VERSION ""

NS_ :

BS_:

BU_: CHUD_LS VKM_LS RCRM_LS MSM_RR_LS MSM_LR_LS CGM_LS BSM_LS VPM_LS ISRVM_LS DCAC_LS TouchPad_LS RSC_LS LVMPC_LS EOCM2B_K1_LS EOCM2A_K1_LS LCM_LS TIM_B_LS V2V_LS TCP_LS CSM_LS EOCM2B_K2_LS EOCM2A_K2_LS TIM_A_LS LVMNav_LS HFP_LS EDI_LS ARB_LS RSE_LS Dummy_LS VIS2_LS ICS_LS FCM_LS EOCM_F_LS VICM_LS AGC_LS MSM_P_LS OTIM_LS HVSM_R_LS HVSM_F_LS DVB_T_LS SBZA_R_LS PSD_R_LS PSD_L_LS UHP_Low UPA_LS STC_LS SBZA_L_LS PTM_LS ONSTAR_LS APA_LS TestTool_LS PHS_LS PDIM_LS CHM_LS RSA_LS AMP_LS HUD_LS MSM_LS HBSM_LS SCL_LS ECC_LS RadioHead_LS PEPS_LS IPC_LS AOS_LS SDM_LS TIM_LS BCM_LS

BO_ 168 Temp_Diag_CAN_Req_LS_0A8: 8 CGM_LS
 SG_ DgnInf : 7|64@0+ (1,0) [0|1.84467440737096E+019] ""  Dummy_LS

BO_ 128 Temp_Diag_CAN_Req_LS_080: 8 Dummy_LS
 SG_ DgnInf : 7|64@0+ (1,0) [0|1.84467440737096E+019] ""  CGM_LS

BO_ 896 Temp_Diag_CAN_Resp_LS_380: 8 CGM_LS
 SG_ DgnInf : 7|64@0+ (1,0) [0|1.84467440737096E+019] ""  CGM_LS,Dummy_LS

BO_ 153 Temp_Diag_CAN_Req_LS_099: 8 CGM_LS
 SG_ DgnInf : 7|64@0+ (1,0) [0|1.84467440737096E+019] ""  Dummy_LS

BO_ 1825 VNMF_LS_721_EOCM2B_K1: 8 EOCM2B_K1_LS
 SG_ VectraSpcNWMgtD : 7|64@0+ (1,0) [0|1.84467440737096E+019] ""  CGM_LS,Dummy_LS

BO_ 1824 VNMF_LS_720_EOCM2A_K1: 8 EOCM2A_K1_LS
 SG_ VectraSpcNWMgtD : 7|64@0+ (1,0) [0|1.84467440737096E+019] ""  CGM_LS,Dummy_LS

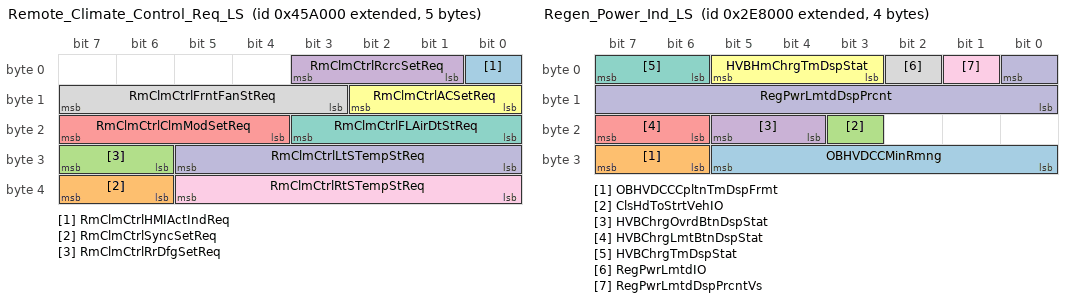
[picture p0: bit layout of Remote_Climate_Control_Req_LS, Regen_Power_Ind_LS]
BO_ 2152046592 Remote_Climate_Control_Req_LS: 5 ONSTAR_LS
 SG_ RmClmCtrlHMIActIndReq : 0|1@0+ (1,0) [0|1] ""  ECC_LS
 SG_ RmClmCtrlSyncSetReq : 39|2@0+ (1,0) [0|3] ""  ECC_LS
 SG_ RmClmCtrlRrDfgSetReq : 31|2@0+ (1,0) [0|3] ""  ECC_LS
 SG_ RmClmCtrlRcrcSetReq : 3|3@0+ (1,0) [0|7] ""  ECC_LS
 SG_ RmClmCtrlClmModSetReq : 23|4@0+ (1,0) [0|15] ""  ECC_LS
 SG_ RmClmCtrlACSetReq : 10|3@0+ (1,0) [0|7] ""  ECC_LS
 SG_ RmClmCtrlFLAirDtStReq : 19|4@0+ (1,0) [0|15] ""  ECC_LS
 SG_ RmClmCtrlFrntFanStReq : 15|5@0+ (1,0) [0|31] ""  ECC_LS
 SG_ RmClmCtrlRtSTempStReq : 37|6@0+ (1,0) [0|63] ""  ECC_LS
 SG_ RmClmCtrlLtSTempStReq : 29|6@0+ (1,0) [0|63] ""  ECC_LS

BO_ 2152030208 Tuner_Frequency_Request_LS: 8 ONSTAR_LS
 SG_ TnrFrqChnlReq : 15|56@0+ (1,0) [0|1] ""  CGM_LS,CSM_LS,RadioHead_LS
 SG_ TnrFrqBndReq : 3|4@0+ (1,0) [0|15] ""  CGM_LS,CSM_LS,RadioHead_LS

BO_ 2150531072 Regen_Power_Ind_LS: 4 VICM_LS
 SG_ OBHVDCCMinRmng : 29|6@0+ (1,0) [0|63] ""  CGM_LS,IPC_LS,RadioHead_LS
 SG_ OBHVDCCCpltnTmDspFrmt : 31|2@0+ (1,0) [0|3] ""  IPC_LS,CGM_LS,RadioHead_LS
 SG_ ClsHdToStrtVehIO : 19|1@0+ (1,0) [0|1] ""  CGM_LS,IPC_LS
 SG_ HVBChrgOvrdBtnDspStat : 21|2@0+ (1,0) [0|3] ""  CGM_LS,CSM_LS,RadioHead_LS
 SG_ HVBChrgLmtBtnDspStat : 23|2@0+ (1,0) [0|3] ""  CGM_LS,CSM_LS,RadioHead_LS
 SG_ HVBHmChrgTmDspStat : 5|3@0+ (1,0) [0|7] ""  CGM_LS,CSM_LS,RadioHead_LS
 SG_ HVBChrgTmDspStat : 7|2@0+ (1,0) [0|3] ""  CGM_LS,CSM_LS,RadioHead_LS
 SG_ RegPwrLmtdIO : 2|1@0+ (1,0) [0|1] ""  CGM_LS,IPC_LS
 SG_ RegPwrLmtdDspPrcntVs : 1|1@0+ (1,0) [0|1] ""  CGM_LS,IPC_LS
 SG_ RegPwrLmtdDspPrcnt : 0|9@0- (0.392157,0) [-100.392192|100.000035] "%"  CGM_LS,IPC_LS

BO_ 2151833600 Heated_Wndshild_CstmrIhbt_Req_LS: 1 BCM_LS
 SG_ HtdFrntWSDispReq : 7|2@0+ (1,0) [0|3] ""  CGM_LS,ECC_LS
 SG_ HtdFrntWSCustRqIhbt : 5|1@0+ (1,0) [0|1] ""  CGM_LS,ECC_LS

BO_ 2151817216 Heated_Wndshild_Cstmr_Req_LS: 1 ECC_LS
 SG_ HtdFrntWSCustRq : 7|1@0+ (1,0) [0|1] ""  CGM_LS,BCM_LS

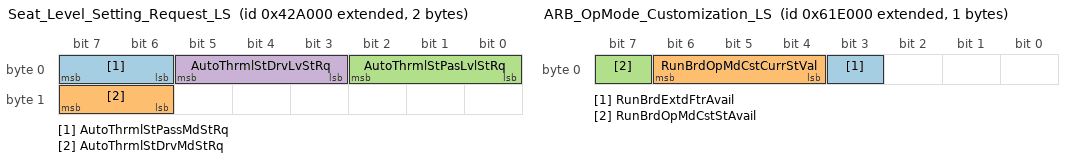
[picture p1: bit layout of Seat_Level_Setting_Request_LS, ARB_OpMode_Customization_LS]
BO_ 2151849984 Seat_Level_Setting_Request_LS: 2 ECC_LS
 SG_ AutoThrmlStPassMdStRq : 7|2@0+ (1,0) [0|3] ""  CGM_LS,BCM_LS
 SG_ AutoThrmlStDrvMdStRq : 15|2@0+ (1,0) [0|3] ""  CGM_LS,BCM_LS
 SG_ AutoThrmlStPasLvlStRq : 2|3@0+ (1,0) [0|7] ""  CGM_LS,BCM_LS
 SG_ AutoThrmlStDrvLvStRq : 5|3@0+ (1,0) [0|7] ""  CGM_LS,BCM_LS

BO_ 2153897984 ARB_OpMode_Customization_LS: 1 ARB_LS
 SG_ RunBrdExtdFtrAvail : 3|1@0+ (1,0) [0|1] ""  CGM_LS,CSM_LS,RadioHead_LS
 SG_ RunBrdOpMdCstCurrStVal : 6|3@0+ (1,0) [0|7] ""  CGM_LS,CSM_LS,RadioHead_LS
 SG_ RunBrdOpMdCstStAvail : 7|1@0+ (1,0) [0|1] ""  CGM_LS,CSM_LS,RadioHead_LS

BO_ 936 Temp_Diag_CAN_Resp_LS_3A8: 8 Dummy_LS
 SG_ DgnInf : 7|64@0+ (1,0) [0|1.84467440737096E+019] ""  CGM_LS

BO_ 856 Temp_Diag_CAN_Resp_LS_358: 8 Dummy_LS
 SG_ DgnInf : 7|64@0+ (1,0) [0|1.84467440737096E+019] ""  CGM_LS

BO_ 872 Temp_Diag_CAN_Resp_LS_368: 8 Dummy_LS
 SG_ DgnInf : 7|64@0+ (1,0) [0|1.84467440737096E+019] ""  CGM_LS

BO_ 864 Temp_Diag_CAN_Resp_LS_360: 8 CGM_LS
 SG_ DgnInf : 7|64@0+ (1,0) [0|1.84467440737096E+019] ""  CGM_LS,Dummy_LS

BO_ 921 Temp_Diag_CAN_Resp_LS_399: 8 Dummy_LS
 SG_ DgnInf : 7|64@0+ (1,0) [0|1.84467440737096E+019] ""  CGM_LS

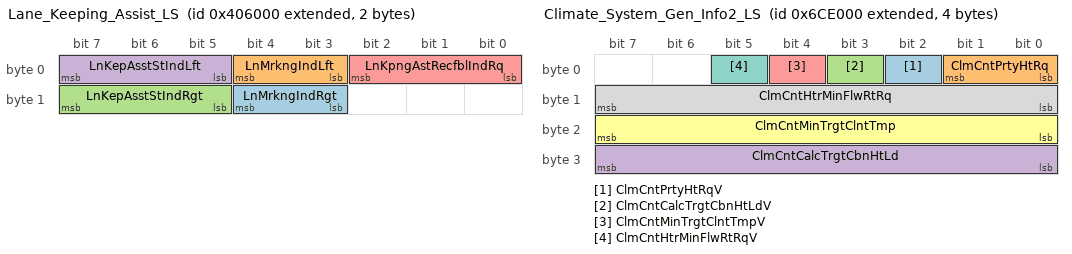
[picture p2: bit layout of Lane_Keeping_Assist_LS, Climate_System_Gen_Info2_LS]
BO_ 2151702528 Lane_Keeping_Assist_LS: 2 EOCM_F_LS
 SG_ LnMrkngIndRgt : 12|2@0+ (1,0) [0|3] ""  IPC_LS,CGM_LS
 SG_ LnMrkngIndLft : 4|2@0+ (1,0) [0|3] ""  IPC_LS,CGM_LS
 SG_ LnKepAsstStIndRgt : 15|3@0+ (1,0) [0|7] ""  IPC_LS,CGM_LS
 SG_ LnKepAsstStIndLft : 7|3@0+ (1,0) [0|7] ""  IPC_LS,CGM_LS
 SG_ LnKpngAstRecfblIndRq : 2|3@0+ (1,0) [0|7] ""  CGM_LS,IPC_LS

BO_ 2154618880 Climate_System_Gen_Info2_LS: 4 ECC_LS
 SG_ ClmCntPrtyHtRqV : 2|1@0+ (1,0) [0|1] ""  CGM_LS,BCM_LS
 SG_ ClmCntPrtyHtRq : 1|2@0+ (1,0) [0|3] ""  CGM_LS,BCM_LS
 SG_ ClmCntCalcTrgtCbnHtLdV : 3|1@0+ (1,0) [0|1] ""  CGM_LS,BCM_LS
 SG_ ClmCntCalcTrgtCbnHtLd : 31|8@0+ (0.12549,0) [0|32] "kW"  CGM_LS,BCM_LS
 SG_ ClmCntMinTrgtClntTmpV : 4|1@0+ (1,0) [0|1] ""  CGM_LS,BCM_LS
 SG_ ClmCntMinTrgtClntTmp : 23|8@0+ (0.39216,0) [0|100.0008] "degC"  CGM_LS,BCM_LS
 SG_ ClmCntHtrMinFlwRtRqV : 5|1@0+ (1,0) [0|1] ""  CGM_LS,BCM_LS
 SG_ ClmCntHtrMinFlwRtRq : 15|8@0+ (0.25098,0) [0|63.9999] "l/min"  CGM_LS,BCM_LS

BO_ 2156986368 PassPhrase_3_AMM_LS: 8 CGM_LS
 SG_ WiFiPssPhrsDgts17to24_Mp : 7|64@0+ (1,0) [0|0] ""  EOCM2A_K1_LS,EOCM2B_K1_LS

BO_ 2156978176 PassPhrase_2_AMM_LS: 8 CGM_LS
 SG_ WiFiPssPhrsDgts9to16_Mp : 7|64@0+ (1,0) [0|0] ""  EOCM2A_K1_LS,EOCM2B_K1_LS

BO_ 2156969984 PassPhrase_1_AMM_LS: 8 CGM_LS
 SG_ WiFiPssPhrsDgts1to8_Mp : 7|64@0+ (1,0) [0|0] ""  EOCM2A_K1_LS,EOCM2B_K1_LS

BO_ 2150236160 Unlock_Key_Store_Crypt_2_LS: 8 BCM_LS
 SG_ UlckKyStrCrptoDt2M : 4|1@0+ (1,0) [0|1] ""  CGM_LS,CSM_LS
 SG_ UlckKyStrCrptoDt2 : 3|60@0+ (1,0) [0|1.15292150460685E+018] ""  CGM_LS,CSM_LS

BO_ 2150170624 Unlock_Key_Store_Crypt_1_LS: 8 BCM_LS
 SG_ UlckKyStrCrptoDt1M : 4|1@0+ (1,0) [0|1] ""  CGM_LS,CSM_LS
 SG_ UlckKyStrCrptoDt1 : 3|60@0+ (1,0) [0|1.15292150460685E+018] ""  CGM_LS,CSM_LS

BO_ 2155126784 Drvr_Seat_Rearward_Movmnt_LS: 1 MSM_LS
 SG_ DrvrSetRrwrdMvmnt : 7|3@0+ (1,0) [0|7] ""  CGM_LS,MSM_LR_LS

BO_ 2154725376 Auxiliary_Heater_LS: 1 ECC_LS
 SG_ AuxHtrAtv378 : 6|1@0+ (1,0) [0|1] ""  RSC_LS,ECC_LS,CGM_LS
 SG_ AuxHtrRq : 7|1@0+ (1,0) [0|1] ""  RSC_LS,ECC_LS,CGM_LS

BO_ 2157051904 WiFi_Station_AMM_LS: 5 EOCM2A_K2_LS
 SG_ WSMR_WiFiStnMpMACAddr : 15|32@0+ (1,0) [0|4294967295] ""  CSM_LS,ONSTAR_LS,CGM_LS
 SG_ WSMR_WiFiAssnReq : 1|2@0+ (1,0) [0|3] ""  CSM_LS,ONSTAR_LS,CGM_LS

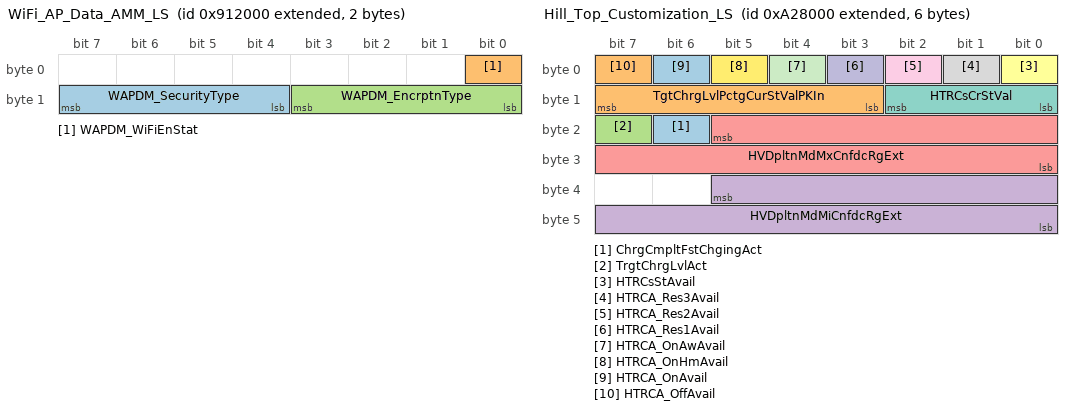
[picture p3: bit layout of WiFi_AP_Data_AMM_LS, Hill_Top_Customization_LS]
BO_ 2156994560 WiFi_AP_Data_AMM_LS: 2 CGM_LS
 SG_ WAPDM_SecurityType : 15|4@0+ (1,0) [0|15] ""  EOCM2A_K1_LS,EOCM2B_K1_LS
 SG_ WAPDM_WiFiEnStat : 0|1@0+ (1,0) [0|1] ""  EOCM2A_K1_LS,EOCM2B_K1_LS
 SG_ WAPDM_EncrptnType : 11|4@0+ (1,0) [0|15] ""  EOCM2A_K1_LS,EOCM2B_K1_LS

BO_ 2158133248 Hill_Top_Customization_LS: 6 VICM_LS
 SG_ ChrgCmpltFstChgingAct : 22|1@0+ (1,0) [0|1] ""  CSM_LS,CGM_LS,RadioHead_LS,IPC_LS
 SG_ TgtChrgLvlPctgCurStValPKIn : 15|5@0+ (1,0) [0|20] ""  CGM_LS,IPC_LS
 SG_ TrgtChrgLvlAct : 23|1@0+ (1,0) [0|1] ""  CGM_LS,IPC_LS
 SG_ HVDpltnMdMiCnfdcRgExt : 37|14@0+ (0.1,0) [0|1638.3] "km"  CGM_LS,IPC_LS
 SG_ HVDpltnMdMxCnfdcRgExt : 21|14@0+ (0.1,0) [0|1638.3] "km"  CGM_LS,IPC_LS
 SG_ HTRCsStAvail : 0|1@0+ (1,0) [0|1] ""  CGM_LS,CSM_LS,RadioHead_LS
 SG_ HTRCsCrStVal : 10|3@0+ (1,0) [0|7] ""  CGM_LS,CSM_LS,RadioHead_LS
 SG_ HTRCA_Res3Avail : 1|1@0+ (1,0) [0|1] ""  CGM_LS,CSM_LS,RadioHead_LS
 SG_ HTRCA_Res2Avail : 2|1@0+ (1,0) [0|1] ""  CGM_LS,CSM_LS,RadioHead_LS
 SG_ HTRCA_Res1Avail : 3|1@0+ (1,0) [0|1] ""  CGM_LS,CSM_LS,RadioHead_LS
 SG_ HTRCA_OnAwAvail : 4|1@0+ (1,0) [0|1] ""  CGM_LS,CSM_LS,RadioHead_LS
 SG_ HTRCA_OnHmAvail : 5|1@0+ (1,0) [0|1] ""  CGM_LS,CSM_LS,RadioHead_LS
 SG_ HTRCA_OnAvail : 6|1@0+ (1,0) [0|1] ""  CGM_LS,CSM_LS,RadioHead_LS
 SG_ HTRCA_OffAvail : 7|1@0+ (1,0) [0|1] ""  CGM_LS,CSM_LS,RadioHead_LS

BO_ 2154651648 Telematics_Audio_Control_LS: 1 CSM_LS
 SG_ TAC_AudConctOutcm : 3|4@0+ (1,0) [0|15] ""  VPM_LS,CGM_LS,TCP_LS
 SG_ TAC_AudChConctStat : 7|4@0+ (1,0) [0|15] ""  VPM_LS,CGM_LS,TCP_LS

BO_ 2154635264 Telematics_Audio_Request_LS: 1 TCP_LS
 SG_ TAR_AudSrcStat : 3|4@0+ (1,0) [0|15] ""  VPM_LS,CGM_LS,CSM_LS
 SG_ TAR_AudConctReq : 7|4@0+ (1,0) [0|15] ""  VPM_LS,CGM_LS,CSM_LS

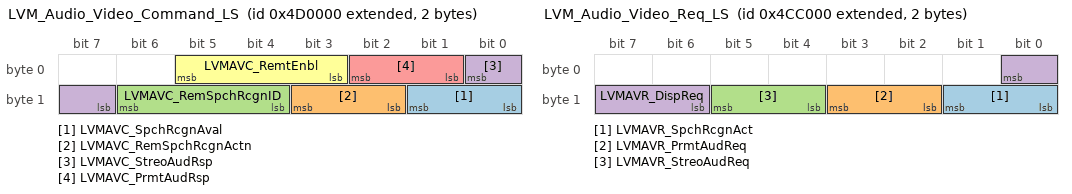
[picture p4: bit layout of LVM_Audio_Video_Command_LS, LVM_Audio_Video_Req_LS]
BO_ 2152529920 LVM_Audio_Video_Command_LS: 2 CSM_LS
 SG_ LVMAVC_SpchRcgnAval : 9|2@0+ (1,0) [0|3] ""  CGM_LS,LVMPC_LS,LVMNav_LS
 SG_ LVMAVC_RemSpchRcgnActn : 11|2@0+ (1,0) [0|3] ""  CGM_LS,LVMPC_LS,LVMNav_LS
 SG_ LVMAVC_RemSpchRcgnID : 14|3@0+ (1,0) [0|7] ""  CGM_LS,LVMPC_LS,LVMNav_LS
 SG_ LVMAVC_StreoAudRsp : 0|2@0+ (1,0) [0|3] ""  CGM_LS,LVMPC_LS,LVMNav_LS
 SG_ LVMAVC_PrmtAudRsp : 2|2@0+ (1,0) [0|3] ""  CGM_LS,LVMPC_LS,LVMNav_LS
 SG_ LVMAVC_RemtEnbl : 5|3@0+ (1,0) [0|7] ""  CGM_LS,LVMPC_LS,LVMNav_LS

BO_ 2152513536 LVM_Audio_Video_Req_LS: 2 LVMNav_LS
 SG_ LVMAVR_SpchRcgnAct : 9|2@0+ (1,0) [0|3] ""  CGM_LS,CSM_LS
 SG_ LVMAVR_PrmtAudReq : 11|2@0+ (1,0) [0|3] ""  CGM_LS,CSM_LS
 SG_ LVMAVR_StreoAudReq : 13|2@0+ (1,0) [0|3] ""  CGM_LS,CSM_LS
 SG_ LVMAVR_DispReq : 0|3@0+ (1,0) [0|7] ""  CGM_LS,CSM_LS

BO_ 2154889216 Cluster_HMI_Animation_Req_LS: 1 CSM_LS
 SG_ RSIHMIAnmReq : 4|3@0+ (1,0) [0|7] ""  CGM_LS,RSE_LS
 SG_ ClstrHMIAnmReq : 7|3@0+ (1,0) [0|7] ""  CGM_LS

BO_ 2154872832 Infotainment_Activation_Req_LS: 1 TCP_LS
 SG_ RmRflshUpdtAvail : 6|1@0+ (1,0) [0|1] ""  CGM_LS,CSM_LS
 SG_ InfoActvnReq : 7|1@0+ (1,0) [0|1] ""  IPC_LS,CGM_LS,CSM_LS

BO_ 2156961792 SSID_AMM_3_LS: 8 CGM_LS
 SG_ WiFiSSIDDgts17to24_Mp : 7|64@0+ (1,0) [0|0] ""  EOCM2A_K1_LS,EOCM2B_K1_LS

BO_ 2154569728 Infotainment_System_State_LS: 1 CSM_LS
 SG_ InfotnmntSysSt : 7|5@0+ (1,0) [0|31] ""  VICM_LS,CHUD_LS,TCP_LS,TouchPad_LS,RSC_LS,LVMPC_LS,LVMNav_LS,RSE_LS,ICS_LS,AMP_LS

BO_ 2151931904 Custom_Launch_Ctrl_LS: 8 BCM_LS
 SG_ FourWhlDrvIdReqExtRng : 59|4@0+ (1,0) [0|15] ""  CGM_LS,IPC_LS
 SG_ LnchCtrlTmrVal : 35|4@0+ (1,0) [0|15] ""  CGM_LS,IPC_LS
 SG_ LnchCtrlBrkPresVal : 47|4@0+ (10,0) [0|150] "%"  CGM_LS,IPC_LS
 SG_ FuelMdTrnstnIndReq : 63|4@0+ (1,0) [0|15] ""  CGM_LS,IPC_LS
 SG_ BiFuelRflGaslinIndReq : 42|3@0+ (1,0) [0|7] ""  CGM_LS,IPC_LS
 SG_ AutoShtdwnTmr : 55|8@0+ (1,0) [0|255] "min"  CGM_LS,IPC_LS
 SG_ AutoShtdwnIO : 43|1@0+ (1,0) [0|1] ""  CGM_LS,IPC_LS
 SG_ TCSTempDsblReqIO : 24|1@0+ (1,0) [0|1] ""  IPC_LS,CGM_LS
 SG_ VehStbCmptvMdCstAvl : 25|1@0+ (1,0) [0|1] ""  IPC_LS,CGM_LS
 SG_ VehStbEnmntCstAvl : 26|1@0+ (1,0) [0|1] ""  IPC_LS,CGM_LS
 SG_ TCSysCstAvl : 27|1@0+ (1,0) [0|1] ""  IPC_LS,CGM_LS
 SG_ VehStbCmptvMdCurSt : 28|1@0+ (1,0) [0|1] ""  IPC_LS,CGM_LS
 SG_ VehStbEnhmntCurSt : 36|1@0+ (1,0) [0|1] ""  IPC_LS,CGM_LS
 SG_ TCSysCurSt : 37|1@0+ (1,0) [0|1] ""  IPC_LS,CGM_LS
 SG_ TracAndStbScrnCnfg : 39|2@0+ (1,0) [0|3] ""  IPC_LS,CGM_LS
 SG_ ElctShfPriLtdPerfMdIO : 29|1@0+ (1,0) [0|1] ""  CGM_LS,IPC_LS
 SG_ LnchCtrlWhlSlpStat : 7|5@0+ (1,0) [0|31] ""  IPC_LS,CGM_LS
 SG_ LnchCtrlMdStat : 2|3@0+ (1,0) [0|7] ""  IPC_LS,CGM_LS
 SG_ LnchCtrlEngRPMStat : 15|6@0+ (1,0) [0|63] ""  IPC_LS,CGM_LS
 SG_ RegVltCtlEngyRcvryAct : 30|1@0+ (1,0) [0|1] ""  CGM_LS,IPC_LS
 SG_ VehSpdCntlSystmType : 20|3@0+ (1,0) [0|7] ""  V2V_LS,CGM_LS,IPC_LS
 SG_ ACCSysSltdMdDispIO : 31|1@0+ (1,0) [0|1] ""  V2V_LS,CGM_LS,IPC_LS
 SG_ ACCSysSltdMd : 17|2@0+ (1,0) [0|3] ""  V2V_LS,CGM_LS,IPC_LS
 SG_ PTExPrtclFltWrng3IO : 8|1@0+ (1,0) [0|1] ""  IPC_LS,CGM_LS
 SG_ PTExPartFltManRegStat : 23|3@0+ (1,0) [0|7] ""  IPC_LS,CGM_LS
 SG_ AWDRecmndIO : 9|1@0+ (1,0) [0|1] ""  CGM_LS,IPC_LS

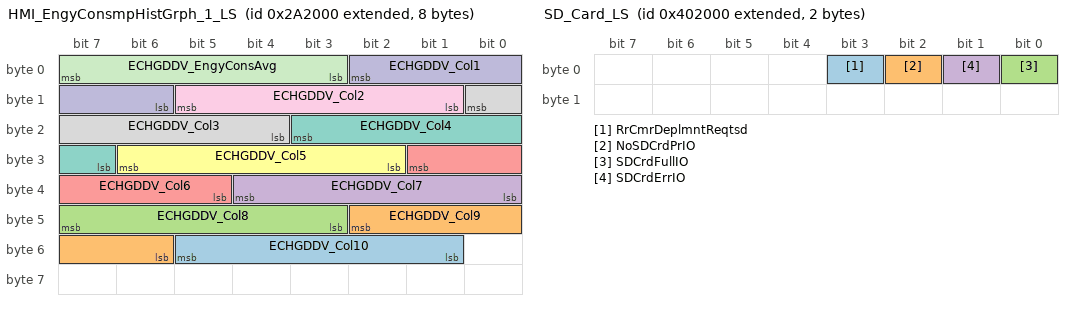
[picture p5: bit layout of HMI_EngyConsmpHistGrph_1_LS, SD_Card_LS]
BO_ 2150244352 HMI_EngyConsmpHistGrph_1_LS: 8 VICM_LS
 SG_ ECHGDDV_Col10 : 53|5@0+ (1,0) [0|31] ""  CGM_LS,CSM_LS,RadioHead_LS
 SG_ ECHGDDV_Col9 : 42|5@0+ (1,0) [0|31] ""  CGM_LS,CSM_LS,RadioHead_LS
 SG_ ECHGDDV_Col8 : 47|5@0+ (1,0) [0|31] ""  CGM_LS,CSM_LS,RadioHead_LS
 SG_ ECHGDDV_Col7 : 36|5@0+ (1,0) [0|31] ""  CGM_LS,CSM_LS,RadioHead_LS
 SG_ ECHGDDV_Col6 : 25|5@0+ (1,0) [0|31] ""  CGM_LS,CSM_LS,RadioHead_LS
 SG_ ECHGDDV_Col5 : 30|5@0+ (1,0) [0|31] ""  CGM_LS,CSM_LS,RadioHead_LS
 SG_ ECHGDDV_Col4 : 19|5@0+ (1,0) [0|31] ""  CGM_LS,CSM_LS,RadioHead_LS
 SG_ ECHGDDV_Col3 : 8|5@0+ (1,0) [0|31] ""  CGM_LS,CSM_LS,RadioHead_LS
 SG_ ECHGDDV_Col2 : 13|5@0+ (1,0) [0|31] ""  CGM_LS,CSM_LS,RadioHead_LS
 SG_ ECHGDDV_Col1 : 2|5@0+ (1,0) [0|31] ""  CGM_LS,CSM_LS,RadioHead_LS
 SG_ ECHGDDV_EngyConsAvg : 7|5@0+ (1,0) [0|31] ""  CGM_LS,CSM_LS,RadioHead_LS

BO_ 2156953600 SSID_AMM_2_LS: 8 CGM_LS
 SG_ WiFiSSIDDgts9to16_Mp : 7|64@0+ (1,0) [0|0] ""  EOCM2A_K1_LS,EOCM2B_K1_LS

BO_ 2151686144 SD_Card_LS: 2 VPM_LS
 SG_ RrCmrDeplmntReqtsd : 3|1@0+ (1,0) [0|1] ""  RCRM_LS,CGM_LS
 SG_ NoSDCrdPrIO : 2|1@0+ (1,0) [0|1] ""  CGM_LS,CSM_LS,RadioHead_LS,IPC_LS
 SG_ SDCrdFullIO : 0|1@0+ (1,0) [0|1] ""  CGM_LS,CSM_LS,RadioHead_LS,IPC_LS
 SG_ SDCrdErrIO : 1|1@0+ (1,0) [0|1] ""  CGM_LS,CSM_LS,RadioHead_LS,IPC_LS

BO_ 2155028480 Lane_Change_Threat_LS: 2 APA_LS
 SG_ RtLnChngThrtAprchSpd : 15|8@0- (1,0) [-128|127] "km/h"  CGM_LS,BCM_LS,HBSM_LS
 SG_ RgtLnChgThrt : 0|1@0+ (1,0) [0|1] ""  CGM_LS,VIS2_LS,BCM_LS,HBSM_LS,FCM_LS,EOCM_F_LS

BO_ 2151915520 HMI_Display_LS: 8 BCM_LS
 SG_ ESPTrnVehOffFrPrkIO : 44|1@0+ (1,0) [0|1] ""  IPC_LS,CGM_LS
 SG_ ESPTrnsCtlrMalfIO : 45|1@0+ (1,0) [0|1] ""  IPC_LS,CGM_LS
 SG_ ESPShfToDrvTryAgnIO : 43|1@0+ (1,0) [0|1] ""  IPC_LS,CGM_LS
 SG_ ElcShfPriTwoGrsSlInRq : 47|2@0+ (1,0) [0|3] ""  IPC_LS,CGM_LS
 SG_ ESPRedSpdReqShftIO : 42|1@0+ (1,0) [0|1] ""  CGM_LS,IPC_LS
 SG_ DrvEffInd : 39|8@0- (0.78125,0) [-100|99.21875] "%"  CGM_LS,IPC_LS
 SG_ EngIntkArBstPrExtRngV : 14|1@0+ (1,0) [0|1] ""  CGM_LS,IPC_LS
 SG_ EngIntkArBstPrExtRng : 8|9@0+ (1,-110) [-110|401] "kPa"  IPC_LS,CGM_LS
 SG_ ElecShfRngDispRCExtd : 27|4@0+ (1,0) [0|15] ""  IPC_LS,CGM_LS
 SG_ ElecShfRngDisp : 31|4@0+ (1,0) [0|15] ""  IPC_LS,CGM_LS
 SG_ ESPTransMalfIO : 9|1@0+ (1,0) [0|1] ""  IPC_LS,CGM_LS
 SG_ ESPRngInvldReqIO : 10|1@0+ (1,0) [0|1] ""  IPC_LS,CGM_LS
 SG_ ESPPrkInvldReqIO : 11|1@0+ (1,0) [0|1] ""  IPC_LS,CGM_LS
 SG_ ESPHldShfLvrToEngRgIO : 12|1@0+ (1,0) [0|1] ""  IPC_LS,CGM_LS
 SG_ ESPDrvrPrkIlkSftAtdIO : 13|1@0+ (1,0) [0|1] ""  IPC_LS,CGM_LS
 SG_ ESPDrvrIlkShfAtdIO : 7|1@0+ (1,0) [0|1] ""  IPC_LS,CGM_LS
 SG_ AHAct : 6|1@0+ (1,0) [0|1] ""  CGM_LS,IPC_LS
 SG_ AHEnbld : 5|1@0+ (1,0) [0|1] ""  CGM_LS,IPC_LS
 SG_ ShfToPrkBfExtngIO : 4|1@0+ (1,0) [0|1] ""  CGM_LS,IPC_LS
 SG_ AHServcIO : 3|1@0+ (1,0) [0|1] ""  CGM_LS,IPC_LS
 SG_ AHAppBrkPedlIO : 2|1@0+ (1,0) [0|1] ""  CGM_LS,IPC_LS
 SG_ AHDisbldStbltIO : 1|1@0+ (1,0) [0|1] ""  CGM_LS,IPC_LS
 SG_ AHDisbldDrOpnIO : 0|1@0+ (1,0) [0|1] ""  CGM_LS,IPC_LS
 SG_ ElcTransRngSlctVDA : 15|1@0+ (1,0) [0|1] ""  IPC_LS,CGM_LS

BO_ 2150129664 Hitch_Park_Brake_Assist_LS: 1 VPM_LS
 SG_ HtVwAutnmsEPBAplyReqd : 7|1@0+ (1,0) [0|1] ""  BCM_LS

BO_ 2154299392 Car_Sharing_Info1_LS: 1 VKM_LS
 SG_ CrShrngVehChlngReq : 7|1@0+ (1,0) [0|1] ""  BCM_LS

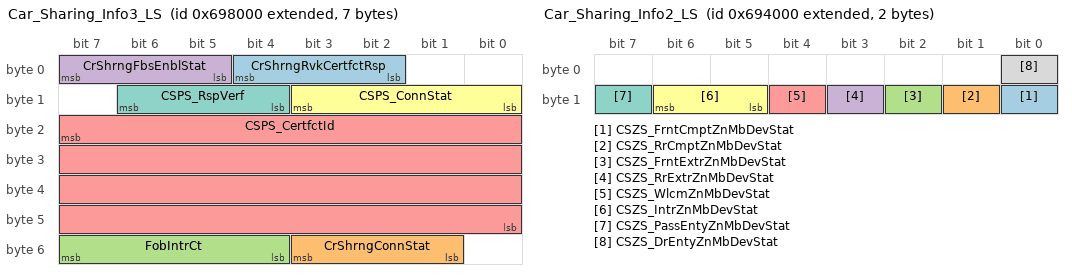
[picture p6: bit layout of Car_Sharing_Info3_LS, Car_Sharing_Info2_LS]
BO_ 2154397696 Car_Sharing_Info3_LS: 7 BCM_LS
 SG_ CrShrngRvkCertfctRsp : 4|3@0+ (1,0) [0|7] ""  CGM_LS,TCP_LS,ONSTAR_LS
 SG_ CrShrngConnStat : 51|3@0+ (1,0) [0|7] ""  CGM_LS,VKM_LS
 SG_ FobIntrCt : 55|4@0+ (1,0) [0|15] ""  TCP_LS,ONSTAR_LS,CGM_LS
 SG_ CrShrngFbsEnblStat : 7|3@0+ (1,0) [0|7] ""  PEPS_LS,VKM_LS,TCP_LS,ONSTAR_LS,CGM_LS
 SG_ CSPS_CertfctId : 23|32@0+ (1,0) [0|4294967295] ""  CGM_LS,VKM_LS
 SG_ CSPS_ConnStat : 11|4@0+ (1,0) [0|15] ""  CGM_LS,VKM_LS
 SG_ CSPS_RspVerf : 14|3@0+ (1,0) [0|7] ""  CGM_LS,VKM_LS

BO_ 2154553344 Car_sharing_Encrypt_Secrt_Rsp_LS: 8 VKM_LS
 SG_ CrShrngEncrpScrtRsp : 7|64@0+ (1,0) [0|1.84467440737096E+019] ""  BCM_LS

BO_ 2154536960 Car_sharing_Encrypt_Secret_LS: 8 BCM_LS
 SG_ CrShrngEncrpScrt : 7|64@0+ (1,0) [0|1.84467440737096E+019] ""  CGM_LS,VKM_LS

BO_ 2154545152 Car_Shar_Intrmdt_CA_Cert_Rsp_LS: 8 BCM_LS
 SG_ CrShrgIntCtftAthrtyCtftRp : 7|64@0+ (1,0) [0|1.84467440737096E+019] ""  CGM_LS,VKM_LS

BO_ 2154520576 Car_Sharing_Intrmdt_CA_Cert_LS: 8 VKM_LS
 SG_ CrShrgIntCtftAthrtyCtft : 7|64@0+ (1,0) [0|1.84467440737096E+019] ""  BCM_LS

BO_ 2154504192 Car_Sharing_User_Cert_Resp_LS: 8 BCM_LS
 SG_ CrShrngUsrCertfctRsp : 7|64@0+ (1,0) [0|1.84467440737096E+019] ""  CGM_LS,VKM_LS

BO_ 2154479616 Car_Sharing_User_Cert_LS: 8 VKM_LS
 SG_ CrShrngUsrCertfct : 7|64@0+ (1,0) [0|1.84467440737096E+019] ""  BCM_LS

BO_ 2154381312 Car_Sharing_Info2_LS: 2 VKM_LS
 SG_ CSZS_FrntCmptZnMbDevStat : 8|1@0+ (1,0) [0|1] ""  BCM_LS
 SG_ CSZS_RrCmptZnMbDevStat : 9|1@0+ (1,0) [0|1] ""  BCM_LS
 SG_ CSZS_FrntExtrZnMbDevStat : 10|1@0+ (1,0) [0|1] ""  BCM_LS
 SG_ CSZS_RrExtrZnMbDevStat : 11|1@0+ (1,0) [0|1] ""  BCM_LS
 SG_ CSZS_WlcmZnMbDevStat : 12|1@0+ (1,0) [0|1] ""  BCM_LS
 SG_ CSZS_IntrZnMbDevStat : 14|2@0+ (1,0) [0|3] ""  BCM_LS
 SG_ CSZS_PassEntyZnMbDevStat : 15|1@0+ (1,0) [0|1] ""  BCM_LS
 SG_ CSZS_DrEntyZnMbDevStat : 0|1@0+ (1,0) [0|1] ""  BCM_LS

BO_ 2152153088 Right_Rear_Seat_Display_Stats_LS: 6 MSM_RR_LS
 SG_ RRSCDS_UnsdRsrvd : 42|3@0+ (1,0) [0|7] ""  RSE_LS,CGM_LS,CSM_LS,RadioHead_LS
 SG_ RRSCDS_DispReq : 43|1@0+ (1,0) [0|1] ""  RSE_LS,CGM_LS,CSM_LS,RadioHead_LS
 SG_ RRSCDS_DispSz : 45|2@0+ (1,0) [0|3] ""  RSE_LS,CGM_LS,CSM_LS,RadioHead_LS
 SG_ RRSCDS_CshLgAdjFdRr : 47|2@0+ (1,0) [0|3] ""  RSE_LS,CGM_LS,CSM_LS,RadioHead_LS
 SG_ RRSCDS_BkCshBlstInOt : 34|3@0+ (1,0) [0|7] ""  RSE_LS,CGM_LS,CSM_LS,RadioHead_LS
 SG_ RRSCDS_CshBlstrInOut : 36|2@0+ (1,0) [0|3] ""  RSE_LS,CGM_LS,CSM_LS,RadioHead_LS
 SG_ RRSCDS_BkBlstrInOut : 38|2@0+ (1,0) [0|3] ""  RSE_LS,CGM_LS,CSM_LS,RadioHead_LS
 SG_ RRSCDS_LmbrUDnFdRr : 25|3@0+ (1,0) [0|7] ""  RSE_LS,CGM_LS,CSM_LS,RadioHead_LS
 SG_ RRSCDS_LmbrFwdRr : 27|2@0+ (1,0) [0|3] ""  RSE_LS,CGM_LS,CSM_LS,RadioHead_LS
 SG_ RRSCDS_LmbrUpDwn : 29|2@0+ (1,0) [0|3] ""  RSE_LS,CGM_LS,CSM_LS,RadioHead_LS
 SG_ RRSCDS_UprShldrFdRr : 31|2@0+ (1,0) [0|3] ""  RSE_LS,CGM_LS,CSM_LS,RadioHead_LS
 SG_ RRSCDS_HdrstTltFwdRr : 17|2@0+ (1,0) [0|3] ""  RSE_LS,CGM_LS,CSM_LS,RadioHead_LS
 SG_ RRSCDS_HdrstWngInOt : 19|2@0+ (1,0) [0|3] ""  RSE_LS,CGM_LS,CSM_LS,RadioHead_LS
 SG_ RRSCDS_HdrstFdRrUDn : 22|3@0+ (1,0) [0|7] ""  RSE_LS,CGM_LS,CSM_LS,RadioHead_LS
 SG_ RRSCDS_HdrstFwdRrwd : 8|2@0+ (1,0) [0|3] ""  RSE_LS,CGM_LS,CSM_LS,RadioHead_LS
 SG_ RRSCDS_HdrstUpDn : 10|2@0+ (1,0) [0|3] ""  RSE_LS,CGM_LS,CSM_LS,RadioHead_LS
 SG_ RRSCDS_MassgIntsty : 13|3@0+ (1,0) [0|7] ""  RSE_LS,CGM_LS,CSM_LS,RadioHead_LS
 SG_ RRSCDS_MassgTyp : 1|4@0+ (1,0) [0|15] ""  RSE_LS,CGM_LS,CSM_LS,RadioHead_LS
 SG_ RRSCDS_Massg : 3|2@0+ (1,0) [0|3] ""  RSE_LS,CGM_LS,CSM_LS,RadioHead_LS

BO_ 2152136704 Right_Rear_Seat_Massage_LS: 8 MSM_RR_LS
 SG_ RRSMP_UnsdRsrvd : 56|1@0+ (1,0) [0|1] ""  RSE_LS,CGM_LS,CSM_LS,RadioHead_LS
 SG_ RRSMP_MaxDispVal : 59|3@0+ (1,0) [0|7] ""  RSE_LS,CGM_LS,CSM_LS,RadioHead_LS
 SG_ RRSMP_Type15 : 63|4@0+ (1,0) [0|15] ""  RSE_LS,CGM_LS,CSM_LS,RadioHead_LS
 SG_ RRSMP_Type14 : 51|4@0+ (1,0) [0|15] ""  RSE_LS,CGM_LS,CSM_LS,RadioHead_LS
 SG_ RRSMP_Type13 : 55|4@0+ (1,0) [0|15] ""  RSE_LS,CGM_LS,CSM_LS,RadioHead_LS
 SG_ RRSMP_Type12 : 43|4@0+ (1,0) [0|15] ""  RSE_LS,CGM_LS,CSM_LS,RadioHead_LS
 SG_ RRSMP_Type11 : 47|4@0+ (1,0) [0|15] ""  RSE_LS,CGM_LS,CSM_LS,RadioHead_LS
 SG_ RRSMP_Type10 : 35|4@0+ (1,0) [0|15] ""  RSE_LS,CGM_LS,CSM_LS,RadioHead_LS
 SG_ RRSMP_Type9 : 39|4@0+ (1,0) [0|15] ""  RSE_LS,CGM_LS,CSM_LS,RadioHead_LS
 SG_ RRSMP_Type8 : 27|4@0+ (1,0) [0|15] ""  RSE_LS,CGM_LS,CSM_LS,RadioHead_LS
 SG_ RRSMP_Type7 : 31|4@0+ (1,0) [0|15] ""  RSE_LS,CGM_LS,CSM_LS,RadioHead_LS
 SG_ RRSMP_Type6 : 19|4@0+ (1,0) [0|15] ""  RSE_LS,CGM_LS,CSM_LS,RadioHead_LS
 SG_ RRSMP_Type5 : 23|4@0+ (1,0) [0|15] ""  RSE_LS,CGM_LS,CSM_LS,RadioHead_LS
 SG_ RRSMP_Type4 : 11|4@0+ (1,0) [0|15] ""  RSE_LS,CGM_LS,CSM_LS,RadioHead_LS
 SG_ RRSMP_Type3 : 15|4@0+ (1,0) [0|15] ""  RSE_LS,CGM_LS,CSM_LS,RadioHead_LS
 SG_ RRSMP_Type2 : 3|4@0+ (1,0) [0|15] ""  RSE_LS,CGM_LS,CSM_LS,RadioHead_LS
 SG_ RRSMP_Type1 : 7|4@0+ (1,0) [0|15] ""  RSE_LS,CGM_LS,CSM_LS,RadioHead_LS

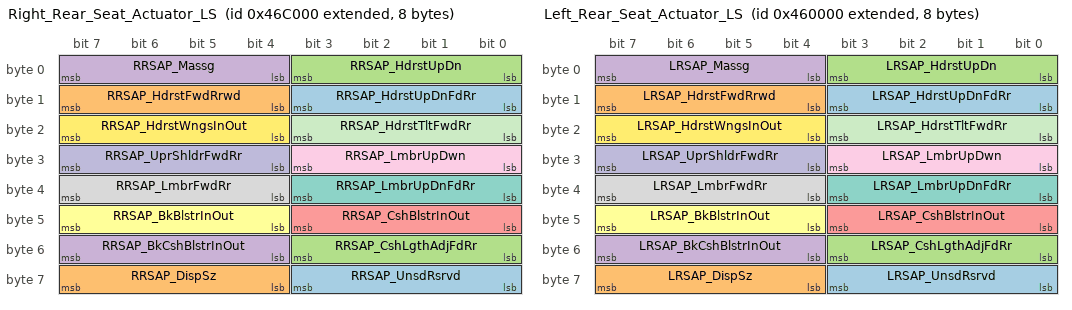
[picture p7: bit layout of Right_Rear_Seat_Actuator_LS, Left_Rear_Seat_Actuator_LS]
BO_ 2152120320 Right_Rear_Seat_Actuator_LS: 8 MSM_RR_LS
 SG_ RRSAP_UnsdRsrvd : 59|4@0+ (1,0) [0|15] ""  RSE_LS,CGM_LS,CSM_LS,RadioHead_LS
 SG_ RRSAP_DispSz : 63|4@0+ (1,0) [0|15] ""  RSE_LS,CGM_LS,CSM_LS,RadioHead_LS
 SG_ RRSAP_CshLgthAdjFdRr : 51|4@0+ (1,0) [0|15] ""  RSE_LS,CGM_LS,CSM_LS,RadioHead_LS
 SG_ RRSAP_BkCshBlstrInOut : 55|4@0+ (1,0) [0|15] ""  RSE_LS,CGM_LS,CSM_LS,RadioHead_LS
 SG_ RRSAP_CshBlstrInOut : 43|4@0+ (1,0) [0|15] ""  RSE_LS,CGM_LS,CSM_LS,RadioHead_LS
 SG_ RRSAP_BkBlstrInOut : 47|4@0+ (1,0) [0|15] ""  RSE_LS,CGM_LS,CSM_LS,RadioHead_LS
 SG_ RRSAP_LmbrUpDnFdRr : 35|4@0+ (1,0) [0|15] ""  RSE_LS,CGM_LS,CSM_LS,RadioHead_LS
 SG_ RRSAP_LmbrFwdRr : 39|4@0+ (1,0) [0|15] ""  RSE_LS,CGM_LS,CSM_LS,RadioHead_LS
 SG_ RRSAP_LmbrUpDwn : 27|4@0+ (1,0) [0|15] ""  RSE_LS,CGM_LS,CSM_LS,RadioHead_LS
 SG_ RRSAP_UprShldrFwdRr : 31|4@0+ (1,0) [0|15] ""  RSE_LS,CGM_LS,CSM_LS,RadioHead_LS
 SG_ RRSAP_HdrstTltFwdRr : 19|4@0+ (1,0) [0|15] ""  RSE_LS,CGM_LS,CSM_LS,RadioHead_LS
 SG_ RRSAP_HdrstWngsInOut : 23|4@0+ (1,0) [0|15] ""  RSE_LS,CGM_LS,CSM_LS,RadioHead_LS
 SG_ RRSAP_HdrstUpDnFdRr : 11|4@0+ (1,0) [0|15] ""  RSE_LS,CGM_LS,CSM_LS,RadioHead_LS
 SG_ RRSAP_HdrstFwdRrwd : 15|4@0+ (1,0) [0|15] ""  RSE_LS,CGM_LS,CSM_LS,RadioHead_LS
 SG_ RRSAP_HdrstUpDn : 3|4@0+ (1,0) [0|15] ""  RSE_LS,CGM_LS,CSM_LS,RadioHead_LS
 SG_ RRSAP_Massg : 7|4@0+ (1,0) [0|15] ""  RSE_LS,CGM_LS,CSM_LS,RadioHead_LS

BO_ 2152103936 Left_Rear_Seat_Display_Status_LS: 6 MSM_LR_LS
 SG_ LRSCDS_UnsdRsrvd : 42|3@0+ (1,0) [0|7] ""  RSE_LS,CGM_LS,CSM_LS,RadioHead_LS
 SG_ LRSCDS_DispReq : 43|1@0+ (1,0) [0|1] ""  RSE_LS,CGM_LS,CSM_LS,RadioHead_LS
 SG_ LRSCDS_DispSz : 45|2@0+ (1,0) [0|3] ""  RSE_LS,CGM_LS,CSM_LS,RadioHead_LS
 SG_ LRSCDS_CshLgAdjFdRr : 47|2@0+ (1,0) [0|3] ""  RSE_LS,CGM_LS,CSM_LS,RadioHead_LS
 SG_ LRSCDS_BkCshBlstInOt : 34|3@0+ (1,0) [0|7] ""  RSE_LS,CGM_LS,CSM_LS,RadioHead_LS
 SG_ LRSCDS_CshBlstrInOut : 36|2@0+ (1,0) [0|3] ""  RSE_LS,CGM_LS,CSM_LS,RadioHead_LS
 SG_ LRSCDS_BkBlstrInOut : 38|2@0+ (1,0) [0|3] ""  RSE_LS,CGM_LS,CSM_LS,RadioHead_LS
 SG_ LRSCDS_LmbrUDnFdRr : 25|3@0+ (1,0) [0|7] ""  RSE_LS,CGM_LS,CSM_LS,RadioHead_LS
 SG_ LRSCDS_LmbrFwdRr : 27|2@0+ (1,0) [0|3] ""  RSE_LS,CGM_LS,CSM_LS,RadioHead_LS
 SG_ LRSCDS_LmbrUpDwn : 29|2@0+ (1,0) [0|3] ""  RSE_LS,CGM_LS,CSM_LS,RadioHead_LS
 SG_ LRSCDS_UprShldrFdRr : 31|2@0+ (1,0) [0|3] ""  RSE_LS,CGM_LS,CSM_LS,RadioHead_LS
 SG_ LRSCDS_HdrstTltFwdRr : 17|2@0+ (1,0) [0|3] ""  RSE_LS,CGM_LS,CSM_LS,RadioHead_LS
 SG_ LRSCDS_HdrstWngInOt : 19|2@0+ (1,0) [0|3] ""  RSE_LS,CGM_LS,CSM_LS,RadioHead_LS
 SG_ LRSCDS_HdrstFdRrUDn : 22|3@0+ (1,0) [0|7] ""  RSE_LS,CGM_LS,CSM_LS,RadioHead_LS
 SG_ LRSCDS_HdrstFwdRrwd : 8|2@0+ (1,0) [0|3] ""  RSE_LS,CGM_LS,CSM_LS,RadioHead_LS
 SG_ LRSCDS_HdrstUpDn : 10|2@0+ (1,0) [0|3] ""  RSE_LS,CGM_LS,CSM_LS,RadioHead_LS
 SG_ LRSCDS_MassgIntsty : 13|3@0+ (1,0) [0|7] ""  RSE_LS,CGM_LS,CSM_LS,RadioHead_LS
 SG_ LRSCDS_MassgTyp : 1|4@0+ (1,0) [0|15] ""  RSE_LS,CGM_LS,CSM_LS,RadioHead_LS
 SG_ LRSCDS_Massg : 3|2@0+ (1,0) [0|3] ""  RSE_LS,CGM_LS,CSM_LS,RadioHead_LS

BO_ 2152087552 Left_Rear_Seat_Massage_LS: 8 MSM_LR_LS
 SG_ LRSMP_UnsdRsrvd : 56|1@0+ (1,0) [0|1] ""  RSE_LS,CGM_LS,CSM_LS,RadioHead_LS
 SG_ LRSMP_MaxDispVal : 59|3@0+ (1,0) [0|7] ""  RSE_LS,CGM_LS,CSM_LS,RadioHead_LS
 SG_ LRSMP_Type15 : 63|4@0+ (1,0) [0|15] ""  RSE_LS,CGM_LS,CSM_LS,RadioHead_LS
 SG_ LRSMP_Type14 : 51|4@0+ (1,0) [0|15] ""  RSE_LS,CGM_LS,CSM_LS,RadioHead_LS
 SG_ LRSMP_Type13 : 55|4@0+ (1,0) [0|15] ""  RSE_LS,CGM_LS,CSM_LS,RadioHead_LS
 SG_ LRSMP_Type12 : 43|4@0+ (1,0) [0|15] ""  RSE_LS,CGM_LS,CSM_LS,RadioHead_LS
 SG_ LRSMP_Type11 : 47|4@0+ (1,0) [0|15] ""  RSE_LS,CGM_LS,CSM_LS,RadioHead_LS
 SG_ LRSMP_Type10 : 35|4@0+ (1,0) [0|15] ""  RSE_LS,CGM_LS,CSM_LS,RadioHead_LS
 SG_ LRSMP_Type9 : 39|4@0+ (1,0) [0|15] ""  RSE_LS,CGM_LS,CSM_LS,RadioHead_LS
 SG_ LRSMP_Type8 : 27|4@0+ (1,0) [0|15] ""  RSE_LS,CGM_LS,CSM_LS,RadioHead_LS
 SG_ LRSMP_Type7 : 31|4@0+ (1,0) [0|15] ""  RSE_LS,CGM_LS,CSM_LS,RadioHead_LS
 SG_ LRSMP_Type6 : 19|4@0+ (1,0) [0|15] ""  RSE_LS,CGM_LS,CSM_LS,RadioHead_LS
 SG_ LRSMP_Type5 : 23|4@0+ (1,0) [0|15] ""  RSE_LS,CGM_LS,CSM_LS,RadioHead_LS
 SG_ LRSMP_Type4 : 11|4@0+ (1,0) [0|15] ""  RSE_LS,CGM_LS,CSM_LS,RadioHead_LS
 SG_ LRSMP_Type3 : 15|4@0+ (1,0) [0|15] ""  RSE_LS,CGM_LS,CSM_LS,RadioHead_LS
 SG_ LRSMP_Type2 : 3|4@0+ (1,0) [0|15] ""  RSE_LS,CGM_LS,CSM_LS,RadioHead_LS
 SG_ LRSMP_Type1 : 7|4@0+ (1,0) [0|15] ""  RSE_LS,CGM_LS,CSM_LS,RadioHead_LS

BO_ 2152071168 Left_Rear_Seat_Actuator_LS: 8 MSM_LR_LS
 SG_ LRSAP_UnsdRsrvd : 59|4@0+ (1,0) [0|15] ""  RSE_LS,CGM_LS,CSM_LS,RadioHead_LS
 SG_ LRSAP_DispSz : 63|4@0+ (1,0) [0|15] ""  RSE_LS,CGM_LS,CSM_LS,RadioHead_LS
 SG_ LRSAP_CshLgthAdjFdRr : 51|4@0+ (1,0) [0|15] ""  RSE_LS,CGM_LS,CSM_LS,RadioHead_LS
 SG_ LRSAP_BkCshBlstrInOut : 55|4@0+ (1,0) [0|15] ""  RSE_LS,CGM_LS,CSM_LS,RadioHead_LS
 SG_ LRSAP_CshBlstrInOut : 43|4@0+ (1,0) [0|15] ""  RSE_LS,CGM_LS,CSM_LS,RadioHead_LS
 SG_ LRSAP_BkBlstrInOut : 47|4@0+ (1,0) [0|15] ""  RSE_LS,CGM_LS,CSM_LS,RadioHead_LS
 SG_ LRSAP_LmbrUpDnFdRr : 35|4@0+ (1,0) [0|15] ""  RSE_LS,CGM_LS,CSM_LS,RadioHead_LS
 SG_ LRSAP_LmbrFwdRr : 39|4@0+ (1,0) [0|15] ""  RSE_LS,CGM_LS,CSM_LS,RadioHead_LS
 SG_ LRSAP_LmbrUpDwn : 27|4@0+ (1,0) [0|15] ""  RSE_LS,CGM_LS,CSM_LS,RadioHead_LS
 SG_ LRSAP_UprShldrFwdRr : 31|4@0+ (1,0) [0|15] ""  RSE_LS,CGM_LS,CSM_LS,RadioHead_LS
 SG_ LRSAP_HdrstTltFwdRr : 19|4@0+ (1,0) [0|15] ""  RSE_LS,CGM_LS,CSM_LS,RadioHead_LS
 SG_ LRSAP_HdrstWngsInOut : 23|4@0+ (1,0) [0|15] ""  RSE_LS,CGM_LS,CSM_LS,RadioHead_LS
 SG_ LRSAP_HdrstUpDnFdRr : 11|4@0+ (1,0) [0|15] ""  RSE_LS,CGM_LS,CSM_LS,RadioHead_LS
 SG_ LRSAP_HdrstFwdRrwd : 15|4@0+ (1,0) [0|15] ""  RSE_LS,CGM_LS,CSM_LS,RadioHead_LS
 SG_ LRSAP_HdrstUpDn : 3|4@0+ (1,0) [0|15] ""  RSE_LS,CGM_LS,CSM_LS,RadioHead_LS
 SG_ LRSAP_Massg : 7|4@0+ (1,0) [0|15] ""  RSE_LS,CGM_LS,CSM_LS,RadioHead_LS

BO_ 2153947136 Remote_Reflash_Stat_LS: 1 BCM_LS
 SG_ RmtRflshMdAct : 7|1@0+ (1,0) [0|1] ""  CGM_LS,CSM_LS,RadioHead_LS

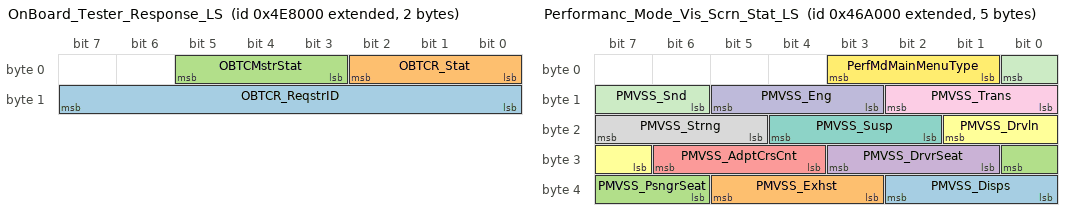
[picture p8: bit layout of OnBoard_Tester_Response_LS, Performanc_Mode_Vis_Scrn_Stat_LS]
BO_ 2152628224 OnBoard_Tester_Response_LS: 2 TCP_LS
 SG_ OBTCR_ReqstrID : 15|8@0+ (1,0) [0|255] ""  CGM_LS,CSM_LS
 SG_ OBTCR_Stat : 2|3@0+ (1,0) [0|7] ""  CGM_LS,CSM_LS
 SG_ OBTCMstrStat : 5|3@0+ (1,0) [0|7] ""  CGM_LS,CSM_LS

BO_ 2152112128 Performanc_Mode_Vis_Scrn_Stat_LS: 5 BCM_LS
 SG_ PMVSS_Disps : 34|3@0+ (1,0) [0|7] ""  CGM_LS,CSM_LS,RadioHead_LS
 SG_ PMVSS_Exhst : 37|3@0+ (1,0) [0|7] ""  CGM_LS,CSM_LS,RadioHead_LS
 SG_ PMVSS_PsngrSeat : 24|3@0+ (1,0) [0|7] ""  CGM_LS,CSM_LS,RadioHead_LS
 SG_ PMVSS_DrvrSeat : 27|3@0+ (1,0) [0|7] ""  CGM_LS,CSM_LS,RadioHead_LS
 SG_ PMVSS_AdptCrsCnt : 30|3@0+ (1,0) [0|7] ""  CGM_LS,CSM_LS,RadioHead_LS
 SG_ PMVSS_Drvln : 17|3@0+ (1,0) [0|7] ""  CGM_LS,CSM_LS,RadioHead_LS
 SG_ PMVSS_Susp : 20|3@0+ (1,0) [0|7] ""  CGM_LS,CSM_LS,RadioHead_LS
 SG_ PMVSS_Strng : 23|3@0+ (1,0) [0|7] ""  CGM_LS,CSM_LS,RadioHead_LS
 SG_ PMVSS_Trans : 10|3@0+ (1,0) [0|7] ""  CGM_LS,CSM_LS,RadioHead_LS
 SG_ PMVSS_Eng : 13|3@0+ (1,0) [0|7] ""  CGM_LS,CSM_LS,RadioHead_LS
 SG_ PMVSS_Snd : 0|3@0+ (1,0) [0|7] ""  CGM_LS,CSM_LS,RadioHead_LS
 SG_ PerfMdMainMenuType : 3|3@0+ (1,0) [0|7] ""  CGM_LS,CSM_LS,RadioHead_LS

BO_TX_BU_ 128 : CGM_LS,Dummy_LS;
BO_TX_BU_ 2152046592 : CGM_LS,TCP_LS,ONSTAR_LS;
BO_TX_BU_ 2152030208 : TCP_LS,ONSTAR_LS;
BO_TX_BU_ 2151702528 : EOCM2A_K2_LS,FCM_LS,EOCM_F_LS;
BO_TX_BU_ 2156986368 : CSM_LS,ONSTAR_LS,CGM_LS;
BO_TX_BU_ 2156978176 : CSM_LS,ONSTAR_LS,CGM_LS;
BO_TX_BU_ 2156969984 : CSM_LS,ONSTAR_LS,CGM_LS;
BO_TX_BU_ 2154725376 : BCM_LS,ECC_LS;
BO_TX_BU_ 2156994560 : CSM_LS,ONSTAR_LS,CGM_LS;
BO_TX_BU_ 2152513536 : LVMPC_LS,LVMNav_LS;
BO_TX_BU_ 2156961792 : CSM_LS,ONSTAR_LS,CGM_LS;
BO_TX_BU_ 2154569728 : RadioHead_LS,CGM_LS,CSM_LS;
BO_TX_BU_ 2150244352 : BSM_LS,VICM_LS;
BO_TX_BU_ 2156953600 : CSM_LS,ONSTAR_LS,CGM_LS;
BO_TX_BU_ 2155028480 : SBZA_L_LS,SBZA_R_LS,EOCM2A_K2_LS,UPA_LS,APA_LS;
BO_TX_BU_ 2150129664 : CGM_LS,CSM_LS,VPM_LS;
BO_TX_BU_ 2154299392 : CGM_LS,VKM_LS;
BO_TX_BU_ 2154553344 : CGM_LS,VKM_LS;
BO_TX_BU_ 2154520576 : CGM_LS,VKM_LS;
BO_TX_BU_ 2154479616 : CGM_LS,VKM_LS;
BO_TX_BU_ 2154381312 : CGM_LS,VKM_LS;
CM_ SG_ 2154725376 AuxHtrAtv378 "Auxiliary Heater shall be used to denote a heater function that uses some kind of power, electrical or mechanical,  that was generated by the engine.";
CM_ SG_ 2154725376 AuxHtrRq "Auxiliary Heater shall be used to denote a heater function that uses some kind of power, electrical or mechanical,  that was generated by the engine.";
BA_DEF_ SG_  "VNSigPrimaryTriggering" ENUM  "No","Yes","DLCLS","DLCHS","DLCCE","DLCFO";
BA_DEF_ SG_  "VNSigRemoteDiagnostics" ENUM  "No","Yes","DLCLS","DLCHS","DLCCE","DLCFO";
BA_DEF_ SG_  "VNSigInfotainment" ENUM  "No","Yes","DLCLS","DLCHS","DLCCE","DLCFO";
BA_DEF_ SG_  "VNSigParkedVehicle" ENUM  "No","Yes","DLCLS","DLCHS","DLCCE","DLCFO";
BA_DEF_ SG_  "VNSigIntermediate" ENUM  "No","Yes","DLCLS","DLCHS","DLCCE","DLCFO";
BA_DEF_ SG_  "VNSigUnused_4" ENUM  "No","Yes","DLCLS","DLCHS","DLCCE","DLCFO";
BA_DEF_ SG_  "SignalType" STRING ;
BA_DEF_ SG_  "PacketOrder" INT 0 65535;
BA_DEF_ SG_  "SignalLongName" STRING ;
BA_DEF_ SG_  "GenSigStartValue" INT 0 65535;
BA_DEF_ SG_  "VNSigDiagnostic" ENUM  "No","Yes","DLCLS","DLCHS","DLCCE","DLCFO";
BA_DEF_ SG_  "VNSigAllNodes" ENUM  "No","Yes","DLCLS","DLCHS","DLCCE","DLCFO";
BA_DEF_ SG_  "GenSigDeltaValue" INT 0 0;
BA_DEF_ SG_  "GenSigInactiveValue" INT 0 0;
BA_DEF_ SG_  "GenSigSendType" ENUM  "not used","not used","not used","not used","not used","not used","not used","NoSigSendType","not used","not used","OnAnyChange","OnChangeIfActive","OnDelta","DLCLS","DLCHS","DLCCE","DLCFO";
BA_DEF_ SG_  "GenSigSendOnInit" ENUM  "Not Initialized","Application","Handler","DLCLS","DLCHS","DLCCE","DLCFO";
BA_DEF_ BO_  "AppGenMsgCycleTime" INT 0 0;
BA_DEF_ BO_  "TpTxIndex" INT 0 99;
BA_DEF_ BO_  "GenMsgILSupport" ENUM  "No","Yes","DLCLS","DLCHS","DLCCE","DLCFO";
BA_DEF_ BO_  "TpApplType" STRING ;
BA_DEF_ BO_  "Prio" INT 0 7;
BA_DEF_ BO_  "MessageSubnet" ENUM  "LS","MS","HS","CE","PE","HV","FO","S1","HE","LE","HE2","DLCLS","DLCHS","DLCCE","DLCFO";
BA_DEF_ BO_  "GenMsgMandatoryToSupervision" ENUM  "No","Yes","DLCLS","DLCHS","DLCCE","DLCFO";
BA_DEF_ BO_  "DiagState" ENUM  "No","Yes","DLCLS","DLCHS","DLCCE","DLCFO";
BA_DEF_ BO_  "GenMsgStartDelayTime" INT 0 100000;
BA_DEF_ BO_  "GenMsgDelayTime" INT 0 100000;
BA_DEF_ BO_  "GenMsgCycleTime" INT 0 100000;
BA_DEF_ BO_  "GenMsgSendType" ENUM  "cyclicX","spontanX","cyclicIfActiveX","spontanWithDelay","cyclicAndSpontanX","cyclicAndSpontanWithDelay","spontanWithRepitition","cyclicIfActiveAndSpontanWD","DLCLS","DLCHS","DLCCE","DLCFO";
BA_DEF_ BO_  "DiagResponse" ENUM  "No","Yes","DLCLS","DLCHS","DLCCE","DLCFO";
BA_DEF_ BO_  "DiagRequest" ENUM  "No","Yes","DLCLS","DLCHS","DLCCE","DLCFO";
BA_DEF_ BO_  "NmMessage" ENUM  "No","Yes","DLCLS","DLCHS","DLCCE","DLCFO";
BA_DEF_REL_ BU_SG_REL_  "GenSigSuprvRespComment" STRING ;
BA_DEF_REL_ BU_SG_REL_  "GenSigVBitResp" ENUM  "No","Yes","DLCLS","DLCHS","DLCCE","DLCFO";
BA_DEF_REL_ BU_SG_REL_  "GenSigVBitRespComment" STRING ;
BA_DEF_REL_ BU_SG_REL_  "GenSigVDAFailComment" STRING ;
BA_DEF_REL_ BU_SG_REL_  "GenSigVDAFailResp" ENUM  "No","Yes","DLCLS","DLCHS","DLCCE","DLCFO";
BA_DEF_REL_ BU_SG_REL_  "GenSigRxStartValue" STRING ;
BA_DEF_REL_ BU_SG_REL_  "GenSigSuprvRespSubValue" INT 0 65535;
BA_DEF_REL_ BU_SG_REL_  "GenSigSuprvResp" ENUM  "None","Notify App","Substitute Default","DLCLS","DLCHS","DLCCE","DLCFO";
BA_DEF_REL_ BU_SG_REL_  "GenSigTimeoutMsg" HEX -2147483648 268435455;
BA_DEF_REL_ BU_SG_REL_  "GenSigTimeoutTime" INT 0 15000;
BA_DEF_DEF_  "VNSigPrimaryTriggering" "No";
BA_DEF_DEF_  "VNSigRemoteDiagnostics" "No";
BA_DEF_DEF_  "VNSigInfotainment" "No";
BA_DEF_DEF_  "VNSigParkedVehicle" "No";
BA_DEF_DEF_  "VNSigIntermediate" "No";
BA_DEF_DEF_  "VNSigUnused_4" "No";
BA_DEF_DEF_  "SignalType" "";
BA_DEF_DEF_  "PacketOrder" 0;
BA_DEF_DEF_  "SignalLongName" "";
BA_DEF_DEF_  "GenSigStartValue" 0;
BA_DEF_DEF_  "VNSigDiagnostic" "No";
BA_DEF_DEF_  "VNSigAllNodes" "No";
BA_DEF_DEF_  "GenSigDeltaValue" 0;
BA_DEF_DEF_  "GenSigInactiveValue" 0;
BA_DEF_DEF_  "GenSigSendType" "NoSigSendType";
BA_DEF_DEF_  "GenSigSendOnInit" "Not Initialized";
BA_DEF_DEF_  "AppGenMsgCycleTime" 0;
BA_DEF_DEF_  "TpTxIndex" 0;
BA_DEF_DEF_  "GenMsgILSupport" "Yes";
BA_DEF_DEF_  "TpApplType" "";
BA_DEF_DEF_  "Prio" 4;
BA_DEF_DEF_  "MessageSubnet" "FO";
BA_DEF_DEF_  "GenMsgMandatoryToSupervision" "No";
BA_DEF_DEF_  "DiagState" "No";
BA_DEF_DEF_  "GenMsgStartDelayTime" 0;
BA_DEF_DEF_  "GenMsgDelayTime" 0;
BA_DEF_DEF_  "GenMsgCycleTime" 0;
BA_DEF_DEF_  "GenMsgSendType" "spontanX";
BA_DEF_DEF_  "DiagResponse" "No";
BA_DEF_DEF_  "DiagRequest" "No";
BA_DEF_DEF_  "NmMessage" "No";
BA_DEF_DEF_REL_ "GenSigSuprvRespComment" "";
BA_DEF_DEF_REL_ "GenSigVBitResp" "No";
BA_DEF_DEF_REL_ "GenSigVBitRespComment" "";
BA_DEF_DEF_REL_ "GenSigVDAFailComment" "";
BA_DEF_DEF_REL_ "GenSigVDAFailResp" "No";
BA_DEF_DEF_REL_ "GenSigRxStartValue" "";
BA_DEF_DEF_REL_ "GenSigSuprvRespSubValue" 0;
BA_DEF_DEF_REL_ "GenSigSuprvResp" "None";
BA_DEF_DEF_REL_ "GenSigTimeoutMsg" 0;
BA_DEF_DEF_REL_ "GenSigTimeoutTime" 0;
BA_ "Prio" BO_ 168 0;
BA_ "MessageSubnet" BO_ 168 0;
BA_ "DiagRequest" BO_ 168 1;
BA_ "Prio" BO_ 128 0;
BA_ "MessageSubnet" BO_ 128 0;
BA_ "DiagRequest" BO_ 128 1;
BA_ "Prio" BO_ 896 0;
BA_ "MessageSubnet" BO_ 896 0;
BA_ "DiagResponse" BO_ 896 1;
BA_ "Prio" BO_ 153 0;
BA_ "MessageSubnet" BO_ 153 0;
BA_ "DiagRequest" BO_ 153 1;
BA_ "Prio" BO_ 1825 0;
BA_ "MessageSubnet" BO_ 1825 0;
BA_ "GenMsgCycleTime" BO_ 1825 3000;
BA_ "GenMsgSendType" BO_ 1825 0;
BA_ "NmMessage" BO_ 1825 1;
BA_ "Prio" BO_ 1824 0;
BA_ "MessageSubnet" BO_ 1824 0;
BA_ "GenMsgCycleTime" BO_ 1824 3000;
BA_ "GenMsgSendType" BO_ 1824 0;
BA_ "NmMessage" BO_ 1824 1;
BA_ "MessageSubnet" BO_ 2152046592 0;
BA_ "GenMsgDelayTime" BO_ 2152046592 20;
BA_ "MessageSubnet" BO_ 2152030208 0;
BA_ "GenMsgDelayTime" BO_ 2152030208 100;
BA_ "MessageSubnet" BO_ 2150531072 0;
BA_ "GenMsgDelayTime" BO_ 2150531072 100;
BA_ "MessageSubnet" BO_ 2151833600 0;
BA_ "GenMsgDelayTime" BO_ 2151833600 20;
BA_ "MessageSubnet" BO_ 2151817216 0;
BA_ "GenMsgDelayTime" BO_ 2151817216 20;
BA_ "MessageSubnet" BO_ 2151849984 0;
BA_ "GenMsgDelayTime" BO_ 2151849984 250;
BA_ "MessageSubnet" BO_ 2153897984 0;
BA_ "GenMsgDelayTime" BO_ 2153897984 100;
BA_ "Prio" BO_ 936 0;
BA_ "MessageSubnet" BO_ 936 0;
BA_ "DiagResponse" BO_ 936 1;
BA_ "Prio" BO_ 856 0;
BA_ "MessageSubnet" BO_ 856 0;
BA_ "DiagResponse" BO_ 856 1;
BA_ "Prio" BO_ 872 0;
BA_ "MessageSubnet" BO_ 872 0;
BA_ "DiagResponse" BO_ 872 1;
BA_ "Prio" BO_ 864 0;
BA_ "MessageSubnet" BO_ 864 0;
BA_ "DiagResponse" BO_ 864 1;
BA_ "Prio" BO_ 921 0;
BA_ "MessageSubnet" BO_ 921 0;
BA_ "DiagResponse" BO_ 921 1;
BA_ "MessageSubnet" BO_ 2151702528 0;
BA_ "GenMsgDelayTime" BO_ 2151702528 100;
BA_ "MessageSubnet" BO_ 2154618880 0;
BA_ "GenMsgCycleTime" BO_ 2154618880 1000;
BA_ "GenMsgSendType" BO_ 2154618880 0;
BA_ "MessageSubnet" BO_ 2156986368 0;
BA_ "GenMsgDelayTime" BO_ 2156986368 100;
BA_ "MessageSubnet" BO_ 2156978176 0;
BA_ "GenMsgDelayTime" BO_ 2156978176 100;
BA_ "MessageSubnet" BO_ 2156969984 0;
BA_ "GenMsgDelayTime" BO_ 2156969984 100;
BA_ "MessageSubnet" BO_ 2150236160 0;
BA_ "GenMsgDelayTime" BO_ 2150236160 100;
BA_ "GenMsgCycleTime" BO_ 2150236160 1000;
BA_ "GenMsgSendType" BO_ 2150236160 0;
BA_ "MessageSubnet" BO_ 2150170624 0;
BA_ "GenMsgDelayTime" BO_ 2150170624 100;
BA_ "GenMsgCycleTime" BO_ 2150170624 1000;
BA_ "GenMsgSendType" BO_ 2150170624 0;
BA_ "MessageSubnet" BO_ 2155126784 0;
BA_ "GenMsgDelayTime" BO_ 2155126784 100;
BA_ "MessageSubnet" BO_ 2154725376 0;
BA_ "GenMsgDelayTime" BO_ 2154725376 100;
BA_ "MessageSubnet" BO_ 2157051904 0;
BA_ "GenMsgDelayTime" BO_ 2157051904 100;
BA_ "MessageSubnet" BO_ 2156994560 0;
BA_ "GenMsgDelayTime" BO_ 2156994560 100;
BA_ "MessageSubnet" BO_ 2158133248 0;
BA_ "GenMsgDelayTime" BO_ 2158133248 100;
BA_ "MessageSubnet" BO_ 2154651648 0;
BA_ "GenMsgDelayTime" BO_ 2154651648 50;
BA_ "MessageSubnet" BO_ 2154635264 0;
BA_ "GenMsgDelayTime" BO_ 2154635264 50;
BA_ "MessageSubnet" BO_ 2152529920 0;
BA_ "GenMsgDelayTime" BO_ 2152529920 100;
BA_ "MessageSubnet" BO_ 2152513536 0;
BA_ "GenMsgDelayTime" BO_ 2152513536 100;
BA_ "MessageSubnet" BO_ 2154889216 0;
BA_ "GenMsgDelayTime" BO_ 2154889216 100;
BA_ "MessageSubnet" BO_ 2154872832 0;
BA_ "GenMsgDelayTime" BO_ 2154872832 100;
BA_ "GenMsgCycleTime" BO_ 2154872832 2000;
BA_ "GenMsgSendType" BO_ 2154872832 0;
BA_ "MessageSubnet" BO_ 2156961792 0;
BA_ "GenMsgDelayTime" BO_ 2156961792 100;
BA_ "MessageSubnet" BO_ 2154569728 0;
BA_ "GenMsgDelayTime" BO_ 2154569728 100;
BA_ "GenMsgCycleTime" BO_ 2154569728 2000;
BA_ "GenMsgSendType" BO_ 2154569728 0;
BA_ "MessageSubnet" BO_ 2151931904 0;
BA_ "GenMsgDelayTime" BO_ 2151931904 100;
BA_ "MessageSubnet" BO_ 2150244352 0;
BA_ "GenMsgDelayTime" BO_ 2150244352 100;
BA_ "MessageSubnet" BO_ 2156953600 0;
BA_ "GenMsgDelayTime" BO_ 2156953600 100;
BA_ "MessageSubnet" BO_ 2151686144 0;
BA_ "GenMsgDelayTime" BO_ 2151686144 100;
BA_ "MessageSubnet" BO_ 2155028480 0;
BA_ "GenMsgDelayTime" BO_ 2155028480 100;
BA_ "MessageSubnet" BO_ 2151915520 0;
BA_ "GenMsgCycleTime" BO_ 2151915520 250;
BA_ "GenMsgSendType" BO_ 2151915520 0;
BA_ "MessageSubnet" BO_ 2150129664 0;
BA_ "GenMsgDelayTime" BO_ 2150129664 100;
BA_ "MessageSubnet" BO_ 2154299392 0;
BA_ "GenMsgDelayTime" BO_ 2154299392 100;
BA_ "MessageSubnet" BO_ 2154397696 0;
BA_ "GenMsgDelayTime" BO_ 2154397696 100;
BA_ "TpTxIndex" BO_ 2154553344 3;
BA_ "MessageSubnet" BO_ 2154553344 0;
BA_ "TpTxIndex" BO_ 2154536960 3;
BA_ "MessageSubnet" BO_ 2154536960 0;
BA_ "TpTxIndex" BO_ 2154545152 2;
BA_ "MessageSubnet" BO_ 2154545152 0;
BA_ "TpTxIndex" BO_ 2154520576 2;
BA_ "MessageSubnet" BO_ 2154520576 0;
BA_ "TpTxIndex" BO_ 2154504192 1;
BA_ "MessageSubnet" BO_ 2154504192 0;
BA_ "TpTxIndex" BO_ 2154479616 1;
BA_ "MessageSubnet" BO_ 2154479616 0;
BA_ "MessageSubnet" BO_ 2154381312 0;
BA_ "GenMsgDelayTime" BO_ 2154381312 20;
BA_ "GenMsgCycleTime" BO_ 2154381312 3000;
BA_ "GenMsgSendType" BO_ 2154381312 0;
BA_ "MessageSubnet" BO_ 2152153088 0;
BA_ "GenMsgDelayTime" BO_ 2152153088 100;
BA_ "MessageSubnet" BO_ 2152136704 0;
BA_ "GenMsgDelayTime" BO_ 2152136704 100;
BA_ "MessageSubnet" BO_ 2152120320 0;
BA_ "GenMsgDelayTime" BO_ 2152120320 100;
BA_ "MessageSubnet" BO_ 2152103936 0;
BA_ "GenMsgDelayTime" BO_ 2152103936 100;
BA_ "MessageSubnet" BO_ 2152087552 0;
BA_ "GenMsgDelayTime" BO_ 2152087552 100;
BA_ "MessageSubnet" BO_ 2152071168 0;
BA_ "GenMsgDelayTime" BO_ 2152071168 100;
BA_ "MessageSubnet" BO_ 2153947136 0;
BA_ "GenMsgDelayTime" BO_ 2153947136 100;
BA_ "MessageSubnet" BO_ 2152628224 0;
BA_ "GenMsgDelayTime" BO_ 2152628224 100;
BA_ "GenMsgCycleTime" BO_ 2152628224 3000;
BA_ "GenMsgSendType" BO_ 2152628224 0;
BA_ "MessageSubnet" BO_ 2152112128 0;
BA_ "GenMsgDelayTime" BO_ 2152112128 100;
BA_ "SignalType" SG_ 168 DgnInf "UNM";
BA_ "SignalLongName" SG_ 168 DgnInf "Diagnostic Information";
BA_ "VNSigDiagnostic" SG_ 168 DgnInf 1;
BA_ "VNSigAllNodes" SG_ 168 DgnInf 1;
BA_ "SignalType" SG_ 128 DgnInf "UNM";
BA_ "SignalLongName" SG_ 128 DgnInf "Diagnostic Information";
BA_ "VNSigDiagnostic" SG_ 128 DgnInf 1;
BA_ "VNSigAllNodes" SG_ 128 DgnInf 1;
BA_ "SignalType" SG_ 896 DgnInf "UNM";
BA_ "SignalLongName" SG_ 896 DgnInf "Diagnostic Information";
BA_ "VNSigDiagnostic" SG_ 896 DgnInf 1;
BA_ "VNSigAllNodes" SG_ 896 DgnInf 1;
BA_ "SignalType" SG_ 153 DgnInf "UNM";
BA_ "SignalLongName" SG_ 153 DgnInf "Diagnostic Information";
BA_ "VNSigDiagnostic" SG_ 153 DgnInf 1;
BA_ "VNSigAllNodes" SG_ 153 DgnInf 1;
BA_ "VNSigPrimaryTriggering" SG_ 1825 VectraSpcNWMgtD 1;
BA_ "VNSigRemoteDiagnostics" SG_ 1825 VectraSpcNWMgtD 1;
BA_ "VNSigInfotainment" SG_ 1825 VectraSpcNWMgtD 1;
BA_ "VNSigParkedVehicle" SG_ 1825 VectraSpcNWMgtD 1;
BA_ "VNSigIntermediate" SG_ 1825 VectraSpcNWMgtD 1;
BA_ "VNSigUnused_4" SG_ 1825 VectraSpcNWMgtD 1;
BA_ "SignalType" SG_ 1825 VectraSpcNWMgtD "UNM";
BA_ "SignalLongName" SG_ 1825 VectraSpcNWMgtD "Vectra Specific Network Management Data";
BA_ "VNSigDiagnostic" SG_ 1825 VectraSpcNWMgtD 1;
BA_ "VNSigAllNodes" SG_ 1825 VectraSpcNWMgtD 1;
BA_ "VNSigPrimaryTriggering" SG_ 1824 VectraSpcNWMgtD 1;
BA_ "VNSigRemoteDiagnostics" SG_ 1824 VectraSpcNWMgtD 1;
BA_ "VNSigInfotainment" SG_ 1824 VectraSpcNWMgtD 1;
BA_ "VNSigParkedVehicle" SG_ 1824 VectraSpcNWMgtD 1;
BA_ "VNSigIntermediate" SG_ 1824 VectraSpcNWMgtD 1;
BA_ "VNSigUnused_4" SG_ 1824 VectraSpcNWMgtD 1;
BA_ "SignalType" SG_ 1824 VectraSpcNWMgtD "UNM";
BA_ "SignalLongName" SG_ 1824 VectraSpcNWMgtD "Vectra Specific Network Management Data";
BA_ "VNSigDiagnostic" SG_ 1824 VectraSpcNWMgtD 1;
BA_ "VNSigAllNodes" SG_ 1824 VectraSpcNWMgtD 1;
BA_ "GenSigSendType" SG_ 2152046592 RmClmCtrlHMIActIndReq 10;
BA_ "VNSigIntermediate" SG_ 2152046592 RmClmCtrlHMIActIndReq 1;
BA_ "SignalType" SG_ 2152046592 RmClmCtrlHMIActIndReq "ENM";
BA_ "SignalLongName" SG_ 2152046592 RmClmCtrlHMIActIndReq "Remote Climate Control HMI Active Indication Request";
BA_ "GenSigSendType" SG_ 2152046592 RmClmCtrlSyncSetReq 10;
BA_ "VNSigIntermediate" SG_ 2152046592 RmClmCtrlSyncSetReq 1;
BA_ "SignalType" SG_ 2152046592 RmClmCtrlSyncSetReq "ENM";
BA_ "SignalLongName" SG_ 2152046592 RmClmCtrlSyncSetReq "Remote Climate Control Sync Setting Request";
BA_ "GenSigSendType" SG_ 2152046592 RmClmCtrlRrDfgSetReq 10;
BA_ "VNSigIntermediate" SG_ 2152046592 RmClmCtrlRrDfgSetReq 1;
BA_ "SignalType" SG_ 2152046592 RmClmCtrlRrDfgSetReq "ENM";
BA_ "SignalLongName" SG_ 2152046592 RmClmCtrlRrDfgSetReq "Remote Climate Control Rear Defog Setting Request";
BA_ "GenSigSendType" SG_ 2152046592 RmClmCtrlRcrcSetReq 10;
BA_ "VNSigIntermediate" SG_ 2152046592 RmClmCtrlRcrcSetReq 1;
BA_ "SignalType" SG_ 2152046592 RmClmCtrlRcrcSetReq "ENM";
BA_ "SignalLongName" SG_ 2152046592 RmClmCtrlRcrcSetReq "Remote Climate Control Recirculation Setting Request";
BA_ "GenSigSendType" SG_ 2152046592 RmClmCtrlClmModSetReq 10;
BA_ "VNSigIntermediate" SG_ 2152046592 RmClmCtrlClmModSetReq 1;
BA_ "SignalType" SG_ 2152046592 RmClmCtrlClmModSetReq "ENM";
BA_ "SignalLongName" SG_ 2152046592 RmClmCtrlClmModSetReq "Remote Climate Control Climate Mode Setting Request";
BA_ "GenSigSendType" SG_ 2152046592 RmClmCtrlACSetReq 10;
BA_ "VNSigIntermediate" SG_ 2152046592 RmClmCtrlACSetReq 1;
BA_ "SignalType" SG_ 2152046592 RmClmCtrlACSetReq "ENM";
BA_ "SignalLongName" SG_ 2152046592 RmClmCtrlACSetReq "Remote Climate Control Air Conditioning Setting Request";
BA_ "GenSigSendType" SG_ 2152046592 RmClmCtrlFLAirDtStReq 10;
BA_ "VNSigIntermediate" SG_ 2152046592 RmClmCtrlFLAirDtStReq 1;
BA_ "SignalType" SG_ 2152046592 RmClmCtrlFLAirDtStReq "ENM";
BA_ "SignalLongName" SG_ 2152046592 RmClmCtrlFLAirDtStReq "Remote Climate Control Front Left Air Distribution Setting Request";
BA_ "GenSigSendType" SG_ 2152046592 RmClmCtrlFrntFanStReq 10;
BA_ "VNSigIntermediate" SG_ 2152046592 RmClmCtrlFrntFanStReq 1;
BA_ "SignalType" SG_ 2152046592 RmClmCtrlFrntFanStReq "ENM";
BA_ "SignalLongName" SG_ 2152046592 RmClmCtrlFrntFanStReq "Remote Climate Control Front Fan Setting Request";
BA_ "GenSigSendType" SG_ 2152046592 RmClmCtrlRtSTempStReq 10;
BA_ "VNSigIntermediate" SG_ 2152046592 RmClmCtrlRtSTempStReq 1;
BA_ "SignalType" SG_ 2152046592 RmClmCtrlRtSTempStReq "ENM";
BA_ "SignalLongName" SG_ 2152046592 RmClmCtrlRtSTempStReq "Remote Climate Control Right Set Temperature Setting Request";
BA_ "GenSigSendType" SG_ 2152046592 RmClmCtrlLtSTempStReq 10;
BA_ "VNSigIntermediate" SG_ 2152046592 RmClmCtrlLtSTempStReq 1;
BA_ "SignalType" SG_ 2152046592 RmClmCtrlLtSTempStReq "ENM";
BA_ "SignalLongName" SG_ 2152046592 RmClmCtrlLtSTempStReq "Remote Climate Control Left Set Temperature Setting Request";
BA_ "GenSigSendType" SG_ 2152030208 TnrFrqChnlReq 10;
BA_ "VNSigIntermediate" SG_ 2152030208 TnrFrqChnlReq 1;
BA_ "SignalType" SG_ 2152030208 TnrFrqChnlReq "ASC";
BA_ "SignalLongName" SG_ 2152030208 TnrFrqChnlReq "Tuner Frequency/Channel Request";
BA_ "GenSigSendType" SG_ 2152030208 TnrFrqBndReq 10;
BA_ "VNSigIntermediate" SG_ 2152030208 TnrFrqBndReq 1;
BA_ "SignalType" SG_ 2152030208 TnrFrqBndReq "ENM";
BA_ "SignalLongName" SG_ 2152030208 TnrFrqBndReq "Tuner Frequency Band Request";
BA_ "GenSigDeltaValue" SG_ 2150531072 OBHVDCCMinRmng 1;
BA_ "GenSigSendType" SG_ 2150531072 OBHVDCCMinRmng 12;
BA_ "GenSigSendOnInit" SG_ 2150531072 OBHVDCCMinRmng 1;
BA_ "VNSigInfotainment" SG_ 2150531072 OBHVDCCMinRmng 1;
BA_ "SignalType" SG_ 2150531072 OBHVDCCMinRmng "UNM";
BA_ "SignalLongName" SG_ 2150531072 OBHVDCCMinRmng "Off Board High Voltage DC Charging Minutes Remaining";
BA_ "VNSigAllNodes" SG_ 2150531072 OBHVDCCMinRmng 1;
BA_ "GenSigSendType" SG_ 2150531072 OBHVDCCCpltnTmDspFrmt 10;
BA_ "GenSigSendOnInit" SG_ 2150531072 OBHVDCCCpltnTmDspFrmt 1;
BA_ "VNSigInfotainment" SG_ 2150531072 OBHVDCCCpltnTmDspFrmt 1;
BA_ "SignalType" SG_ 2150531072 OBHVDCCCpltnTmDspFrmt "ENM";
BA_ "SignalLongName" SG_ 2150531072 OBHVDCCCpltnTmDspFrmt "Off Board High Voltage DC Charging Completion Time Display Format";
BA_ "VNSigAllNodes" SG_ 2150531072 OBHVDCCCpltnTmDspFrmt 1;
BA_ "GenSigSendType" SG_ 2150531072 ClsHdToStrtVehIO 10;
BA_ "SignalType" SG_ 2150531072 ClsHdToStrtVehIO "BLN";
BA_ "SignalLongName" SG_ 2150531072 ClsHdToStrtVehIO "Close Hood To Start Vehicle Indication On";
BA_ "VNSigAllNodes" SG_ 2150531072 ClsHdToStrtVehIO 1;
BA_ "GenSigSendType" SG_ 2150531072 HVBChrgOvrdBtnDspStat 10;
BA_ "GenSigSendOnInit" SG_ 2150531072 HVBChrgOvrdBtnDspStat 1;
BA_ "VNSigInfotainment" SG_ 2150531072 HVBChrgOvrdBtnDspStat 1;
BA_ "SignalType" SG_ 2150531072 HVBChrgOvrdBtnDspStat "ENM";
BA_ "SignalLongName" SG_ 2150531072 HVBChrgOvrdBtnDspStat "High Voltage Battery Charge Override Button Display Status";
BA_ "VNSigAllNodes" SG_ 2150531072 HVBChrgOvrdBtnDspStat 1;
BA_ "GenSigSendType" SG_ 2150531072 HVBChrgLmtBtnDspStat 10;
BA_ "GenSigSendOnInit" SG_ 2150531072 HVBChrgLmtBtnDspStat 1;
BA_ "VNSigInfotainment" SG_ 2150531072 HVBChrgLmtBtnDspStat 1;
BA_ "SignalType" SG_ 2150531072 HVBChrgLmtBtnDspStat "ENM";
BA_ "SignalLongName" SG_ 2150531072 HVBChrgLmtBtnDspStat "High Voltage Battery Charge Limit Button Display Status";
BA_ "VNSigAllNodes" SG_ 2150531072 HVBChrgLmtBtnDspStat 1;
BA_ "GenSigSendType" SG_ 2150531072 HVBHmChrgTmDspStat 10;
BA_ "GenSigSendOnInit" SG_ 2150531072 HVBHmChrgTmDspStat 1;
BA_ "VNSigInfotainment" SG_ 2150531072 HVBHmChrgTmDspStat 1;
BA_ "SignalType" SG_ 2150531072 HVBHmChrgTmDspStat "ENM";
BA_ "SignalLongName" SG_ 2150531072 HVBHmChrgTmDspStat "High Voltage Battery Home Charge Time Display Status";
BA_ "VNSigAllNodes" SG_ 2150531072 HVBHmChrgTmDspStat 1;
BA_ "GenSigSendType" SG_ 2150531072 HVBChrgTmDspStat 10;
BA_ "GenSigSendOnInit" SG_ 2150531072 HVBChrgTmDspStat 1;
BA_ "VNSigInfotainment" SG_ 2150531072 HVBChrgTmDspStat 1;
BA_ "SignalType" SG_ 2150531072 HVBChrgTmDspStat "ENM";
BA_ "SignalLongName" SG_ 2150531072 HVBChrgTmDspStat "High Voltage Battery Charge Time Display Status";
BA_ "VNSigAllNodes" SG_ 2150531072 HVBChrgTmDspStat 1;
BA_ "GenSigSendType" SG_ 2150531072 RegPwrLmtdIO 10;
BA_ "GenSigSendOnInit" SG_ 2150531072 RegPwrLmtdIO 1;
BA_ "SignalType" SG_ 2150531072 RegPwrLmtdIO "BLN";
BA_ "SignalLongName" SG_ 2150531072 RegPwrLmtdIO "Regenerative Power Limited Indication On";
BA_ "VNSigAllNodes" SG_ 2150531072 RegPwrLmtdIO 1;
BA_ "GenSigSendType" SG_ 2150531072 RegPwrLmtdDspPrcntVs 10;
BA_ "GenSigSendOnInit" SG_ 2150531072 RegPwrLmtdDspPrcntVs 1;
BA_ "SignalType" SG_ 2150531072 RegPwrLmtdDspPrcntVs "BLN";
BA_ "SignalLongName" SG_ 2150531072 RegPwrLmtdDspPrcntVs "Regenerative Power Limited Display Percent Visible";
BA_ "VNSigAllNodes" SG_ 2150531072 RegPwrLmtdDspPrcntVs 1;
BA_ "GenSigDeltaValue" SG_ 2150531072 RegPwrLmtdDspPrcnt 1;
BA_ "GenSigSendType" SG_ 2150531072 RegPwrLmtdDspPrcnt 12;
BA_ "GenSigSendOnInit" SG_ 2150531072 RegPwrLmtdDspPrcnt 1;
BA_ "SignalType" SG_ 2150531072 RegPwrLmtdDspPrcnt "SNM";
BA_ "SignalLongName" SG_ 2150531072 RegPwrLmtdDspPrcnt "Regenerative Power Limited Display Percent";
BA_ "VNSigAllNodes" SG_ 2150531072 RegPwrLmtdDspPrcnt 1;
BA_ "GenSigSendType" SG_ 2151833600 HtdFrntWSDispReq 10;
BA_ "SignalType" SG_ 2151833600 HtdFrntWSDispReq "ENM";
BA_ "SignalLongName" SG_ 2151833600 HtdFrntWSDispReq "Heated Front Windshield Display Request";
BA_ "VNSigAllNodes" SG_ 2151833600 HtdFrntWSDispReq 1;
BA_ "GenSigSendType" SG_ 2151833600 HtdFrntWSCustRqIhbt 10;
BA_ "SignalType" SG_ 2151833600 HtdFrntWSCustRqIhbt "BLN";
BA_ "SignalLongName" SG_ 2151833600 HtdFrntWSCustRqIhbt "Heated Front Windshield Customer Request Inhibit";
BA_ "VNSigAllNodes" SG_ 2151833600 HtdFrntWSCustRqIhbt 1;
BA_ "GenSigSendType" SG_ 2151817216 HtdFrntWSCustRq 10;
BA_ "SignalType" SG_ 2151817216 HtdFrntWSCustRq "BLN";
BA_ "SignalLongName" SG_ 2151817216 HtdFrntWSCustRq "Heated Front Windshield Customer Request";
BA_ "VNSigAllNodes" SG_ 2151817216 HtdFrntWSCustRq 1;
BA_ "GenSigSendType" SG_ 2151849984 AutoThrmlStPassMdStRq 10;
BA_ "SignalType" SG_ 2151849984 AutoThrmlStPassMdStRq "ENM";
BA_ "SignalLongName" SG_ 2151849984 AutoThrmlStPassMdStRq "Auto Thermal Seat Passenger Mode Setting Request";
BA_ "VNSigAllNodes" SG_ 2151849984 AutoThrmlStPassMdStRq 1;
BA_ "GenSigSendType" SG_ 2151849984 AutoThrmlStDrvMdStRq 10;
BA_ "SignalType" SG_ 2151849984 AutoThrmlStDrvMdStRq "ENM";
BA_ "SignalLongName" SG_ 2151849984 AutoThrmlStDrvMdStRq "Auto Thermal Seat Driver Mode Setting Request";
BA_ "VNSigAllNodes" SG_ 2151849984 AutoThrmlStDrvMdStRq 1;
BA_ "GenSigSendType" SG_ 2151849984 AutoThrmlStPasLvlStRq 10;
BA_ "SignalType" SG_ 2151849984 AutoThrmlStPasLvlStRq "ENM";
BA_ "SignalLongName" SG_ 2151849984 AutoThrmlStPasLvlStRq "Auto Thermal Seat Passenger Level Setting Request";
BA_ "VNSigAllNodes" SG_ 2151849984 AutoThrmlStPasLvlStRq 1;
BA_ "GenSigSendType" SG_ 2151849984 AutoThrmlStDrvLvStRq 10;
BA_ "SignalType" SG_ 2151849984 AutoThrmlStDrvLvStRq "ENM";
BA_ "SignalLongName" SG_ 2151849984 AutoThrmlStDrvLvStRq "Auto Thermal Seat Driver Level Setting Request";
BA_ "VNSigAllNodes" SG_ 2151849984 AutoThrmlStDrvLvStRq 1;
BA_ "GenSigSendType" SG_ 2153897984 RunBrdExtdFtrAvail 10;
BA_ "GenSigSendOnInit" SG_ 2153897984 RunBrdExtdFtrAvail 2;
BA_ "SignalType" SG_ 2153897984 RunBrdExtdFtrAvail "BLN";
BA_ "SignalLongName" SG_ 2153897984 RunBrdExtdFtrAvail "Running Boards Extended Feature Available";
BA_ "VNSigAllNodes" SG_ 2153897984 RunBrdExtdFtrAvail 1;
BA_ "GenSigSendType" SG_ 2153897984 RunBrdOpMdCstCurrStVal 10;
BA_ "GenSigSendOnInit" SG_ 2153897984 RunBrdOpMdCstCurrStVal 2;
BA_ "SignalType" SG_ 2153897984 RunBrdOpMdCstCurrStVal "ENM";
BA_ "SignalLongName" SG_ 2153897984 RunBrdOpMdCstCurrStVal "Running Boards Operating Mode Customization Current Setting Value";
BA_ "VNSigAllNodes" SG_ 2153897984 RunBrdOpMdCstCurrStVal 1;
BA_ "GenSigSendType" SG_ 2153897984 RunBrdOpMdCstStAvail 10;
BA_ "GenSigSendOnInit" SG_ 2153897984 RunBrdOpMdCstStAvail 2;
BA_ "SignalType" SG_ 2153897984 RunBrdOpMdCstStAvail "BLN";
BA_ "SignalLongName" SG_ 2153897984 RunBrdOpMdCstStAvail "Running Boards Operating Mode Customization Setting Available";
BA_ "VNSigAllNodes" SG_ 2153897984 RunBrdOpMdCstStAvail 1;
BA_ "SignalType" SG_ 936 DgnInf "UNM";
BA_ "SignalLongName" SG_ 936 DgnInf "Diagnostic Information";
BA_ "VNSigDiagnostic" SG_ 936 DgnInf 1;
BA_ "VNSigAllNodes" SG_ 936 DgnInf 1;
BA_ "SignalType" SG_ 856 DgnInf "UNM";
BA_ "SignalLongName" SG_ 856 DgnInf "Diagnostic Information";
BA_ "VNSigDiagnostic" SG_ 856 DgnInf 1;
BA_ "VNSigAllNodes" SG_ 856 DgnInf 1;
BA_ "SignalType" SG_ 872 DgnInf "UNM";
BA_ "SignalLongName" SG_ 872 DgnInf "Diagnostic Information";
BA_ "VNSigDiagnostic" SG_ 872 DgnInf 1;
BA_ "VNSigAllNodes" SG_ 872 DgnInf 1;
BA_ "SignalType" SG_ 864 DgnInf "UNM";
BA_ "SignalLongName" SG_ 864 DgnInf "Diagnostic Information";
BA_ "VNSigDiagnostic" SG_ 864 DgnInf 1;
BA_ "VNSigAllNodes" SG_ 864 DgnInf 1;
BA_ "SignalType" SG_ 921 DgnInf "UNM";
BA_ "SignalLongName" SG_ 921 DgnInf "Diagnostic Information";
BA_ "VNSigDiagnostic" SG_ 921 DgnInf 1;
BA_ "VNSigAllNodes" SG_ 921 DgnInf 1;
BA_ "GenSigSendType" SG_ 2151702528 LnMrkngIndRgt 10;
BA_ "SignalType" SG_ 2151702528 LnMrkngIndRgt "ENM";
BA_ "SignalLongName" SG_ 2151702528 LnMrkngIndRgt "Lane Marking Indication Right";
BA_ "VNSigAllNodes" SG_ 2151702528 LnMrkngIndRgt 1;
BA_ "GenSigSendType" SG_ 2151702528 LnMrkngIndLft 10;
BA_ "SignalType" SG_ 2151702528 LnMrkngIndLft "ENM";
BA_ "SignalLongName" SG_ 2151702528 LnMrkngIndLft "Lane Marking Indication Left";
BA_ "VNSigAllNodes" SG_ 2151702528 LnMrkngIndLft 1;
BA_ "GenSigSendType" SG_ 2151702528 LnKepAsstStIndRgt 10;
BA_ "SignalType" SG_ 2151702528 LnKepAsstStIndRgt "ENM";
BA_ "SignalLongName" SG_ 2151702528 LnKepAsstStIndRgt "Lane Keeping Assist State Indication Right";
BA_ "VNSigAllNodes" SG_ 2151702528 LnKepAsstStIndRgt 1;
BA_ "GenSigSendType" SG_ 2151702528 LnKepAsstStIndLft 10;
BA_ "SignalType" SG_ 2151702528 LnKepAsstStIndLft "ENM";
BA_ "SignalLongName" SG_ 2151702528 LnKepAsstStIndLft "Lane Keeping Assist State Indication Left";
BA_ "VNSigAllNodes" SG_ 2151702528 LnKepAsstStIndLft 1;
BA_ "GenSigSendType" SG_ 2151702528 LnKpngAstRecfblIndRq 10;
BA_ "SignalType" SG_ 2151702528 LnKpngAstRecfblIndRq "ENM";
BA_ "SignalLongName" SG_ 2151702528 LnKpngAstRecfblIndRq "Lane Keeping Assist Reconfigurable Icon Indication Request";
BA_ "VNSigAllNodes" SG_ 2151702528 LnKpngAstRecfblIndRq 1;
BA_ "SignalType" SG_ 2154618880 ClmCntPrtyHtRqV "ENM";
BA_ "SignalLongName" SG_ 2154618880 ClmCntPrtyHtRqV "Climate Control Priority Heating Request Validity";
BA_ "VNSigAllNodes" SG_ 2154618880 ClmCntPrtyHtRqV 1;
BA_ "SignalType" SG_ 2154618880 ClmCntPrtyHtRq "ENM";
BA_ "SignalLongName" SG_ 2154618880 ClmCntPrtyHtRq "Climate Control Priority Heating Request";
BA_ "GenSigStartValue" SG_ 2154618880 ClmCntPrtyHtRq 2;
BA_ "VNSigAllNodes" SG_ 2154618880 ClmCntPrtyHtRq 1;
BA_ "SignalType" SG_ 2154618880 ClmCntCalcTrgtCbnHtLdV "ENM";
BA_ "SignalLongName" SG_ 2154618880 ClmCntCalcTrgtCbnHtLdV "Climate Control Calculated Target Cabin Heat Load Validity";
BA_ "VNSigAllNodes" SG_ 2154618880 ClmCntCalcTrgtCbnHtLdV 1;
BA_ "SignalType" SG_ 2154618880 ClmCntCalcTrgtCbnHtLd "UNM";
BA_ "SignalLongName" SG_ 2154618880 ClmCntCalcTrgtCbnHtLd "Climate Control Calculated Target Cabin Heat Load";
BA_ "GenSigStartValue" SG_ 2154618880 ClmCntCalcTrgtCbnHtLd 95.625149414296;
BA_ "VNSigAllNodes" SG_ 2154618880 ClmCntCalcTrgtCbnHtLd 1;
BA_ "SignalType" SG_ 2154618880 ClmCntMinTrgtClntTmpV "ENM";
BA_ "SignalLongName" SG_ 2154618880 ClmCntMinTrgtClntTmpV "Climate Control Minimum Target Coolant Temperature Validity";
BA_ "VNSigAllNodes" SG_ 2154618880 ClmCntMinTrgtClntTmpV 1;
BA_ "SignalType" SG_ 2154618880 ClmCntMinTrgtClntTmp "UNM";
BA_ "SignalLongName" SG_ 2154618880 ClmCntMinTrgtClntTmp "Climate Control Minimum Target Coolant Temperature";
BA_ "GenSigStartValue" SG_ 2154618880 ClmCntMinTrgtClntTmp 165.748674010608;
BA_ "VNSigAllNodes" SG_ 2154618880 ClmCntMinTrgtClntTmp 1;
BA_ "SignalType" SG_ 2154618880 ClmCntHtrMinFlwRtRqV "ENM";
BA_ "SignalLongName" SG_ 2154618880 ClmCntHtrMinFlwRtRqV "Climate Control Heater Minimum Flow Rate Request Validity";
BA_ "VNSigAllNodes" SG_ 2154618880 ClmCntHtrMinFlwRtRqV 1;
BA_ "SignalType" SG_ 2154618880 ClmCntHtrMinFlwRtRq "UNM";
BA_ "SignalLongName" SG_ 2154618880 ClmCntHtrMinFlwRtRq "Climate Control Heater Minimum Flow Rate Request";
BA_ "GenSigStartValue" SG_ 2154618880 ClmCntHtrMinFlwRtRq 47.812574707148;
BA_ "VNSigAllNodes" SG_ 2154618880 ClmCntHtrMinFlwRtRq 1;
BA_ "GenSigSendType" SG_ 2156986368 WiFiPssPhrsDgts17to24_Mp 10;
BA_ "GenSigSendOnInit" SG_ 2156986368 WiFiPssPhrsDgts17to24_Mp 2;
BA_ "SignalType" SG_ 2156986368 WiFiPssPhrsDgts17to24_Mp "ASC";
BA_ "SignalLongName" SG_ 2156986368 WiFiPssPhrsDgts17to24_Mp "WiFi Pass Phrase Digits 17 to 24 Map";
BA_ "VNSigAllNodes" SG_ 2156986368 WiFiPssPhrsDgts17to24_Mp 1;
BA_ "GenSigSendType" SG_ 2156978176 WiFiPssPhrsDgts9to16_Mp 10;
BA_ "GenSigSendOnInit" SG_ 2156978176 WiFiPssPhrsDgts9to16_Mp 2;
BA_ "SignalType" SG_ 2156978176 WiFiPssPhrsDgts9to16_Mp "ASC";
BA_ "SignalLongName" SG_ 2156978176 WiFiPssPhrsDgts9to16_Mp "WiFi Pass Phrase Digits 9 to 16 Map";
BA_ "VNSigAllNodes" SG_ 2156978176 WiFiPssPhrsDgts9to16_Mp 1;
BA_ "GenSigSendType" SG_ 2156969984 WiFiPssPhrsDgts1to8_Mp 10;
BA_ "GenSigSendOnInit" SG_ 2156969984 WiFiPssPhrsDgts1to8_Mp 2;
BA_ "SignalType" SG_ 2156969984 WiFiPssPhrsDgts1to8_Mp "ASC";
BA_ "SignalLongName" SG_ 2156969984 WiFiPssPhrsDgts1to8_Mp "WiFi Pass Phrase Digits 1 to 8 Map";
BA_ "VNSigAllNodes" SG_ 2156969984 WiFiPssPhrsDgts1to8_Mp 1;
BA_ "GenSigSendType" SG_ 2150236160 UlckKyStrCrptoDt2M 10;
BA_ "GenSigSendOnInit" SG_ 2150236160 UlckKyStrCrptoDt2M 2;
BA_ "VNSigInfotainment" SG_ 2150236160 UlckKyStrCrptoDt2M 1;
BA_ "SignalType" SG_ 2150236160 UlckKyStrCrptoDt2M "ENM";
BA_ "SignalLongName" SG_ 2150236160 UlckKyStrCrptoDt2M "Unlock Key Store Cryptographic Data 2 Mask";
BA_ "VNSigAllNodes" SG_ 2150236160 UlckKyStrCrptoDt2M 1;
BA_ "GenSigDeltaValue" SG_ 2150236160 UlckKyStrCrptoDt2 1;
BA_ "GenSigSendType" SG_ 2150236160 UlckKyStrCrptoDt2 12;
BA_ "GenSigSendOnInit" SG_ 2150236160 UlckKyStrCrptoDt2 2;
BA_ "VNSigInfotainment" SG_ 2150236160 UlckKyStrCrptoDt2 1;
BA_ "SignalType" SG_ 2150236160 UlckKyStrCrptoDt2 "UNM";
BA_ "SignalLongName" SG_ 2150236160 UlckKyStrCrptoDt2 "Unlock Key Store Cryptographic Data 2";
BA_ "VNSigAllNodes" SG_ 2150236160 UlckKyStrCrptoDt2 1;
BA_ "GenSigSendType" SG_ 2150170624 UlckKyStrCrptoDt1M 10;
BA_ "GenSigSendOnInit" SG_ 2150170624 UlckKyStrCrptoDt1M 2;
BA_ "VNSigInfotainment" SG_ 2150170624 UlckKyStrCrptoDt1M 1;
BA_ "SignalType" SG_ 2150170624 UlckKyStrCrptoDt1M "ENM";
BA_ "SignalLongName" SG_ 2150170624 UlckKyStrCrptoDt1M "Unlock Key Store Cryptographic Data 1 Mask";
BA_ "VNSigAllNodes" SG_ 2150170624 UlckKyStrCrptoDt1M 1;
BA_ "GenSigDeltaValue" SG_ 2150170624 UlckKyStrCrptoDt1 1;
BA_ "GenSigSendType" SG_ 2150170624 UlckKyStrCrptoDt1 12;
BA_ "GenSigSendOnInit" SG_ 2150170624 UlckKyStrCrptoDt1 2;
BA_ "VNSigInfotainment" SG_ 2150170624 UlckKyStrCrptoDt1 1;
BA_ "SignalType" SG_ 2150170624 UlckKyStrCrptoDt1 "UNM";
BA_ "SignalLongName" SG_ 2150170624 UlckKyStrCrptoDt1 "Unlock Key Store Cryptographic Data 1";
BA_ "VNSigAllNodes" SG_ 2150170624 UlckKyStrCrptoDt1 1;
BA_ "GenSigSendType" SG_ 2155126784 DrvrSetRrwrdMvmnt 10;
BA_ "GenSigSendOnInit" SG_ 2155126784 DrvrSetRrwrdMvmnt 2;
BA_ "SignalType" SG_ 2155126784 DrvrSetRrwrdMvmnt "ENM";
BA_ "SignalLongName" SG_ 2155126784 DrvrSetRrwrdMvmnt "Driver Seat Rearward Movement";
BA_ "VNSigAllNodes" SG_ 2155126784 DrvrSetRrwrdMvmnt 1;
BA_ "GenSigSendType" SG_ 2154725376 AuxHtrAtv378 10;
BA_ "SignalType" SG_ 2154725376 AuxHtrAtv378 "BLN";
BA_ "SignalLongName" SG_ 2154725376 AuxHtrAtv378 "Auxiliary Heater Active";
BA_ "VNSigAllNodes" SG_ 2154725376 AuxHtrAtv378 1;
BA_ "GenSigSendType" SG_ 2154725376 AuxHtrRq 10;
BA_ "SignalType" SG_ 2154725376 AuxHtrRq "ENM";
BA_ "SignalLongName" SG_ 2154725376 AuxHtrRq "Auxiliary Heater Request";
BA_ "VNSigAllNodes" SG_ 2154725376 AuxHtrRq 1;
BA_ "GenSigDeltaValue" SG_ 2157051904 WSMR_WiFiStnMpMACAddr 1;
BA_ "GenSigSendType" SG_ 2157051904 WSMR_WiFiStnMpMACAddr 12;
BA_ "GenSigSendOnInit" SG_ 2157051904 WSMR_WiFiStnMpMACAddr 1;
BA_ "SignalType" SG_ 2157051904 WSMR_WiFiStnMpMACAddr "UNM";
BA_ "PacketOrder" SG_ 2157051904 WSMR_WiFiStnMpMACAddr 2;
BA_ "SignalLongName" SG_ 2157051904 WSMR_WiFiStnMpMACAddr "WiFI Station Map Request : WiFi Station Map Media Access Control Address";
BA_ "VNSigAllNodes" SG_ 2157051904 WSMR_WiFiStnMpMACAddr 1;
BA_ "GenSigSendType" SG_ 2157051904 WSMR_WiFiAssnReq 10;
BA_ "GenSigSendOnInit" SG_ 2157051904 WSMR_WiFiAssnReq 1;
BA_ "SignalType" SG_ 2157051904 WSMR_WiFiAssnReq "ENM";
BA_ "PacketOrder" SG_ 2157051904 WSMR_WiFiAssnReq 1;
BA_ "SignalLongName" SG_ 2157051904 WSMR_WiFiAssnReq "WiFI Station Map Request : WiFi Association Request";
BA_ "VNSigAllNodes" SG_ 2157051904 WSMR_WiFiAssnReq 1;
BA_ "GenSigSendType" SG_ 2156994560 WAPDM_SecurityType 10;
BA_ "GenSigSendOnInit" SG_ 2156994560 WAPDM_SecurityType 2;
BA_ "SignalType" SG_ 2156994560 WAPDM_SecurityType "ENM";
BA_ "PacketOrder" SG_ 2156994560 WAPDM_SecurityType 2;
BA_ "SignalLongName" SG_ 2156994560 WAPDM_SecurityType "WiFi Access Point Data Map : Security Type";
BA_ "VNSigAllNodes" SG_ 2156994560 WAPDM_SecurityType 1;
BA_ "GenSigSendType" SG_ 2156994560 WAPDM_WiFiEnStat 10;
BA_ "GenSigSendOnInit" SG_ 2156994560 WAPDM_WiFiEnStat 2;
BA_ "SignalType" SG_ 2156994560 WAPDM_WiFiEnStat "ENM";
BA_ "PacketOrder" SG_ 2156994560 WAPDM_WiFiEnStat 1;
BA_ "SignalLongName" SG_ 2156994560 WAPDM_WiFiEnStat "WiFi Access Point Data Map : WiFi Enabled Status";
BA_ "VNSigAllNodes" SG_ 2156994560 WAPDM_WiFiEnStat 1;
BA_ "GenSigSendType" SG_ 2156994560 WAPDM_EncrptnType 10;
BA_ "GenSigSendOnInit" SG_ 2156994560 WAPDM_EncrptnType 2;
BA_ "SignalType" SG_ 2156994560 WAPDM_EncrptnType "ENM";
BA_ "PacketOrder" SG_ 2156994560 WAPDM_EncrptnType 3;
BA_ "SignalLongName" SG_ 2156994560 WAPDM_EncrptnType "WiFi Access Point Data Map : Encryption Type";
BA_ "VNSigAllNodes" SG_ 2156994560 WAPDM_EncrptnType 1;
BA_ "GenSigSendType" SG_ 2158133248 ChrgCmpltFstChgingAct 10;
BA_ "GenSigSendOnInit" SG_ 2158133248 ChrgCmpltFstChgingAct 1;
BA_ "VNSigInfotainment" SG_ 2158133248 ChrgCmpltFstChgingAct 1;
BA_ "SignalType" SG_ 2158133248 ChrgCmpltFstChgingAct "BLN";
BA_ "SignalLongName" SG_ 2158133248 ChrgCmpltFstChgingAct "Charge Complete Fast Charging Active";
BA_ "VNSigAllNodes" SG_ 2158133248 ChrgCmpltFstChgingAct 1;
BA_ "GenSigDeltaValue" SG_ 2158133248 TgtChrgLvlPctgCurStValPKIn 1;
BA_ "GenSigSendType" SG_ 2158133248 TgtChrgLvlPctgCurStValPKIn 12;
BA_ "GenSigSendOnInit" SG_ 2158133248 TgtChrgLvlPctgCurStValPKIn 1;
BA_ "SignalType" SG_ 2158133248 TgtChrgLvlPctgCurStValPKIn "UNM";
BA_ "SignalLongName" SG_ 2158133248 TgtChrgLvlPctgCurStValPKIn "Target Charge Level Percentage Current Setting Value for Peek In";
BA_ "VNSigAllNodes" SG_ 2158133248 TgtChrgLvlPctgCurStValPKIn 1;
BA_ "GenSigSendType" SG_ 2158133248 TrgtChrgLvlAct 10;
BA_ "GenSigSendOnInit" SG_ 2158133248 TrgtChrgLvlAct 1;
BA_ "SignalType" SG_ 2158133248 TrgtChrgLvlAct "BLN";
BA_ "SignalLongName" SG_ 2158133248 TrgtChrgLvlAct "Target Charge Level Active";
BA_ "VNSigAllNodes" SG_ 2158133248 TrgtChrgLvlAct 1;
BA_ "GenSigDeltaValue" SG_ 2158133248 HVDpltnMdMiCnfdcRgExt 1;
BA_ "GenSigSendType" SG_ 2158133248 HVDpltnMdMiCnfdcRgExt 12;
BA_ "GenSigSendOnInit" SG_ 2158133248 HVDpltnMdMiCnfdcRgExt 1;
BA_ "SignalType" SG_ 2158133248 HVDpltnMdMiCnfdcRgExt "UNM";
BA_ "SignalLongName" SG_ 2158133248 HVDpltnMdMiCnfdcRgExt "High Voltage Depletion Mode Minimum Confidence Range Extended";
BA_ "VNSigAllNodes" SG_ 2158133248 HVDpltnMdMiCnfdcRgExt 1;
BA_ "GenSigDeltaValue" SG_ 2158133248 HVDpltnMdMxCnfdcRgExt 1;
BA_ "GenSigSendType" SG_ 2158133248 HVDpltnMdMxCnfdcRgExt 12;
BA_ "GenSigSendOnInit" SG_ 2158133248 HVDpltnMdMxCnfdcRgExt 1;
BA_ "SignalType" SG_ 2158133248 HVDpltnMdMxCnfdcRgExt "UNM";
BA_ "SignalLongName" SG_ 2158133248 HVDpltnMdMxCnfdcRgExt "High Voltage Depletion Mode Maximum Confidence Range Extended";
BA_ "VNSigAllNodes" SG_ 2158133248 HVDpltnMdMxCnfdcRgExt 1;
BA_ "GenSigSendType" SG_ 2158133248 HTRCsStAvail 10;
BA_ "GenSigSendOnInit" SG_ 2158133248 HTRCsStAvail 1;
BA_ "VNSigInfotainment" SG_ 2158133248 HTRCsStAvail 1;
BA_ "SignalType" SG_ 2158133248 HTRCsStAvail "BLN";
BA_ "SignalLongName" SG_ 2158133248 HTRCsStAvail "Hill Top Reserve Customization Setting Available";
BA_ "VNSigAllNodes" SG_ 2158133248 HTRCsStAvail 1;
BA_ "GenSigSendType" SG_ 2158133248 HTRCsCrStVal 10;
BA_ "GenSigSendOnInit" SG_ 2158133248 HTRCsCrStVal 1;
BA_ "VNSigInfotainment" SG_ 2158133248 HTRCsCrStVal 1;
BA_ "SignalType" SG_ 2158133248 HTRCsCrStVal "ENM";
BA_ "SignalLongName" SG_ 2158133248 HTRCsCrStVal "Hill Top Reserve Customization Current Setting Value";
BA_ "VNSigAllNodes" SG_ 2158133248 HTRCsCrStVal 1;
BA_ "GenSigSendType" SG_ 2158133248 HTRCA_Res3Avail 10;
BA_ "GenSigSendOnInit" SG_ 2158133248 HTRCA_Res3Avail 1;
BA_ "VNSigInfotainment" SG_ 2158133248 HTRCA_Res3Avail 1;
BA_ "SignalType" SG_ 2158133248 HTRCA_Res3Avail "BLN";
BA_ "PacketOrder" SG_ 2158133248 HTRCA_Res3Avail 7;
BA_ "SignalLongName" SG_ 2158133248 HTRCA_Res3Avail "Hill Top Reserve Customization Available : Reserved3 Available";
BA_ "VNSigAllNodes" SG_ 2158133248 HTRCA_Res3Avail 1;
BA_ "GenSigSendType" SG_ 2158133248 HTRCA_Res2Avail 10;
BA_ "GenSigSendOnInit" SG_ 2158133248 HTRCA_Res2Avail 1;
BA_ "VNSigInfotainment" SG_ 2158133248 HTRCA_Res2Avail 1;
BA_ "SignalType" SG_ 2158133248 HTRCA_Res2Avail "BLN";
BA_ "PacketOrder" SG_ 2158133248 HTRCA_Res2Avail 6;
BA_ "SignalLongName" SG_ 2158133248 HTRCA_Res2Avail "Hill Top Reserve Customization Available : Reserved2 Available";
BA_ "VNSigAllNodes" SG_ 2158133248 HTRCA_Res2Avail 1;
BA_ "GenSigSendType" SG_ 2158133248 HTRCA_Res1Avail 10;
BA_ "GenSigSendOnInit" SG_ 2158133248 HTRCA_Res1Avail 1;
BA_ "VNSigInfotainment" SG_ 2158133248 HTRCA_Res1Avail 1;
BA_ "SignalType" SG_ 2158133248 HTRCA_Res1Avail "BLN";
BA_ "PacketOrder" SG_ 2158133248 HTRCA_Res1Avail 5;
BA_ "SignalLongName" SG_ 2158133248 HTRCA_Res1Avail "Hill Top Reserve Customization Available : Reserved1 Available";
BA_ "VNSigAllNodes" SG_ 2158133248 HTRCA_Res1Avail 1;
BA_ "GenSigSendType" SG_ 2158133248 HTRCA_OnAwAvail 10;
BA_ "GenSigSendOnInit" SG_ 2158133248 HTRCA_OnAwAvail 1;
BA_ "VNSigInfotainment" SG_ 2158133248 HTRCA_OnAwAvail 1;
BA_ "SignalType" SG_ 2158133248 HTRCA_OnAwAvail "BLN";
BA_ "PacketOrder" SG_ 2158133248 HTRCA_OnAwAvail 4;
BA_ "SignalLongName" SG_ 2158133248 HTRCA_OnAwAvail "Hill Top Reserve Customization Available : On Away Available";
BA_ "VNSigAllNodes" SG_ 2158133248 HTRCA_OnAwAvail 1;
BA_ "GenSigSendType" SG_ 2158133248 HTRCA_OnHmAvail 10;
BA_ "GenSigSendOnInit" SG_ 2158133248 HTRCA_OnHmAvail 1;
BA_ "VNSigInfotainment" SG_ 2158133248 HTRCA_OnHmAvail 1;
BA_ "SignalType" SG_ 2158133248 HTRCA_OnHmAvail "BLN";
BA_ "PacketOrder" SG_ 2158133248 HTRCA_OnHmAvail 3;
BA_ "SignalLongName" SG_ 2158133248 HTRCA_OnHmAvail "Hill Top Reserve Customization Available : On Home Available";
BA_ "VNSigAllNodes" SG_ 2158133248 HTRCA_OnHmAvail 1;
BA_ "GenSigSendType" SG_ 2158133248 HTRCA_OnAvail 10;
BA_ "GenSigSendOnInit" SG_ 2158133248 HTRCA_OnAvail 1;
BA_ "VNSigInfotainment" SG_ 2158133248 HTRCA_OnAvail 1;
BA_ "SignalType" SG_ 2158133248 HTRCA_OnAvail "BLN";
BA_ "PacketOrder" SG_ 2158133248 HTRCA_OnAvail 2;
BA_ "SignalLongName" SG_ 2158133248 HTRCA_OnAvail "Hill Top Reserve Customization Available : On Available";
BA_ "VNSigAllNodes" SG_ 2158133248 HTRCA_OnAvail 1;
BA_ "GenSigSendType" SG_ 2158133248 HTRCA_OffAvail 10;
BA_ "GenSigSendOnInit" SG_ 2158133248 HTRCA_OffAvail 1;
BA_ "VNSigInfotainment" SG_ 2158133248 HTRCA_OffAvail 1;
BA_ "SignalType" SG_ 2158133248 HTRCA_OffAvail "BLN";
BA_ "PacketOrder" SG_ 2158133248 HTRCA_OffAvail 1;
BA_ "SignalLongName" SG_ 2158133248 HTRCA_OffAvail "Hill Top Reserve Customization Available : Off Available";
BA_ "VNSigAllNodes" SG_ 2158133248 HTRCA_OffAvail 1;
BA_ "GenSigSendType" SG_ 2154651648 TAC_AudConctOutcm 10;
BA_ "GenSigSendOnInit" SG_ 2154651648 TAC_AudConctOutcm 1;
BA_ "PacketOrder" SG_ 2154651648 TAC_AudConctOutcm 2;
BA_ "VNSigInfotainment" SG_ 2154651648 TAC_AudConctOutcm 1;
BA_ "SignalType" SG_ 2154651648 TAC_AudConctOutcm "ENM";
BA_ "SignalLongName" SG_ 2154651648 TAC_AudConctOutcm "Telematics Audio Control : Audio Connection Outcome";
BA_ "VNSigAllNodes" SG_ 2154651648 TAC_AudConctOutcm 1;
BA_ "GenSigSendType" SG_ 2154651648 TAC_AudChConctStat 10;
BA_ "GenSigSendOnInit" SG_ 2154651648 TAC_AudChConctStat 1;
BA_ "PacketOrder" SG_ 2154651648 TAC_AudChConctStat 1;
BA_ "VNSigInfotainment" SG_ 2154651648 TAC_AudChConctStat 1;
BA_ "SignalType" SG_ 2154651648 TAC_AudChConctStat "ENM";
BA_ "SignalLongName" SG_ 2154651648 TAC_AudChConctStat "Telematics Audio Control : Audio Channel Connection Status";
BA_ "VNSigAllNodes" SG_ 2154651648 TAC_AudChConctStat 1;
BA_ "GenSigSendType" SG_ 2154635264 TAR_AudSrcStat 10;
BA_ "GenSigSendOnInit" SG_ 2154635264 TAR_AudSrcStat 1;
BA_ "PacketOrder" SG_ 2154635264 TAR_AudSrcStat 2;
BA_ "VNSigInfotainment" SG_ 2154635264 TAR_AudSrcStat 1;
BA_ "SignalType" SG_ 2154635264 TAR_AudSrcStat "ENM";
BA_ "SignalLongName" SG_ 2154635264 TAR_AudSrcStat "Telematics Audio Request : Audio Source Status";
BA_ "VNSigAllNodes" SG_ 2154635264 TAR_AudSrcStat 1;
BA_ "GenSigSendType" SG_ 2154635264 TAR_AudConctReq 10;
BA_ "GenSigSendOnInit" SG_ 2154635264 TAR_AudConctReq 1;
BA_ "PacketOrder" SG_ 2154635264 TAR_AudConctReq 1;
BA_ "VNSigInfotainment" SG_ 2154635264 TAR_AudConctReq 1;
BA_ "SignalType" SG_ 2154635264 TAR_AudConctReq "ENM";
BA_ "SignalLongName" SG_ 2154635264 TAR_AudConctReq "Telematics Audio Request : Audio Connection Request";
BA_ "VNSigAllNodes" SG_ 2154635264 TAR_AudConctReq 1;
BA_ "GenSigSendType" SG_ 2152529920 LVMAVC_SpchRcgnAval 10;
BA_ "GenSigSendOnInit" SG_ 2152529920 LVMAVC_SpchRcgnAval 1;
BA_ "PacketOrder" SG_ 2152529920 LVMAVC_SpchRcgnAval 6;
BA_ "VNSigInfotainment" SG_ 2152529920 LVMAVC_SpchRcgnAval 1;
BA_ "SignalType" SG_ 2152529920 LVMAVC_SpchRcgnAval "ENM";
BA_ "SignalLongName" SG_ 2152529920 LVMAVC_SpchRcgnAval "Low Volume Module Audio Video Command : Speech Recognition Available";
BA_ "VNSigAllNodes" SG_ 2152529920 LVMAVC_SpchRcgnAval 1;
BA_ "GenSigSendType" SG_ 2152529920 LVMAVC_RemSpchRcgnActn 10;
BA_ "GenSigSendOnInit" SG_ 2152529920 LVMAVC_RemSpchRcgnActn 1;
BA_ "PacketOrder" SG_ 2152529920 LVMAVC_RemSpchRcgnActn 5;
BA_ "VNSigInfotainment" SG_ 2152529920 LVMAVC_RemSpchRcgnActn 1;
BA_ "SignalType" SG_ 2152529920 LVMAVC_RemSpchRcgnActn "ENM";
BA_ "SignalLongName" SG_ 2152529920 LVMAVC_RemSpchRcgnActn "Low Volume Module Audio Video Command : Remote Speech Recognition Action";
BA_ "VNSigAllNodes" SG_ 2152529920 LVMAVC_RemSpchRcgnActn 1;
BA_ "GenSigSendType" SG_ 2152529920 LVMAVC_RemSpchRcgnID 10;
BA_ "GenSigSendOnInit" SG_ 2152529920 LVMAVC_RemSpchRcgnID 1;
BA_ "PacketOrder" SG_ 2152529920 LVMAVC_RemSpchRcgnID 4;
BA_ "VNSigInfotainment" SG_ 2152529920 LVMAVC_RemSpchRcgnID 1;
BA_ "SignalType" SG_ 2152529920 LVMAVC_RemSpchRcgnID "ENM";
BA_ "SignalLongName" SG_ 2152529920 LVMAVC_RemSpchRcgnID "Low Volume Module Audio Video Command : Remote Speech Recognition ID";
BA_ "VNSigAllNodes" SG_ 2152529920 LVMAVC_RemSpchRcgnID 1;
BA_ "GenSigSendType" SG_ 2152529920 LVMAVC_StreoAudRsp 10;
BA_ "GenSigSendOnInit" SG_ 2152529920 LVMAVC_StreoAudRsp 1;
BA_ "PacketOrder" SG_ 2152529920 LVMAVC_StreoAudRsp 3;
BA_ "VNSigInfotainment" SG_ 2152529920 LVMAVC_StreoAudRsp 1;
BA_ "SignalType" SG_ 2152529920 LVMAVC_StreoAudRsp "ENM";
BA_ "SignalLongName" SG_ 2152529920 LVMAVC_StreoAudRsp "Low Volume Module Audio Video Command : Stereo Audio Response";
BA_ "VNSigAllNodes" SG_ 2152529920 LVMAVC_StreoAudRsp 1;
BA_ "GenSigSendType" SG_ 2152529920 LVMAVC_PrmtAudRsp 10;
BA_ "GenSigSendOnInit" SG_ 2152529920 LVMAVC_PrmtAudRsp 1;
BA_ "PacketOrder" SG_ 2152529920 LVMAVC_PrmtAudRsp 2;
BA_ "VNSigInfotainment" SG_ 2152529920 LVMAVC_PrmtAudRsp 1;
BA_ "SignalType" SG_ 2152529920 LVMAVC_PrmtAudRsp "ENM";
BA_ "SignalLongName" SG_ 2152529920 LVMAVC_PrmtAudRsp "Low Volume Module Audio Video Command : Prompt Audio Response";
BA_ "VNSigAllNodes" SG_ 2152529920 LVMAVC_PrmtAudRsp 1;
BA_ "GenSigSendType" SG_ 2152529920 LVMAVC_RemtEnbl 10;
BA_ "GenSigSendOnInit" SG_ 2152529920 LVMAVC_RemtEnbl 1;
BA_ "PacketOrder" SG_ 2152529920 LVMAVC_RemtEnbl 1;
BA_ "VNSigInfotainment" SG_ 2152529920 LVMAVC_RemtEnbl 1;
BA_ "SignalType" SG_ 2152529920 LVMAVC_RemtEnbl "ENM";
BA_ "SignalLongName" SG_ 2152529920 LVMAVC_RemtEnbl "Low Volume Module Audio Video Command : Remote Enable";
BA_ "VNSigAllNodes" SG_ 2152529920 LVMAVC_RemtEnbl 1;
BA_ "GenSigSendType" SG_ 2152513536 LVMAVR_SpchRcgnAct 10;
BA_ "GenSigSendOnInit" SG_ 2152513536 LVMAVR_SpchRcgnAct 1;
BA_ "PacketOrder" SG_ 2152513536 LVMAVR_SpchRcgnAct 4;
BA_ "VNSigInfotainment" SG_ 2152513536 LVMAVR_SpchRcgnAct 1;
BA_ "SignalType" SG_ 2152513536 LVMAVR_SpchRcgnAct "ENM";
BA_ "SignalLongName" SG_ 2152513536 LVMAVR_SpchRcgnAct "Low Volume Module Audio Video Request : Speech Recognition Active";
BA_ "VNSigAllNodes" SG_ 2152513536 LVMAVR_SpchRcgnAct 1;
BA_ "GenSigSendType" SG_ 2152513536 LVMAVR_PrmtAudReq 10;
BA_ "GenSigSendOnInit" SG_ 2152513536 LVMAVR_PrmtAudReq 1;
BA_ "PacketOrder" SG_ 2152513536 LVMAVR_PrmtAudReq 3;
BA_ "VNSigInfotainment" SG_ 2152513536 LVMAVR_PrmtAudReq 1;
BA_ "SignalType" SG_ 2152513536 LVMAVR_PrmtAudReq "ENM";
BA_ "SignalLongName" SG_ 2152513536 LVMAVR_PrmtAudReq "Low Volume Module Audio Video Request : Prompt Audio Request";
BA_ "VNSigAllNodes" SG_ 2152513536 LVMAVR_PrmtAudReq 1;
BA_ "GenSigSendType" SG_ 2152513536 LVMAVR_StreoAudReq 10;
BA_ "GenSigSendOnInit" SG_ 2152513536 LVMAVR_StreoAudReq 1;
BA_ "PacketOrder" SG_ 2152513536 LVMAVR_StreoAudReq 2;
BA_ "VNSigInfotainment" SG_ 2152513536 LVMAVR_StreoAudReq 1;
BA_ "SignalType" SG_ 2152513536 LVMAVR_StreoAudReq "ENM";
BA_ "SignalLongName" SG_ 2152513536 LVMAVR_StreoAudReq "Low Volume Module Audio Video Request : Stereo Audio Request";
BA_ "VNSigAllNodes" SG_ 2152513536 LVMAVR_StreoAudReq 1;
BA_ "GenSigSendType" SG_ 2152513536 LVMAVR_DispReq 10;
BA_ "GenSigSendOnInit" SG_ 2152513536 LVMAVR_DispReq 1;
BA_ "PacketOrder" SG_ 2152513536 LVMAVR_DispReq 1;
BA_ "VNSigInfotainment" SG_ 2152513536 LVMAVR_DispReq 1;
BA_ "SignalType" SG_ 2152513536 LVMAVR_DispReq "ENM";
BA_ "SignalLongName" SG_ 2152513536 LVMAVR_DispReq "Low Volume Module Audio Video Request : Display Request";
BA_ "VNSigAllNodes" SG_ 2152513536 LVMAVR_DispReq 1;
BA_ "GenSigSendType" SG_ 2154889216 RSIHMIAnmReq 10;
BA_ "GenSigSendOnInit" SG_ 2154889216 RSIHMIAnmReq 1;
BA_ "VNSigInfotainment" SG_ 2154889216 RSIHMIAnmReq 1;
BA_ "SignalType" SG_ 2154889216 RSIHMIAnmReq "ENM";
BA_ "SignalLongName" SG_ 2154889216 RSIHMIAnmReq "Rear Seat Infotainment Human Machine Interface Animation Request";
BA_ "VNSigAllNodes" SG_ 2154889216 RSIHMIAnmReq 1;
BA_ "GenSigSendType" SG_ 2154889216 ClstrHMIAnmReq 10;
BA_ "VNSigInfotainment" SG_ 2154889216 ClstrHMIAnmReq 1;
BA_ "SignalType" SG_ 2154889216 ClstrHMIAnmReq "ENM";
BA_ "SignalLongName" SG_ 2154889216 ClstrHMIAnmReq "Cluster HMI Animation Request";
BA_ "VNSigAllNodes" SG_ 2154889216 ClstrHMIAnmReq 1;
BA_ "GenSigSendType" SG_ 2154872832 RmRflshUpdtAvail 10;
BA_ "VNSigInfotainment" SG_ 2154872832 RmRflshUpdtAvail 1;
BA_ "SignalType" SG_ 2154872832 RmRflshUpdtAvail "BLN";
BA_ "SignalLongName" SG_ 2154872832 RmRflshUpdtAvail "Remote Reflash Update Available";
BA_ "VNSigAllNodes" SG_ 2154872832 RmRflshUpdtAvail 1;
BA_ "GenSigSendType" SG_ 2154872832 InfoActvnReq 10;
BA_ "VNSigInfotainment" SG_ 2154872832 InfoActvnReq 1;
BA_ "SignalType" SG_ 2154872832 InfoActvnReq "BLN";
BA_ "SignalLongName" SG_ 2154872832 InfoActvnReq "Infotainment Activation Request";
BA_ "VNSigAllNodes" SG_ 2154872832 InfoActvnReq 1;
BA_ "GenSigSendType" SG_ 2156961792 WiFiSSIDDgts17to24_Mp 10;
BA_ "GenSigSendOnInit" SG_ 2156961792 WiFiSSIDDgts17to24_Mp 2;
BA_ "SignalType" SG_ 2156961792 WiFiSSIDDgts17to24_Mp "ASC";
BA_ "SignalLongName" SG_ 2156961792 WiFiSSIDDgts17to24_Mp "WiFi Service Set Identifier Digits 17 to 24 Map";
BA_ "VNSigAllNodes" SG_ 2156961792 WiFiSSIDDgts17to24_Mp 1;
BA_ "GenSigSendType" SG_ 2154569728 InfotnmntSysSt 10;
BA_ "GenSigSendOnInit" SG_ 2154569728 InfotnmntSysSt 1;
BA_ "VNSigInfotainment" SG_ 2154569728 InfotnmntSysSt 1;
BA_ "SignalType" SG_ 2154569728 InfotnmntSysSt "ENM";
BA_ "SignalLongName" SG_ 2154569728 InfotnmntSysSt "Infotainment System State";
BA_ "VNSigAllNodes" SG_ 2154569728 InfotnmntSysSt 1;
BA_ "GenSigSendType" SG_ 2151931904 FourWhlDrvIdReqExtRng 10;
BA_ "GenSigSendOnInit" SG_ 2151931904 FourWhlDrvIdReqExtRng 2;
BA_ "SignalType" SG_ 2151931904 FourWhlDrvIdReqExtRng "ENM";
BA_ "SignalLongName" SG_ 2151931904 FourWhlDrvIdReqExtRng "Four Wheel Drive Indication Request Extended Range";
BA_ "VNSigAllNodes" SG_ 2151931904 FourWhlDrvIdReqExtRng 1;
BA_ "GenSigDeltaValue" SG_ 2151931904 LnchCtrlTmrVal 1;
BA_ "GenSigSendType" SG_ 2151931904 LnchCtrlTmrVal 12;
BA_ "SignalType" SG_ 2151931904 LnchCtrlTmrVal "UNM";
BA_ "SignalLongName" SG_ 2151931904 LnchCtrlTmrVal "Launch Control Timer Value";
BA_ "VNSigAllNodes" SG_ 2151931904 LnchCtrlTmrVal 1;
BA_ "GenSigDeltaValue" SG_ 2151931904 LnchCtrlBrkPresVal 1;
BA_ "GenSigSendType" SG_ 2151931904 LnchCtrlBrkPresVal 12;
BA_ "SignalType" SG_ 2151931904 LnchCtrlBrkPresVal "UNM";
BA_ "SignalLongName" SG_ 2151931904 LnchCtrlBrkPresVal "Launch Control Brake Pressure Value";
BA_ "VNSigAllNodes" SG_ 2151931904 LnchCtrlBrkPresVal 1;
BA_ "GenSigSendType" SG_ 2151931904 FuelMdTrnstnIndReq 10;
BA_ "SignalType" SG_ 2151931904 FuelMdTrnstnIndReq "ENM";
BA_ "SignalLongName" SG_ 2151931904 FuelMdTrnstnIndReq "Fuel Mode Transition Indication Request";
BA_ "VNSigAllNodes" SG_ 2151931904 FuelMdTrnstnIndReq 1;
BA_ "GenSigSendType" SG_ 2151931904 BiFuelRflGaslinIndReq 10;
BA_ "SignalType" SG_ 2151931904 BiFuelRflGaslinIndReq "ENM";
BA_ "SignalLongName" SG_ 2151931904 BiFuelRflGaslinIndReq "Bi Fuel Refill Gasoline Indication Request";
BA_ "VNSigAllNodes" SG_ 2151931904 BiFuelRflGaslinIndReq 1;
BA_ "GenSigDeltaValue" SG_ 2151931904 AutoShtdwnTmr 1;
BA_ "GenSigSendType" SG_ 2151931904 AutoShtdwnTmr 12;
BA_ "SignalType" SG_ 2151931904 AutoShtdwnTmr "UNM";
BA_ "SignalLongName" SG_ 2151931904 AutoShtdwnTmr "Automatic Shutdown Timer";
BA_ "VNSigAllNodes" SG_ 2151931904 AutoShtdwnTmr 1;
BA_ "GenSigSendType" SG_ 2151931904 AutoShtdwnIO 10;
BA_ "SignalType" SG_ 2151931904 AutoShtdwnIO "BLN";
BA_ "SignalLongName" SG_ 2151931904 AutoShtdwnIO "Automatic Shutdown Indication On";
BA_ "VNSigAllNodes" SG_ 2151931904 AutoShtdwnIO 1;
BA_ "GenSigSendType" SG_ 2151931904 TCSTempDsblReqIO 10;
BA_ "GenSigSendOnInit" SG_ 2151931904 TCSTempDsblReqIO 2;
BA_ "SignalType" SG_ 2151931904 TCSTempDsblReqIO "BLN";
BA_ "SignalLongName" SG_ 2151931904 TCSTempDsblReqIO "Traction Control System Temporary Disable Request Indication On";
BA_ "VNSigAllNodes" SG_ 2151931904 TCSTempDsblReqIO 1;
BA_ "GenSigSendType" SG_ 2151931904 VehStbCmptvMdCstAvl 10;
BA_ "GenSigSendOnInit" SG_ 2151931904 VehStbCmptvMdCstAvl 2;
BA_ "SignalType" SG_ 2151931904 VehStbCmptvMdCstAvl "BLN";
BA_ "SignalLongName" SG_ 2151931904 VehStbCmptvMdCstAvl "Vehicle Stability Competitive Mode Customization Available";
BA_ "VNSigAllNodes" SG_ 2151931904 VehStbCmptvMdCstAvl 1;
BA_ "GenSigSendType" SG_ 2151931904 VehStbEnmntCstAvl 10;
BA_ "GenSigSendOnInit" SG_ 2151931904 VehStbEnmntCstAvl 2;
BA_ "SignalType" SG_ 2151931904 VehStbEnmntCstAvl "BLN";
BA_ "SignalLongName" SG_ 2151931904 VehStbEnmntCstAvl "Vehicle Stability Enhancement Customization Available";
BA_ "VNSigAllNodes" SG_ 2151931904 VehStbEnmntCstAvl 1;
BA_ "GenSigSendType" SG_ 2151931904 TCSysCstAvl 10;
BA_ "GenSigSendOnInit" SG_ 2151931904 TCSysCstAvl 2;
BA_ "SignalType" SG_ 2151931904 TCSysCstAvl "BLN";
BA_ "SignalLongName" SG_ 2151931904 TCSysCstAvl "Traction Control System Customization Available";
BA_ "VNSigAllNodes" SG_ 2151931904 TCSysCstAvl 1;
BA_ "GenSigSendType" SG_ 2151931904 VehStbCmptvMdCurSt 10;
BA_ "GenSigSendOnInit" SG_ 2151931904 VehStbCmptvMdCurSt 2;
BA_ "SignalType" SG_ 2151931904 VehStbCmptvMdCurSt "ENM";
BA_ "SignalLongName" SG_ 2151931904 VehStbCmptvMdCurSt "Vehicle Stability Competitive Mode Current State";
BA_ "VNSigAllNodes" SG_ 2151931904 VehStbCmptvMdCurSt 1;
BA_ "GenSigSendType" SG_ 2151931904 VehStbEnhmntCurSt 10;
BA_ "GenSigSendOnInit" SG_ 2151931904 VehStbEnhmntCurSt 2;
BA_ "SignalType" SG_ 2151931904 VehStbEnhmntCurSt "ENM";
BA_ "SignalLongName" SG_ 2151931904 VehStbEnhmntCurSt "Vehicle Stability Enhancement Current State";
BA_ "VNSigAllNodes" SG_ 2151931904 VehStbEnhmntCurSt 1;
BA_ "GenSigSendType" SG_ 2151931904 TCSysCurSt 10;
BA_ "GenSigSendOnInit" SG_ 2151931904 TCSysCurSt 2;
BA_ "SignalType" SG_ 2151931904 TCSysCurSt "ENM";
BA_ "SignalLongName" SG_ 2151931904 TCSysCurSt "Traction Control System Current State";
BA_ "VNSigAllNodes" SG_ 2151931904 TCSysCurSt 1;
BA_ "GenSigSendType" SG_ 2151931904 TracAndStbScrnCnfg 10;
BA_ "GenSigSendOnInit" SG_ 2151931904 TracAndStbScrnCnfg 2;
BA_ "SignalType" SG_ 2151931904 TracAndStbScrnCnfg "ENM";
BA_ "SignalLongName" SG_ 2151931904 TracAndStbScrnCnfg "Traction And Stability Screen Configuration";
BA_ "VNSigAllNodes" SG_ 2151931904 TracAndStbScrnCnfg 1;
BA_ "GenSigSendType" SG_ 2151931904 ElctShfPriLtdPerfMdIO 10;
BA_ "SignalType" SG_ 2151931904 ElctShfPriLtdPerfMdIO "BLN";
BA_ "SignalLongName" SG_ 2151931904 ElctShfPriLtdPerfMdIO "Electronic Shift Primary Limited Performance Mode Indication On";
BA_ "VNSigAllNodes" SG_ 2151931904 ElctShfPriLtdPerfMdIO 1;
BA_ "GenSigSendType" SG_ 2151931904 LnchCtrlWhlSlpStat 10;
BA_ "SignalType" SG_ 2151931904 LnchCtrlWhlSlpStat "ENM";
BA_ "SignalLongName" SG_ 2151931904 LnchCtrlWhlSlpStat "Launch Control Wheel Slip Status";
BA_ "VNSigAllNodes" SG_ 2151931904 LnchCtrlWhlSlpStat 1;
BA_ "GenSigSendType" SG_ 2151931904 LnchCtrlMdStat 10;
BA_ "SignalType" SG_ 2151931904 LnchCtrlMdStat "ENM";
BA_ "SignalLongName" SG_ 2151931904 LnchCtrlMdStat "Launch Control Mode Status";
BA_ "VNSigAllNodes" SG_ 2151931904 LnchCtrlMdStat 1;
BA_ "GenSigSendType" SG_ 2151931904 LnchCtrlEngRPMStat 10;
BA_ "SignalType" SG_ 2151931904 LnchCtrlEngRPMStat "ENM";
BA_ "SignalLongName" SG_ 2151931904 LnchCtrlEngRPMStat "Launch Control Engine RPM Status";
BA_ "VNSigAllNodes" SG_ 2151931904 LnchCtrlEngRPMStat 1;
BA_ "GenSigSendType" SG_ 2151931904 RegVltCtlEngyRcvryAct 10;
BA_ "SignalType" SG_ 2151931904 RegVltCtlEngyRcvryAct "BLN";
BA_ "SignalLongName" SG_ 2151931904 RegVltCtlEngyRcvryAct "Regulated Voltage Control Energy Recovery Active";
BA_ "VNSigAllNodes" SG_ 2151931904 RegVltCtlEngyRcvryAct 1;
BA_ "GenSigSendType" SG_ 2151931904 VehSpdCntlSystmType 10;
BA_ "SignalType" SG_ 2151931904 VehSpdCntlSystmType "ENM";
BA_ "SignalLongName" SG_ 2151931904 VehSpdCntlSystmType "Vehicle Speed Control System Type";
BA_ "VNSigAllNodes" SG_ 2151931904 VehSpdCntlSystmType 1;
BA_ "GenSigSendType" SG_ 2151931904 ACCSysSltdMdDispIO 10;
BA_ "GenSigSendOnInit" SG_ 2151931904 ACCSysSltdMdDispIO 2;
BA_ "SignalType" SG_ 2151931904 ACCSysSltdMdDispIO "BLN";
BA_ "SignalLongName" SG_ 2151931904 ACCSysSltdMdDispIO "Adaptive Cruise Control System Selected Mode Display Indication On";
BA_ "VNSigAllNodes" SG_ 2151931904 ACCSysSltdMdDispIO 1;
BA_ "GenSigSendType" SG_ 2151931904 ACCSysSltdMd 10;
BA_ "GenSigSendOnInit" SG_ 2151931904 ACCSysSltdMd 2;
BA_ "SignalType" SG_ 2151931904 ACCSysSltdMd "ENM";
BA_ "SignalLongName" SG_ 2151931904 ACCSysSltdMd "Adaptive Cruise Control System Selected Mode";
BA_ "VNSigAllNodes" SG_ 2151931904 ACCSysSltdMd 1;
BA_ "GenSigSendType" SG_ 2151931904 PTExPrtclFltWrng3IO 10;
BA_ "SignalType" SG_ 2151931904 PTExPrtclFltWrng3IO "BLN";
BA_ "SignalLongName" SG_ 2151931904 PTExPrtclFltWrng3IO "Powertrain Exhaust Particle Filter Warning 3 Indication On";
BA_ "VNSigAllNodes" SG_ 2151931904 PTExPrtclFltWrng3IO 1;
BA_ "GenSigSendType" SG_ 2151931904 PTExPartFltManRegStat 10;
BA_ "SignalType" SG_ 2151931904 PTExPartFltManRegStat "ENM";
BA_ "SignalLongName" SG_ 2151931904 PTExPartFltManRegStat "Powertrain Exhaust Particle Filter Manual Regeneration Status";
BA_ "VNSigAllNodes" SG_ 2151931904 PTExPartFltManRegStat 1;
BA_ "GenSigSendType" SG_ 2151931904 AWDRecmndIO 10;
BA_ "SignalType" SG_ 2151931904 AWDRecmndIO "BLN";
BA_ "SignalLongName" SG_ 2151931904 AWDRecmndIO "All Wheel Drive Recommended Indication On";
BA_ "VNSigAllNodes" SG_ 2151931904 AWDRecmndIO 1;
BA_ "GenSigDeltaValue" SG_ 2150244352 ECHGDDV_Col10 1;
BA_ "GenSigSendType" SG_ 2150244352 ECHGDDV_Col10 12;
BA_ "GenSigSendOnInit" SG_ 2150244352 ECHGDDV_Col10 1;
BA_ "PacketOrder" SG_ 2150244352 ECHGDDV_Col10 11;
BA_ "VNSigInfotainment" SG_ 2150244352 ECHGDDV_Col10 1;
BA_ "SignalType" SG_ 2150244352 ECHGDDV_Col10 "UNM";
BA_ "SignalLongName" SG_ 2150244352 ECHGDDV_Col10 "Energy Consumption History Graph Display Data Values : Column 10";
BA_ "VNSigAllNodes" SG_ 2150244352 ECHGDDV_Col10 1;
BA_ "GenSigDeltaValue" SG_ 2150244352 ECHGDDV_Col9 1;
BA_ "GenSigSendType" SG_ 2150244352 ECHGDDV_Col9 12;
BA_ "GenSigSendOnInit" SG_ 2150244352 ECHGDDV_Col9 1;
BA_ "PacketOrder" SG_ 2150244352 ECHGDDV_Col9 10;
BA_ "VNSigInfotainment" SG_ 2150244352 ECHGDDV_Col9 1;
BA_ "SignalType" SG_ 2150244352 ECHGDDV_Col9 "UNM";
BA_ "SignalLongName" SG_ 2150244352 ECHGDDV_Col9 "Energy Consumption History Graph Display Data Values : Column 09";
BA_ "VNSigAllNodes" SG_ 2150244352 ECHGDDV_Col9 1;
BA_ "GenSigDeltaValue" SG_ 2150244352 ECHGDDV_Col8 1;
BA_ "GenSigSendType" SG_ 2150244352 ECHGDDV_Col8 12;
BA_ "GenSigSendOnInit" SG_ 2150244352 ECHGDDV_Col8 1;
BA_ "PacketOrder" SG_ 2150244352 ECHGDDV_Col8 9;
BA_ "VNSigInfotainment" SG_ 2150244352 ECHGDDV_Col8 1;
BA_ "SignalType" SG_ 2150244352 ECHGDDV_Col8 "UNM";
BA_ "SignalLongName" SG_ 2150244352 ECHGDDV_Col8 "Energy Consumption History Graph Display Data Values : Column 08";
BA_ "VNSigAllNodes" SG_ 2150244352 ECHGDDV_Col8 1;
BA_ "GenSigDeltaValue" SG_ 2150244352 ECHGDDV_Col7 1;
BA_ "GenSigSendType" SG_ 2150244352 ECHGDDV_Col7 12;
BA_ "GenSigSendOnInit" SG_ 2150244352 ECHGDDV_Col7 1;
BA_ "PacketOrder" SG_ 2150244352 ECHGDDV_Col7 8;
BA_ "VNSigInfotainment" SG_ 2150244352 ECHGDDV_Col7 1;
BA_ "SignalType" SG_ 2150244352 ECHGDDV_Col7 "UNM";
BA_ "SignalLongName" SG_ 2150244352 ECHGDDV_Col7 "Energy Consumption History Graph Display Data Values : Column 07";
BA_ "VNSigAllNodes" SG_ 2150244352 ECHGDDV_Col7 1;
BA_ "GenSigDeltaValue" SG_ 2150244352 ECHGDDV_Col6 1;
BA_ "GenSigSendType" SG_ 2150244352 ECHGDDV_Col6 12;
BA_ "GenSigSendOnInit" SG_ 2150244352 ECHGDDV_Col6 1;
BA_ "PacketOrder" SG_ 2150244352 ECHGDDV_Col6 7;
BA_ "VNSigInfotainment" SG_ 2150244352 ECHGDDV_Col6 1;
BA_ "SignalType" SG_ 2150244352 ECHGDDV_Col6 "UNM";
BA_ "SignalLongName" SG_ 2150244352 ECHGDDV_Col6 "Energy Consumption History Graph Display Data Values : Column 06";
BA_ "VNSigAllNodes" SG_ 2150244352 ECHGDDV_Col6 1;
BA_ "GenSigDeltaValue" SG_ 2150244352 ECHGDDV_Col5 1;
BA_ "GenSigSendType" SG_ 2150244352 ECHGDDV_Col5 12;
BA_ "GenSigSendOnInit" SG_ 2150244352 ECHGDDV_Col5 1;
BA_ "PacketOrder" SG_ 2150244352 ECHGDDV_Col5 6;
BA_ "VNSigInfotainment" SG_ 2150244352 ECHGDDV_Col5 1;
BA_ "SignalType" SG_ 2150244352 ECHGDDV_Col5 "UNM";
BA_ "SignalLongName" SG_ 2150244352 ECHGDDV_Col5 "Energy Consumption History Graph Display Data Values : Column 05";
BA_ "VNSigAllNodes" SG_ 2150244352 ECHGDDV_Col5 1;
BA_ "GenSigDeltaValue" SG_ 2150244352 ECHGDDV_Col4 1;
BA_ "GenSigSendType" SG_ 2150244352 ECHGDDV_Col4 12;
BA_ "GenSigSendOnInit" SG_ 2150244352 ECHGDDV_Col4 1;
BA_ "PacketOrder" SG_ 2150244352 ECHGDDV_Col4 5;
BA_ "VNSigInfotainment" SG_ 2150244352 ECHGDDV_Col4 1;
BA_ "SignalType" SG_ 2150244352 ECHGDDV_Col4 "UNM";
BA_ "SignalLongName" SG_ 2150244352 ECHGDDV_Col4 "Energy Consumption History Graph Display Data Values : Column 04";
BA_ "VNSigAllNodes" SG_ 2150244352 ECHGDDV_Col4 1;
BA_ "GenSigDeltaValue" SG_ 2150244352 ECHGDDV_Col3 1;
BA_ "GenSigSendType" SG_ 2150244352 ECHGDDV_Col3 12;
BA_ "GenSigSendOnInit" SG_ 2150244352 ECHGDDV_Col3 1;
BA_ "PacketOrder" SG_ 2150244352 ECHGDDV_Col3 4;
BA_ "VNSigInfotainment" SG_ 2150244352 ECHGDDV_Col3 1;
BA_ "SignalType" SG_ 2150244352 ECHGDDV_Col3 "UNM";
BA_ "SignalLongName" SG_ 2150244352 ECHGDDV_Col3 "Energy Consumption History Graph Display Data Values : Column 03";
BA_ "VNSigAllNodes" SG_ 2150244352 ECHGDDV_Col3 1;
BA_ "GenSigDeltaValue" SG_ 2150244352 ECHGDDV_Col2 1;
BA_ "GenSigSendType" SG_ 2150244352 ECHGDDV_Col2 12;
BA_ "GenSigSendOnInit" SG_ 2150244352 ECHGDDV_Col2 1;
BA_ "PacketOrder" SG_ 2150244352 ECHGDDV_Col2 3;
BA_ "VNSigInfotainment" SG_ 2150244352 ECHGDDV_Col2 1;
BA_ "SignalType" SG_ 2150244352 ECHGDDV_Col2 "UNM";
BA_ "SignalLongName" SG_ 2150244352 ECHGDDV_Col2 "Energy Consumption History Graph Display Data Values : Column 02";
BA_ "VNSigAllNodes" SG_ 2150244352 ECHGDDV_Col2 1;
BA_ "GenSigDeltaValue" SG_ 2150244352 ECHGDDV_Col1 1;
BA_ "GenSigSendType" SG_ 2150244352 ECHGDDV_Col1 12;
BA_ "GenSigSendOnInit" SG_ 2150244352 ECHGDDV_Col1 1;
BA_ "PacketOrder" SG_ 2150244352 ECHGDDV_Col1 2;
BA_ "VNSigInfotainment" SG_ 2150244352 ECHGDDV_Col1 1;
BA_ "SignalType" SG_ 2150244352 ECHGDDV_Col1 "UNM";
BA_ "SignalLongName" SG_ 2150244352 ECHGDDV_Col1 "Energy Consumption History Graph Display Data Values : Column 01";
BA_ "VNSigAllNodes" SG_ 2150244352 ECHGDDV_Col1 1;
BA_ "GenSigDeltaValue" SG_ 2150244352 ECHGDDV_EngyConsAvg 1;
BA_ "GenSigSendType" SG_ 2150244352 ECHGDDV_EngyConsAvg 12;
BA_ "GenSigSendOnInit" SG_ 2150244352 ECHGDDV_EngyConsAvg 1;
BA_ "PacketOrder" SG_ 2150244352 ECHGDDV_EngyConsAvg 1;
BA_ "VNSigInfotainment" SG_ 2150244352 ECHGDDV_EngyConsAvg 1;
BA_ "SignalType" SG_ 2150244352 ECHGDDV_EngyConsAvg "UNM";
BA_ "SignalLongName" SG_ 2150244352 ECHGDDV_EngyConsAvg "Energy Consumption History Graph Display Data Values : Energy Consumed Average";
BA_ "VNSigAllNodes" SG_ 2150244352 ECHGDDV_EngyConsAvg 1;
BA_ "GenSigSendType" SG_ 2156953600 WiFiSSIDDgts9to16_Mp 10;
BA_ "GenSigSendOnInit" SG_ 2156953600 WiFiSSIDDgts9to16_Mp 2;
BA_ "SignalType" SG_ 2156953600 WiFiSSIDDgts9to16_Mp "ASC";
BA_ "SignalLongName" SG_ 2156953600 WiFiSSIDDgts9to16_Mp "WiFi Service Set Identifier Digits 9 to 16 Map";
BA_ "VNSigAllNodes" SG_ 2156953600 WiFiSSIDDgts9to16_Mp 1;
BA_ "GenSigSendType" SG_ 2151686144 RrCmrDeplmntReqtsd 10;
BA_ "GenSigSendOnInit" SG_ 2151686144 RrCmrDeplmntReqtsd 2;
BA_ "SignalType" SG_ 2151686144 RrCmrDeplmntReqtsd "BLN";
BA_ "SignalLongName" SG_ 2151686144 RrCmrDeplmntReqtsd "Rear Camera Deployment Requested";
BA_ "VNSigAllNodes" SG_ 2151686144 RrCmrDeplmntReqtsd 1;
BA_ "GenSigSendType" SG_ 2151686144 NoSDCrdPrIO 10;
BA_ "SignalType" SG_ 2151686144 NoSDCrdPrIO "BLN";
BA_ "SignalLongName" SG_ 2151686144 NoSDCrdPrIO "No SD Card Present Indication On";
BA_ "VNSigAllNodes" SG_ 2151686144 NoSDCrdPrIO 1;
BA_ "GenSigSendType" SG_ 2151686144 SDCrdFullIO 10;
BA_ "SignalType" SG_ 2151686144 SDCrdFullIO "BLN";
BA_ "SignalLongName" SG_ 2151686144 SDCrdFullIO "SD Card Full Indication On";
BA_ "VNSigAllNodes" SG_ 2151686144 SDCrdFullIO 1;
BA_ "GenSigSendType" SG_ 2151686144 SDCrdErrIO 10;
BA_ "SignalType" SG_ 2151686144 SDCrdErrIO "BLN";
BA_ "SignalLongName" SG_ 2151686144 SDCrdErrIO "SD Card Error Indication On";
BA_ "VNSigAllNodes" SG_ 2151686144 SDCrdErrIO 1;
BA_ "GenSigDeltaValue" SG_ 2155028480 RtLnChngThrtAprchSpd 1;
BA_ "GenSigSendType" SG_ 2155028480 RtLnChngThrtAprchSpd 12;
BA_ "SignalType" SG_ 2155028480 RtLnChngThrtAprchSpd "SNM";
BA_ "SignalLongName" SG_ 2155028480 RtLnChngThrtAprchSpd "Right Lane Change Threat Approach Speed";
BA_ "VNSigAllNodes" SG_ 2155028480 RtLnChngThrtAprchSpd 1;
BA_ "GenSigSendType" SG_ 2155028480 RgtLnChgThrt 10;
BA_ "GenSigSendOnInit" SG_ 2155028480 RgtLnChgThrt 2;
BA_ "SignalType" SG_ 2155028480 RgtLnChgThrt "BLN";
BA_ "SignalLongName" SG_ 2155028480 RgtLnChgThrt "Right Lane Change Threat";
BA_ "VNSigAllNodes" SG_ 2155028480 RgtLnChgThrt 1;
BA_ "SignalType" SG_ 2151915520 ESPTrnVehOffFrPrkIO "BLN";
BA_ "SignalLongName" SG_ 2151915520 ESPTrnVehOffFrPrkIO "Electronic Shift Primary Turn Vehicle Off For Park Indication On";
BA_ "VNSigAllNodes" SG_ 2151915520 ESPTrnVehOffFrPrkIO 1;
BA_ "SignalType" SG_ 2151915520 ESPTrnsCtlrMalfIO "BLN";
BA_ "SignalLongName" SG_ 2151915520 ESPTrnsCtlrMalfIO "Electronic Shift Primary Transmission Controller Malfunction Indication On";
BA_ "VNSigAllNodes" SG_ 2151915520 ESPTrnsCtlrMalfIO 1;
BA_ "SignalType" SG_ 2151915520 ESPShfToDrvTryAgnIO "BLN";
BA_ "SignalLongName" SG_ 2151915520 ESPShfToDrvTryAgnIO "Electronic Shift Primary Shift To Drive Try Again Indication On";
BA_ "VNSigAllNodes" SG_ 2151915520 ESPShfToDrvTryAgnIO 1;
BA_ "SignalType" SG_ 2151915520 ElcShfPriTwoGrsSlInRq "ENM";
BA_ "SignalLongName" SG_ 2151915520 ElcShfPriTwoGrsSlInRq "Electronic Shift Primary Two Gears Selected Indication Request";
BA_ "VNSigAllNodes" SG_ 2151915520 ElcShfPriTwoGrsSlInRq 1;
BA_ "GenSigSendType" SG_ 2151915520 ESPRedSpdReqShftIO 10;
BA_ "SignalType" SG_ 2151915520 ESPRedSpdReqShftIO "BLN";
BA_ "SignalLongName" SG_ 2151915520 ESPRedSpdReqShftIO "Electronic Shift Primary Reduce Speed for Requested Shift Indication On";
BA_ "VNSigAllNodes" SG_ 2151915520 ESPRedSpdReqShftIO 1;
BA_ "SignalType" SG_ 2151915520 DrvEffInd "SNM";
BA_ "SignalLongName" SG_ 2151915520 DrvEffInd "Drive Efficiency Indication";
BA_ "VNSigAllNodes" SG_ 2151915520 DrvEffInd 1;
BA_ "SignalType" SG_ 2151915520 EngIntkArBstPrExtRngV "ENM";
BA_ "SignalLongName" SG_ 2151915520 EngIntkArBstPrExtRngV "Engine Intake Air Boost Pressure Extended Range Validity";
BA_ "VNSigAllNodes" SG_ 2151915520 EngIntkArBstPrExtRngV 1;
BA_ "SignalType" SG_ 2151915520 EngIntkArBstPrExtRng "UNM";
BA_ "SignalLongName" SG_ 2151915520 EngIntkArBstPrExtRng "Engine Intake Air Boost Pressure Extended Range";
BA_ "VNSigAllNodes" SG_ 2151915520 EngIntkArBstPrExtRng 1;
BA_ "SignalType" SG_ 2151915520 ElecShfRngDispRCExtd "UNM";
BA_ "SignalLongName" SG_ 2151915520 ElecShfRngDispRCExtd "Electronic Shift Range Display Rolling Count Extended";
BA_ "VNSigAllNodes" SG_ 2151915520 ElecShfRngDispRCExtd 1;
BA_ "SignalType" SG_ 2151915520 ElecShfRngDisp "ENM";
BA_ "SignalLongName" SG_ 2151915520 ElecShfRngDisp "Electronic Shift Range Display";
BA_ "VNSigAllNodes" SG_ 2151915520 ElecShfRngDisp 1;
BA_ "SignalType" SG_ 2151915520 ESPTransMalfIO "BLN";
BA_ "SignalLongName" SG_ 2151915520 ESPTransMalfIO "Electronic Shift Primary Transmission Malfunction Indication On";
BA_ "VNSigAllNodes" SG_ 2151915520 ESPTransMalfIO 1;
BA_ "SignalType" SG_ 2151915520 ESPRngInvldReqIO "BLN";
BA_ "SignalLongName" SG_ 2151915520 ESPRngInvldReqIO "Electronic Shift Primary Range Invalid Request Indication On";
BA_ "VNSigAllNodes" SG_ 2151915520 ESPRngInvldReqIO 1;
BA_ "SignalType" SG_ 2151915520 ESPPrkInvldReqIO "BLN";
BA_ "SignalLongName" SG_ 2151915520 ESPPrkInvldReqIO "Electronic Shift Primary Park Invalid Request Indication On";
BA_ "VNSigAllNodes" SG_ 2151915520 ESPPrkInvldReqIO 1;
BA_ "SignalType" SG_ 2151915520 ESPHldShfLvrToEngRgIO "BLN";
BA_ "SignalLongName" SG_ 2151915520 ESPHldShfLvrToEngRgIO "Electronic Shift Primary Hold Shift Lever to Engage Range Indication On";
BA_ "VNSigAllNodes" SG_ 2151915520 ESPHldShfLvrToEngRgIO 1;
BA_ "SignalType" SG_ 2151915520 ESPDrvrPrkIlkSftAtdIO "BLN";
BA_ "SignalLongName" SG_ 2151915520 ESPDrvrPrkIlkSftAtdIO "Electronic Shift Primary Driver Park Interlock Shift Attempted Indication On";
BA_ "VNSigAllNodes" SG_ 2151915520 ESPDrvrPrkIlkSftAtdIO 1;
BA_ "SignalType" SG_ 2151915520 ESPDrvrIlkShfAtdIO "BLN";
BA_ "SignalLongName" SG_ 2151915520 ESPDrvrIlkShfAtdIO "Electronic Shift Primary Driver Interlock Shift Attempted Indication On";
BA_ "VNSigAllNodes" SG_ 2151915520 ESPDrvrIlkShfAtdIO 1;
BA_ "SignalType" SG_ 2151915520 AHAct "BLN";
BA_ "SignalLongName" SG_ 2151915520 AHAct "Auto Hold Active";
BA_ "VNSigAllNodes" SG_ 2151915520 AHAct 1;
BA_ "SignalType" SG_ 2151915520 AHEnbld "BLN";
BA_ "SignalLongName" SG_ 2151915520 AHEnbld "Auto Hold Enabled";
BA_ "VNSigAllNodes" SG_ 2151915520 AHEnbld 1;
BA_ "SignalType" SG_ 2151915520 ShfToPrkBfExtngIO "BLN";
BA_ "SignalLongName" SG_ 2151915520 ShfToPrkBfExtngIO "Shift To Park Before Exiting Indication On";
BA_ "VNSigAllNodes" SG_ 2151915520 ShfToPrkBfExtngIO 1;
BA_ "SignalType" SG_ 2151915520 AHServcIO "BLN";
BA_ "SignalLongName" SG_ 2151915520 AHServcIO "Auto Hold Service Indication On";
BA_ "VNSigAllNodes" SG_ 2151915520 AHServcIO 1;
BA_ "SignalType" SG_ 2151915520 AHAppBrkPedlIO "BLN";
BA_ "SignalLongName" SG_ 2151915520 AHAppBrkPedlIO "Auto Hold Apply Brake Pedal Indication On";
BA_ "VNSigAllNodes" SG_ 2151915520 AHAppBrkPedlIO 1;
BA_ "SignalType" SG_ 2151915520 AHDisbldStbltIO "BLN";
BA_ "SignalLongName" SG_ 2151915520 AHDisbldStbltIO "Auto Hold Disabled Seatbelt Indication On";
BA_ "VNSigAllNodes" SG_ 2151915520 AHDisbldStbltIO 1;
BA_ "SignalType" SG_ 2151915520 AHDisbldDrOpnIO "BLN";
BA_ "SignalLongName" SG_ 2151915520 AHDisbldDrOpnIO "Auto Hold Disabled Door Open Indication On";
BA_ "VNSigAllNodes" SG_ 2151915520 AHDisbldDrOpnIO 1;
BA_ "SignalType" SG_ 2151915520 ElcTransRngSlctVDA "ENM";
BA_ "SignalLongName" SG_ 2151915520 ElcTransRngSlctVDA "Electronic Transmission Range Select Virtual Device Availability";
BA_ "GenSigStartValue" SG_ 2151915520 ElcTransRngSlctVDA 1;
BA_ "VNSigAllNodes" SG_ 2151915520 ElcTransRngSlctVDA 1;
BA_ "GenSigSendType" SG_ 2150129664 HtVwAutnmsEPBAplyReqd 10;
BA_ "SignalType" SG_ 2150129664 HtVwAutnmsEPBAplyReqd "BLN";
BA_ "SignalLongName" SG_ 2150129664 HtVwAutnmsEPBAplyReqd "Hitch View Autonomous Electric Park Brake Apply Requested";
BA_ "VNSigAllNodes" SG_ 2150129664 HtVwAutnmsEPBAplyReqd 1;
BA_ "GenSigSendType" SG_ 2154299392 CrShrngVehChlngReq 10;
BA_ "VNSigIntermediate" SG_ 2154299392 CrShrngVehChlngReq 1;
BA_ "SignalType" SG_ 2154299392 CrShrngVehChlngReq "ENM";
BA_ "SignalLongName" SG_ 2154299392 CrShrngVehChlngReq "Car Sharing Vehicle Challenge Request";
BA_ "GenSigSendType" SG_ 2154397696 CrShrngRvkCertfctRsp 10;
BA_ "VNSigIntermediate" SG_ 2154397696 CrShrngRvkCertfctRsp 1;
BA_ "SignalType" SG_ 2154397696 CrShrngRvkCertfctRsp "ENM";
BA_ "SignalLongName" SG_ 2154397696 CrShrngRvkCertfctRsp "Car Sharing Revoke Certificate Response";
BA_ "GenSigSendType" SG_ 2154397696 CrShrngConnStat 10;
BA_ "VNSigIntermediate" SG_ 2154397696 CrShrngConnStat 1;
BA_ "SignalType" SG_ 2154397696 CrShrngConnStat "ENM";
BA_ "SignalLongName" SG_ 2154397696 CrShrngConnStat "Car Sharing Connection Status";
BA_ "GenSigDeltaValue" SG_ 2154397696 FobIntrCt 1;
BA_ "GenSigSendType" SG_ 2154397696 FobIntrCt 12;
BA_ "VNSigIntermediate" SG_ 2154397696 FobIntrCt 1;
BA_ "SignalType" SG_ 2154397696 FobIntrCt "UNM";
BA_ "SignalLongName" SG_ 2154397696 FobIntrCt "Fob Interior Count";
BA_ "GenSigSendType" SG_ 2154397696 CrShrngFbsEnblStat 10;
BA_ "VNSigIntermediate" SG_ 2154397696 CrShrngFbsEnblStat 1;
BA_ "SignalType" SG_ 2154397696 CrShrngFbsEnblStat "ENM";
BA_ "SignalLongName" SG_ 2154397696 CrShrngFbsEnblStat "Car Sharing Fobs Enable Status";
BA_ "GenSigDeltaValue" SG_ 2154397696 CSPS_CertfctId 1;
BA_ "GenSigSendType" SG_ 2154397696 CSPS_CertfctId 12;
BA_ "PacketOrder" SG_ 2154397696 CSPS_CertfctId 3;
BA_ "VNSigIntermediate" SG_ 2154397696 CSPS_CertfctId 1;
BA_ "SignalType" SG_ 2154397696 CSPS_CertfctId "UNM";
BA_ "SignalLongName" SG_ 2154397696 CSPS_CertfctId "Car Sharing Phone Status : Certificate Identification";
BA_ "GenSigSendType" SG_ 2154397696 CSPS_ConnStat 10;
BA_ "PacketOrder" SG_ 2154397696 CSPS_ConnStat 2;
BA_ "VNSigIntermediate" SG_ 2154397696 CSPS_ConnStat 1;
BA_ "SignalType" SG_ 2154397696 CSPS_ConnStat "ENM";
BA_ "SignalLongName" SG_ 2154397696 CSPS_ConnStat "Car Sharing Phone Status : Connection Status";
BA_ "GenSigSendType" SG_ 2154397696 CSPS_RspVerf 10;
BA_ "PacketOrder" SG_ 2154397696 CSPS_RspVerf 1;
BA_ "VNSigIntermediate" SG_ 2154397696 CSPS_RspVerf 1;
BA_ "SignalType" SG_ 2154397696 CSPS_RspVerf "ENM";
BA_ "SignalLongName" SG_ 2154397696 CSPS_RspVerf "Car Sharing Phone Status : Response Verification";
BA_ "GenSigDeltaValue" SG_ 2154553344 CrShrngEncrpScrtRsp 1;
BA_ "GenSigSendType" SG_ 2154553344 CrShrngEncrpScrtRsp 12;
BA_ "VNSigIntermediate" SG_ 2154553344 CrShrngEncrpScrtRsp 1;
BA_ "SignalType" SG_ 2154553344 CrShrngEncrpScrtRsp "UNM";
BA_ "SignalLongName" SG_ 2154553344 CrShrngEncrpScrtRsp "Car Sharing Encrypted Secret Response";
BA_ "GenSigDeltaValue" SG_ 2154536960 CrShrngEncrpScrt 1;
BA_ "GenSigSendType" SG_ 2154536960 CrShrngEncrpScrt 12;
BA_ "VNSigIntermediate" SG_ 2154536960 CrShrngEncrpScrt 1;
BA_ "SignalType" SG_ 2154536960 CrShrngEncrpScrt "UNM";
BA_ "SignalLongName" SG_ 2154536960 CrShrngEncrpScrt "Car Sharing Encrypted Secret";
BA_ "GenSigDeltaValue" SG_ 2154545152 CrShrgIntCtftAthrtyCtftRp 1;
BA_ "GenSigSendType" SG_ 2154545152 CrShrgIntCtftAthrtyCtftRp 12;
BA_ "VNSigIntermediate" SG_ 2154545152 CrShrgIntCtftAthrtyCtftRp 1;
BA_ "SignalType" SG_ 2154545152 CrShrgIntCtftAthrtyCtftRp "UNM";
BA_ "SignalLongName" SG_ 2154545152 CrShrgIntCtftAthrtyCtftRp "Car Sharing Intermediate Certificate Authority Certificate Response";
BA_ "GenSigDeltaValue" SG_ 2154520576 CrShrgIntCtftAthrtyCtft 1;
BA_ "GenSigSendType" SG_ 2154520576 CrShrgIntCtftAthrtyCtft 12;
BA_ "VNSigIntermediate" SG_ 2154520576 CrShrgIntCtftAthrtyCtft 1;
BA_ "SignalType" SG_ 2154520576 CrShrgIntCtftAthrtyCtft "UNM";
BA_ "SignalLongName" SG_ 2154520576 CrShrgIntCtftAthrtyCtft "Car Sharing Intermediate Certificate Authority Certificate";
BA_ "GenSigDeltaValue" SG_ 2154504192 CrShrngUsrCertfctRsp 1;
BA_ "GenSigSendType" SG_ 2154504192 CrShrngUsrCertfctRsp 12;
BA_ "VNSigIntermediate" SG_ 2154504192 CrShrngUsrCertfctRsp 1;
BA_ "SignalType" SG_ 2154504192 CrShrngUsrCertfctRsp "UNM";
BA_ "SignalLongName" SG_ 2154504192 CrShrngUsrCertfctRsp "Car Sharing User Certificate Response";
BA_ "GenSigDeltaValue" SG_ 2154479616 CrShrngUsrCertfct 1;
BA_ "GenSigSendType" SG_ 2154479616 CrShrngUsrCertfct 12;
BA_ "VNSigIntermediate" SG_ 2154479616 CrShrngUsrCertfct 1;
BA_ "SignalType" SG_ 2154479616 CrShrngUsrCertfct "UNM";
BA_ "SignalLongName" SG_ 2154479616 CrShrngUsrCertfct "Car Sharing User Certificate";
BA_ "GenSigSendType" SG_ 2154381312 CSZS_FrntCmptZnMbDevStat 10;
BA_ "VNSigIntermediate" SG_ 2154381312 CSZS_FrntCmptZnMbDevStat 1;
BA_ "SignalType" SG_ 2154381312 CSZS_FrntCmptZnMbDevStat "ENM";
BA_ "PacketOrder" SG_ 2154381312 CSZS_FrntCmptZnMbDevStat 8;
BA_ "SignalLongName" SG_ 2154381312 CSZS_FrntCmptZnMbDevStat "Car Sharing Zone Status : Front Compartment Zone Mobile Device Status";
BA_ "GenSigSendType" SG_ 2154381312 CSZS_RrCmptZnMbDevStat 10;
BA_ "VNSigIntermediate" SG_ 2154381312 CSZS_RrCmptZnMbDevStat 1;
BA_ "SignalType" SG_ 2154381312 CSZS_RrCmptZnMbDevStat "ENM";
BA_ "PacketOrder" SG_ 2154381312 CSZS_RrCmptZnMbDevStat 7;
BA_ "SignalLongName" SG_ 2154381312 CSZS_RrCmptZnMbDevStat "Car Sharing Zone Status : Rear Compartment Zone Mobile Device Status";
BA_ "GenSigSendType" SG_ 2154381312 CSZS_FrntExtrZnMbDevStat 10;
BA_ "VNSigIntermediate" SG_ 2154381312 CSZS_FrntExtrZnMbDevStat 1;
BA_ "SignalType" SG_ 2154381312 CSZS_FrntExtrZnMbDevStat "ENM";
BA_ "PacketOrder" SG_ 2154381312 CSZS_FrntExtrZnMbDevStat 6;
BA_ "SignalLongName" SG_ 2154381312 CSZS_FrntExtrZnMbDevStat "Car Sharing Zone Status : Front Exterior Zone Mobile Device Stats";
BA_ "GenSigSendType" SG_ 2154381312 CSZS_RrExtrZnMbDevStat 10;
BA_ "VNSigIntermediate" SG_ 2154381312 CSZS_RrExtrZnMbDevStat 1;
BA_ "SignalType" SG_ 2154381312 CSZS_RrExtrZnMbDevStat "ENM";
BA_ "PacketOrder" SG_ 2154381312 CSZS_RrExtrZnMbDevStat 5;
BA_ "SignalLongName" SG_ 2154381312 CSZS_RrExtrZnMbDevStat "Car Sharing Zone Status : Rear Exterior Zone Mobile Device Status";
BA_ "GenSigSendType" SG_ 2154381312 CSZS_WlcmZnMbDevStat 10;
BA_ "VNSigIntermediate" SG_ 2154381312 CSZS_WlcmZnMbDevStat 1;
BA_ "SignalType" SG_ 2154381312 CSZS_WlcmZnMbDevStat "ENM";
BA_ "PacketOrder" SG_ 2154381312 CSZS_WlcmZnMbDevStat 4;
BA_ "SignalLongName" SG_ 2154381312 CSZS_WlcmZnMbDevStat "Car Sharing Zone Status : Welcome Zone Mobile Device Status";
BA_ "GenSigSendType" SG_ 2154381312 CSZS_IntrZnMbDevStat 10;
BA_ "VNSigIntermediate" SG_ 2154381312 CSZS_IntrZnMbDevStat 1;
BA_ "SignalType" SG_ 2154381312 CSZS_IntrZnMbDevStat "ENM";
BA_ "PacketOrder" SG_ 2154381312 CSZS_IntrZnMbDevStat 3;
BA_ "SignalLongName" SG_ 2154381312 CSZS_IntrZnMbDevStat "Car Sharing Zone Status : Interior Zone Mobile Device Status";
BA_ "GenSigSendType" SG_ 2154381312 CSZS_PassEntyZnMbDevStat 10;
BA_ "VNSigIntermediate" SG_ 2154381312 CSZS_PassEntyZnMbDevStat 1;
BA_ "SignalType" SG_ 2154381312 CSZS_PassEntyZnMbDevStat "ENM";
BA_ "PacketOrder" SG_ 2154381312 CSZS_PassEntyZnMbDevStat 2;
BA_ "SignalLongName" SG_ 2154381312 CSZS_PassEntyZnMbDevStat "Car Sharing Zone Status : Passenger Entry Zone Mobile Device Status";
BA_ "GenSigSendType" SG_ 2154381312 CSZS_DrEntyZnMbDevStat 10;
BA_ "VNSigIntermediate" SG_ 2154381312 CSZS_DrEntyZnMbDevStat 1;
BA_ "SignalType" SG_ 2154381312 CSZS_DrEntyZnMbDevStat "ENM";
BA_ "PacketOrder" SG_ 2154381312 CSZS_DrEntyZnMbDevStat 1;
BA_ "SignalLongName" SG_ 2154381312 CSZS_DrEntyZnMbDevStat "Car Sharing Zone Status : Driver Entry Zone Mobile Device Status";
BA_ "GenSigDeltaValue" SG_ 2152153088 RRSCDS_UnsdRsrvd 1;
BA_ "GenSigSendType" SG_ 2152153088 RRSCDS_UnsdRsrvd 12;
BA_ "SignalType" SG_ 2152153088 RRSCDS_UnsdRsrvd "UNM";
BA_ "PacketOrder" SG_ 2152153088 RRSCDS_UnsdRsrvd 19;
BA_ "SignalLongName" SG_ 2152153088 RRSCDS_UnsdRsrvd "Right Rear Seat Control Display Status : Unused and Reserved";
BA_ "VNSigAllNodes" SG_ 2152153088 RRSCDS_UnsdRsrvd 1;
BA_ "GenSigSendType" SG_ 2152153088 RRSCDS_DispReq 10;
BA_ "SignalType" SG_ 2152153088 RRSCDS_DispReq "BLN";
BA_ "PacketOrder" SG_ 2152153088 RRSCDS_DispReq 18;
BA_ "SignalLongName" SG_ 2152153088 RRSCDS_DispReq "Right Rear Seat Control Display Status : Display Request";
BA_ "VNSigAllNodes" SG_ 2152153088 RRSCDS_DispReq 1;
BA_ "GenSigSendType" SG_ 2152153088 RRSCDS_DispSz 10;
BA_ "SignalType" SG_ 2152153088 RRSCDS_DispSz "ENM";
BA_ "PacketOrder" SG_ 2152153088 RRSCDS_DispSz 17;
BA_ "SignalLongName" SG_ 2152153088 RRSCDS_DispSz "Right Rear Seat Control Display Status : Display Size";
BA_ "VNSigAllNodes" SG_ 2152153088 RRSCDS_DispSz 1;
BA_ "GenSigSendType" SG_ 2152153088 RRSCDS_CshLgAdjFdRr 10;
BA_ "SignalType" SG_ 2152153088 RRSCDS_CshLgAdjFdRr "ENM";
BA_ "PacketOrder" SG_ 2152153088 RRSCDS_CshLgAdjFdRr 16;
BA_ "SignalLongName" SG_ 2152153088 RRSCDS_CshLgAdjFdRr "Right Rear Seat Control Display Status : Cushion Length Adjustment Forward/Rearward";
BA_ "VNSigAllNodes" SG_ 2152153088 RRSCDS_CshLgAdjFdRr 1;
BA_ "GenSigSendType" SG_ 2152153088 RRSCDS_BkCshBlstInOt 10;
BA_ "SignalType" SG_ 2152153088 RRSCDS_BkCshBlstInOt "ENM";
BA_ "PacketOrder" SG_ 2152153088 RRSCDS_BkCshBlstInOt 15;
BA_ "SignalLongName" SG_ 2152153088 RRSCDS_BkCshBlstInOt "Right Rear Seat Control Display Status : Back and Cushion Bolster In/Out";
BA_ "VNSigAllNodes" SG_ 2152153088 RRSCDS_BkCshBlstInOt 1;
BA_ "GenSigSendType" SG_ 2152153088 RRSCDS_CshBlstrInOut 10;
BA_ "SignalType" SG_ 2152153088 RRSCDS_CshBlstrInOut "ENM";
BA_ "PacketOrder" SG_ 2152153088 RRSCDS_CshBlstrInOut 14;
BA_ "SignalLongName" SG_ 2152153088 RRSCDS_CshBlstrInOut "Right Rear Seat Control Display Status : Cushion Bolster In/Out";
BA_ "VNSigAllNodes" SG_ 2152153088 RRSCDS_CshBlstrInOut 1;
BA_ "GenSigSendType" SG_ 2152153088 RRSCDS_BkBlstrInOut 10;
BA_ "SignalType" SG_ 2152153088 RRSCDS_BkBlstrInOut "ENM";
BA_ "PacketOrder" SG_ 2152153088 RRSCDS_BkBlstrInOut 13;
BA_ "SignalLongName" SG_ 2152153088 RRSCDS_BkBlstrInOut "Right Rear Seat Control Display Status : Back Bolster In/Out";
BA_ "VNSigAllNodes" SG_ 2152153088 RRSCDS_BkBlstrInOut 1;
BA_ "GenSigSendType" SG_ 2152153088 RRSCDS_LmbrUDnFdRr 10;
BA_ "SignalType" SG_ 2152153088 RRSCDS_LmbrUDnFdRr "ENM";
BA_ "PacketOrder" SG_ 2152153088 RRSCDS_LmbrUDnFdRr 12;
BA_ "SignalLongName" SG_ 2152153088 RRSCDS_LmbrUDnFdRr "Right Rear Seat Control Display Status : Lumbar Up/Down and Forward/Rearward";
BA_ "VNSigAllNodes" SG_ 2152153088 RRSCDS_LmbrUDnFdRr 1;
BA_ "GenSigSendType" SG_ 2152153088 RRSCDS_LmbrFwdRr 10;
BA_ "SignalType" SG_ 2152153088 RRSCDS_LmbrFwdRr "ENM";
BA_ "PacketOrder" SG_ 2152153088 RRSCDS_LmbrFwdRr 11;
BA_ "SignalLongName" SG_ 2152153088 RRSCDS_LmbrFwdRr "Right Rear Seat Control Display Status : Lumbar Forward/Rearward";
BA_ "VNSigAllNodes" SG_ 2152153088 RRSCDS_LmbrFwdRr 1;
BA_ "GenSigSendType" SG_ 2152153088 RRSCDS_LmbrUpDwn 10;
BA_ "SignalType" SG_ 2152153088 RRSCDS_LmbrUpDwn "ENM";
BA_ "PacketOrder" SG_ 2152153088 RRSCDS_LmbrUpDwn 10;
BA_ "SignalLongName" SG_ 2152153088 RRSCDS_LmbrUpDwn "Right Rear Seat Control Display Status : Lumbar Up/Down";
BA_ "VNSigAllNodes" SG_ 2152153088 RRSCDS_LmbrUpDwn 1;
BA_ "GenSigSendType" SG_ 2152153088 RRSCDS_UprShldrFdRr 10;
BA_ "SignalType" SG_ 2152153088 RRSCDS_UprShldrFdRr "ENM";
BA_ "PacketOrder" SG_ 2152153088 RRSCDS_UprShldrFdRr 9;
BA_ "SignalLongName" SG_ 2152153088 RRSCDS_UprShldrFdRr "Right Rear Seat Control Display Status : Upper Shoulder Forward/Rearward";
BA_ "VNSigAllNodes" SG_ 2152153088 RRSCDS_UprShldrFdRr 1;
BA_ "GenSigSendType" SG_ 2152153088 RRSCDS_HdrstTltFwdRr 10;
BA_ "SignalType" SG_ 2152153088 RRSCDS_HdrstTltFwdRr "ENM";
BA_ "PacketOrder" SG_ 2152153088 RRSCDS_HdrstTltFwdRr 8;
BA_ "SignalLongName" SG_ 2152153088 RRSCDS_HdrstTltFwdRr "Right Rear Seat Control Display Status : Headrest Tilt Forward/Rearward";
BA_ "VNSigAllNodes" SG_ 2152153088 RRSCDS_HdrstTltFwdRr 1;
BA_ "GenSigSendType" SG_ 2152153088 RRSCDS_HdrstWngInOt 10;
BA_ "SignalType" SG_ 2152153088 RRSCDS_HdrstWngInOt "ENM";
BA_ "PacketOrder" SG_ 2152153088 RRSCDS_HdrstWngInOt 7;
BA_ "SignalLongName" SG_ 2152153088 RRSCDS_HdrstWngInOt "Right Rear Seat Control Display Status : Headrest Wings In/Out";
BA_ "VNSigAllNodes" SG_ 2152153088 RRSCDS_HdrstWngInOt 1;
BA_ "GenSigSendType" SG_ 2152153088 RRSCDS_HdrstFdRrUDn 10;
BA_ "SignalType" SG_ 2152153088 RRSCDS_HdrstFdRrUDn "ENM";
BA_ "PacketOrder" SG_ 2152153088 RRSCDS_HdrstFdRrUDn 6;
BA_ "SignalLongName" SG_ 2152153088 RRSCDS_HdrstFdRrUDn "Right Rear Seat Control Display Status : Headrest Forward/Rearward

 and Up/Down";
BA_ "VNSigAllNodes" SG_ 2152153088 RRSCDS_HdrstFdRrUDn 1;
BA_ "GenSigSendType" SG_ 2152153088 RRSCDS_HdrstFwdRrwd 10;
BA_ "SignalType" SG_ 2152153088 RRSCDS_HdrstFwdRrwd "ENM";
BA_ "PacketOrder" SG_ 2152153088 RRSCDS_HdrstFwdRrwd 5;
BA_ "SignalLongName" SG_ 2152153088 RRSCDS_HdrstFwdRrwd "Right Rear Seat Control Display Status : Headrest Forward/Rearward";
BA_ "VNSigAllNodes" SG_ 2152153088 RRSCDS_HdrstFwdRrwd 1;
BA_ "GenSigSendType" SG_ 2152153088 RRSCDS_HdrstUpDn 10;
BA_ "SignalType" SG_ 2152153088 RRSCDS_HdrstUpDn "ENM";
BA_ "PacketOrder" SG_ 2152153088 RRSCDS_HdrstUpDn 4;
BA_ "SignalLongName" SG_ 2152153088 RRSCDS_HdrstUpDn "Right Rear Seat Control Display Status : Headrest Up/Down";
BA_ "VNSigAllNodes" SG_ 2152153088 RRSCDS_HdrstUpDn 1;
BA_ "GenSigSendType" SG_ 2152153088 RRSCDS_MassgIntsty 10;
BA_ "SignalType" SG_ 2152153088 RRSCDS_MassgIntsty "ENM";
BA_ "PacketOrder" SG_ 2152153088 RRSCDS_MassgIntsty 3;
BA_ "SignalLongName" SG_ 2152153088 RRSCDS_MassgIntsty "Right Rear Seat Control Display Status : Massage Intensity";
BA_ "VNSigAllNodes" SG_ 2152153088 RRSCDS_MassgIntsty 1;
BA_ "GenSigSendType" SG_ 2152153088 RRSCDS_MassgTyp 10;
BA_ "SignalType" SG_ 2152153088 RRSCDS_MassgTyp "ENM";
BA_ "PacketOrder" SG_ 2152153088 RRSCDS_MassgTyp 2;
BA_ "SignalLongName" SG_ 2152153088 RRSCDS_MassgTyp "Right Rear Seat Control Display Status : Massage Type";
BA_ "VNSigAllNodes" SG_ 2152153088 RRSCDS_MassgTyp 1;
BA_ "GenSigSendType" SG_ 2152153088 RRSCDS_Massg 10;
BA_ "SignalType" SG_ 2152153088 RRSCDS_Massg "ENM";
BA_ "PacketOrder" SG_ 2152153088 RRSCDS_Massg 1;
BA_ "SignalLongName" SG_ 2152153088 RRSCDS_Massg "Right Rear Seat Control Display Status : Massage";
BA_ "VNSigAllNodes" SG_ 2152153088 RRSCDS_Massg 1;
BA_ "GenSigSendType" SG_ 2152136704 RRSMP_UnsdRsrvd 10;
BA_ "GenSigSendOnInit" SG_ 2152136704 RRSMP_UnsdRsrvd 2;
BA_ "SignalType" SG_ 2152136704 RRSMP_UnsdRsrvd "BLN";
BA_ "PacketOrder" SG_ 2152136704 RRSMP_UnsdRsrvd 17;
BA_ "SignalLongName" SG_ 2152136704 RRSMP_UnsdRsrvd "Right Rear Seat Massage Priority : Unused and Reserved";
BA_ "VNSigAllNodes" SG_ 2152136704 RRSMP_UnsdRsrvd 1;
BA_ "GenSigDeltaValue" SG_ 2152136704 RRSMP_MaxDispVal 1;
BA_ "GenSigSendType" SG_ 2152136704 RRSMP_MaxDispVal 12;
BA_ "GenSigSendOnInit" SG_ 2152136704 RRSMP_MaxDispVal 2;
BA_ "SignalType" SG_ 2152136704 RRSMP_MaxDispVal "UNM";
BA_ "PacketOrder" SG_ 2152136704 RRSMP_MaxDispVal 16;
BA_ "SignalLongName" SG_ 2152136704 RRSMP_MaxDispVal "Right Rear Seat Massage Priority : Maximum Display Value";
BA_ "VNSigAllNodes" SG_ 2152136704 RRSMP_MaxDispVal 1;
BA_ "GenSigDeltaValue" SG_ 2152136704 RRSMP_Type15 1;
BA_ "GenSigSendType" SG_ 2152136704 RRSMP_Type15 12;
BA_ "GenSigSendOnInit" SG_ 2152136704 RRSMP_Type15 2;
BA_ "SignalType" SG_ 2152136704 RRSMP_Type15 "UNM";
BA_ "PacketOrder" SG_ 2152136704 RRSMP_Type15 15;
BA_ "SignalLongName" SG_ 2152136704 RRSMP_Type15 "Right Rear Seat Massage Priority : Type 15";
BA_ "VNSigAllNodes" SG_ 2152136704 RRSMP_Type15 1;
BA_ "GenSigDeltaValue" SG_ 2152136704 RRSMP_Type14 1;
BA_ "GenSigSendType" SG_ 2152136704 RRSMP_Type14 12;
BA_ "GenSigSendOnInit" SG_ 2152136704 RRSMP_Type14 2;
BA_ "SignalType" SG_ 2152136704 RRSMP_Type14 "UNM";
BA_ "PacketOrder" SG_ 2152136704 RRSMP_Type14 14;
BA_ "SignalLongName" SG_ 2152136704 RRSMP_Type14 "Right Rear Seat Massage Priority : Type 14";
BA_ "VNSigAllNodes" SG_ 2152136704 RRSMP_Type14 1;
BA_ "GenSigDeltaValue" SG_ 2152136704 RRSMP_Type13 1;
BA_ "GenSigSendType" SG_ 2152136704 RRSMP_Type13 12;
BA_ "GenSigSendOnInit" SG_ 2152136704 RRSMP_Type13 2;
BA_ "SignalType" SG_ 2152136704 RRSMP_Type13 "UNM";
BA_ "PacketOrder" SG_ 2152136704 RRSMP_Type13 13;
BA_ "SignalLongName" SG_ 2152136704 RRSMP_Type13 "Right Rear Seat Massage Priority : Type 13";
BA_ "VNSigAllNodes" SG_ 2152136704 RRSMP_Type13 1;
BA_ "GenSigDeltaValue" SG_ 2152136704 RRSMP_Type12 1;
BA_ "GenSigSendType" SG_ 2152136704 RRSMP_Type12 12;
BA_ "GenSigSendOnInit" SG_ 2152136704 RRSMP_Type12 2;
BA_ "SignalType" SG_ 2152136704 RRSMP_Type12 "UNM";
BA_ "PacketOrder" SG_ 2152136704 RRSMP_Type12 12;
BA_ "SignalLongName" SG_ 2152136704 RRSMP_Type12 "Right Rear Seat Massage Priority : Type 12";
BA_ "VNSigAllNodes" SG_ 2152136704 RRSMP_Type12 1;
BA_ "GenSigDeltaValue" SG_ 2152136704 RRSMP_Type11 1;
BA_ "GenSigSendType" SG_ 2152136704 RRSMP_Type11 12;
BA_ "GenSigSendOnInit" SG_ 2152136704 RRSMP_Type11 2;
BA_ "SignalType" SG_ 2152136704 RRSMP_Type11 "UNM";
BA_ "PacketOrder" SG_ 2152136704 RRSMP_Type11 11;
BA_ "SignalLongName" SG_ 2152136704 RRSMP_Type11 "Right Rear Seat Massage Priority : Type 11";
BA_ "VNSigAllNodes" SG_ 2152136704 RRSMP_Type11 1;
BA_ "GenSigDeltaValue" SG_ 2152136704 RRSMP_Type10 1;
BA_ "GenSigSendType" SG_ 2152136704 RRSMP_Type10 12;
BA_ "GenSigSendOnInit" SG_ 2152136704 RRSMP_Type10 2;
BA_ "SignalType" SG_ 2152136704 RRSMP_Type10 "UNM";
BA_ "PacketOrder" SG_ 2152136704 RRSMP_Type10 10;
BA_ "SignalLongName" SG_ 2152136704 RRSMP_Type10 "Right Rear Seat Massage Priority : Type 10";
BA_ "VNSigAllNodes" SG_ 2152136704 RRSMP_Type10 1;
BA_ "GenSigDeltaValue" SG_ 2152136704 RRSMP_Type9 1;
BA_ "GenSigSendType" SG_ 2152136704 RRSMP_Type9 12;
BA_ "GenSigSendOnInit" SG_ 2152136704 RRSMP_Type9 2;
BA_ "SignalType" SG_ 2152136704 RRSMP_Type9 "UNM";
BA_ "PacketOrder" SG_ 2152136704 RRSMP_Type9 9;
BA_ "SignalLongName" SG_ 2152136704 RRSMP_Type9 "Right Rear Seat Massage Priority : Type 9";
BA_ "VNSigAllNodes" SG_ 2152136704 RRSMP_Type9 1;
BA_ "GenSigDeltaValue" SG_ 2152136704 RRSMP_Type8 1;
BA_ "GenSigSendType" SG_ 2152136704 RRSMP_Type8 12;
BA_ "GenSigSendOnInit" SG_ 2152136704 RRSMP_Type8 2;
BA_ "SignalType" SG_ 2152136704 RRSMP_Type8 "UNM";
BA_ "PacketOrder" SG_ 2152136704 RRSMP_Type8 8;
BA_ "SignalLongName" SG_ 2152136704 RRSMP_Type8 "Right Rear Seat Massage Priority : Type 8";
BA_ "VNSigAllNodes" SG_ 2152136704 RRSMP_Type8 1;
BA_ "GenSigDeltaValue" SG_ 2152136704 RRSMP_Type7 1;
BA_ "GenSigSendType" SG_ 2152136704 RRSMP_Type7 12;
BA_ "GenSigSendOnInit" SG_ 2152136704 RRSMP_Type7 2;
BA_ "SignalType" SG_ 2152136704 RRSMP_Type7 "UNM";
BA_ "PacketOrder" SG_ 2152136704 RRSMP_Type7 7;
BA_ "SignalLongName" SG_ 2152136704 RRSMP_Type7 "Right Rear Seat Massage Priority : Type 7";
BA_ "VNSigAllNodes" SG_ 2152136704 RRSMP_Type7 1;
BA_ "GenSigDeltaValue" SG_ 2152136704 RRSMP_Type6 1;
BA_ "GenSigSendType" SG_ 2152136704 RRSMP_Type6 12;
BA_ "GenSigSendOnInit" SG_ 2152136704 RRSMP_Type6 2;
BA_ "SignalType" SG_ 2152136704 RRSMP_Type6 "UNM";
BA_ "PacketOrder" SG_ 2152136704 RRSMP_Type6 6;
BA_ "SignalLongName" SG_ 2152136704 RRSMP_Type6 "Right Rear Seat Massage Priority : Type 6";
BA_ "VNSigAllNodes" SG_ 2152136704 RRSMP_Type6 1;
BA_ "GenSigDeltaValue" SG_ 2152136704 RRSMP_Type5 1;
BA_ "GenSigSendType" SG_ 2152136704 RRSMP_Type5 12;
BA_ "GenSigSendOnInit" SG_ 2152136704 RRSMP_Type5 2;
BA_ "SignalType" SG_ 2152136704 RRSMP_Type5 "UNM";
BA_ "PacketOrder" SG_ 2152136704 RRSMP_Type5 5;
BA_ "SignalLongName" SG_ 2152136704 RRSMP_Type5 "Right Rear Seat Massage Priority : Type 5";
BA_ "VNSigAllNodes" SG_ 2152136704 RRSMP_Type5 1;
BA_ "GenSigDeltaValue" SG_ 2152136704 RRSMP_Type4 1;
BA_ "GenSigSendType" SG_ 2152136704 RRSMP_Type4 12;
BA_ "GenSigSendOnInit" SG_ 2152136704 RRSMP_Type4 2;
BA_ "SignalType" SG_ 2152136704 RRSMP_Type4 "UNM";
BA_ "PacketOrder" SG_ 2152136704 RRSMP_Type4 4;
BA_ "SignalLongName" SG_ 2152136704 RRSMP_Type4 "Right Rear Seat Massage Priority : Type 4";
BA_ "VNSigAllNodes" SG_ 2152136704 RRSMP_Type4 1;
BA_ "GenSigDeltaValue" SG_ 2152136704 RRSMP_Type3 1;
BA_ "GenSigSendType" SG_ 2152136704 RRSMP_Type3 12;
BA_ "GenSigSendOnInit" SG_ 2152136704 RRSMP_Type3 2;
BA_ "SignalType" SG_ 2152136704 RRSMP_Type3 "UNM";
BA_ "PacketOrder" SG_ 2152136704 RRSMP_Type3 3;
BA_ "SignalLongName" SG_ 2152136704 RRSMP_Type3 "Right Rear Seat Massage Priority : Type 3";
BA_ "VNSigAllNodes" SG_ 2152136704 RRSMP_Type3 1;
BA_ "GenSigDeltaValue" SG_ 2152136704 RRSMP_Type2 1;
BA_ "GenSigSendType" SG_ 2152136704 RRSMP_Type2 12;
BA_ "GenSigSendOnInit" SG_ 2152136704 RRSMP_Type2 2;
BA_ "SignalType" SG_ 2152136704 RRSMP_Type2 "UNM";
BA_ "PacketOrder" SG_ 2152136704 RRSMP_Type2 2;
BA_ "SignalLongName" SG_ 2152136704 RRSMP_Type2 "Right Rear Seat Massage Priority : Type 2";
BA_ "VNSigAllNodes" SG_ 2152136704 RRSMP_Type2 1;
BA_ "GenSigDeltaValue" SG_ 2152136704 RRSMP_Type1 1;
BA_ "GenSigSendType" SG_ 2152136704 RRSMP_Type1 12;
BA_ "GenSigSendOnInit" SG_ 2152136704 RRSMP_Type1 2;
BA_ "SignalType" SG_ 2152136704 RRSMP_Type1 "UNM";
BA_ "PacketOrder" SG_ 2152136704 RRSMP_Type1 1;
BA_ "SignalLongName" SG_ 2152136704 RRSMP_Type1 "Right Rear Seat Massage Priority : Type 1";
BA_ "VNSigAllNodes" SG_ 2152136704 RRSMP_Type1 1;
BA_ "GenSigDeltaValue" SG_ 2152120320 RRSAP_UnsdRsrvd 1;
BA_ "GenSigSendType" SG_ 2152120320 RRSAP_UnsdRsrvd 12;
BA_ "GenSigSendOnInit" SG_ 2152120320 RRSAP_UnsdRsrvd 2;
BA_ "SignalType" SG_ 2152120320 RRSAP_UnsdRsrvd "UNM";
BA_ "PacketOrder" SG_ 2152120320 RRSAP_UnsdRsrvd 16;
BA_ "SignalLongName" SG_ 2152120320 RRSAP_UnsdRsrvd "Right Rear Seat Actuator Priority : Unused and Reserved";
BA_ "VNSigAllNodes" SG_ 2152120320 RRSAP_UnsdRsrvd 1;
BA_ "GenSigDeltaValue" SG_ 2152120320 RRSAP_DispSz 1;
BA_ "GenSigSendType" SG_ 2152120320 RRSAP_DispSz 12;
BA_ "GenSigSendOnInit" SG_ 2152120320 RRSAP_DispSz 2;
BA_ "SignalType" SG_ 2152120320 RRSAP_DispSz "UNM";
BA_ "PacketOrder" SG_ 2152120320 RRSAP_DispSz 15;
BA_ "SignalLongName" SG_ 2152120320 RRSAP_DispSz "Right Rear Seat Actuator Priority : Display Size";
BA_ "VNSigAllNodes" SG_ 2152120320 RRSAP_DispSz 1;
BA_ "GenSigDeltaValue" SG_ 2152120320 RRSAP_CshLgthAdjFdRr 1;
BA_ "GenSigSendType" SG_ 2152120320 RRSAP_CshLgthAdjFdRr 12;
BA_ "GenSigSendOnInit" SG_ 2152120320 RRSAP_CshLgthAdjFdRr 2;
BA_ "SignalType" SG_ 2152120320 RRSAP_CshLgthAdjFdRr "UNM";
BA_ "PacketOrder" SG_ 2152120320 RRSAP_CshLgthAdjFdRr 14;
BA_ "SignalLongName" SG_ 2152120320 RRSAP_CshLgthAdjFdRr "Right Rear Seat Actuator Priority : Cushion Length Adjustment Forward/Rearward";
BA_ "VNSigAllNodes" SG_ 2152120320 RRSAP_CshLgthAdjFdRr 1;
BA_ "GenSigDeltaValue" SG_ 2152120320 RRSAP_BkCshBlstrInOut 1;
BA_ "GenSigSendType" SG_ 2152120320 RRSAP_BkCshBlstrInOut 12;
BA_ "GenSigSendOnInit" SG_ 2152120320 RRSAP_BkCshBlstrInOut 2;
BA_ "SignalType" SG_ 2152120320 RRSAP_BkCshBlstrInOut "UNM";
BA_ "PacketOrder" SG_ 2152120320 RRSAP_BkCshBlstrInOut 13;
BA_ "SignalLongName" SG_ 2152120320 RRSAP_BkCshBlstrInOut "Right Rear Seat Actuator Priority : Back and Cushion Bolster In/Out";
BA_ "VNSigAllNodes" SG_ 2152120320 RRSAP_BkCshBlstrInOut 1;
BA_ "GenSigDeltaValue" SG_ 2152120320 RRSAP_CshBlstrInOut 1;
BA_ "GenSigSendType" SG_ 2152120320 RRSAP_CshBlstrInOut 12;
BA_ "GenSigSendOnInit" SG_ 2152120320 RRSAP_CshBlstrInOut 2;
BA_ "SignalType" SG_ 2152120320 RRSAP_CshBlstrInOut "UNM";
BA_ "PacketOrder" SG_ 2152120320 RRSAP_CshBlstrInOut 12;
BA_ "SignalLongName" SG_ 2152120320 RRSAP_CshBlstrInOut "Right Rear Seat Actuator Priority : Cushion Bolster In/Out";
BA_ "VNSigAllNodes" SG_ 2152120320 RRSAP_CshBlstrInOut 1;
BA_ "GenSigDeltaValue" SG_ 2152120320 RRSAP_BkBlstrInOut 1;
BA_ "GenSigSendType" SG_ 2152120320 RRSAP_BkBlstrInOut 12;
BA_ "GenSigSendOnInit" SG_ 2152120320 RRSAP_BkBlstrInOut 2;
BA_ "SignalType" SG_ 2152120320 RRSAP_BkBlstrInOut "UNM";
BA_ "PacketOrder" SG_ 2152120320 RRSAP_BkBlstrInOut 11;
BA_ "SignalLongName" SG_ 2152120320 RRSAP_BkBlstrInOut "Right Rear Seat Actuator Priority : Back Bolster In/Out";
BA_ "VNSigAllNodes" SG_ 2152120320 RRSAP_BkBlstrInOut 1;
BA_ "GenSigDeltaValue" SG_ 2152120320 RRSAP_LmbrUpDnFdRr 1;
BA_ "GenSigSendType" SG_ 2152120320 RRSAP_LmbrUpDnFdRr 12;
BA_ "GenSigSendOnInit" SG_ 2152120320 RRSAP_LmbrUpDnFdRr 2;
BA_ "SignalType" SG_ 2152120320 RRSAP_LmbrUpDnFdRr "UNM";
BA_ "PacketOrder" SG_ 2152120320 RRSAP_LmbrUpDnFdRr 10;
BA_ "SignalLongName" SG_ 2152120320 RRSAP_LmbrUpDnFdRr "Right Rear Seat Actuator Priority : Lumbar Up/Down and Forward/Rearward";
BA_ "VNSigAllNodes" SG_ 2152120320 RRSAP_LmbrUpDnFdRr 1;
BA_ "GenSigDeltaValue" SG_ 2152120320 RRSAP_LmbrFwdRr 1;
BA_ "GenSigSendType" SG_ 2152120320 RRSAP_LmbrFwdRr 12;
BA_ "GenSigSendOnInit" SG_ 2152120320 RRSAP_LmbrFwdRr 2;
BA_ "SignalType" SG_ 2152120320 RRSAP_LmbrFwdRr "UNM";
BA_ "PacketOrder" SG_ 2152120320 RRSAP_LmbrFwdRr 9;
BA_ "SignalLongName" SG_ 2152120320 RRSAP_LmbrFwdRr "Right Rear Seat Actuator Priority : Lumbar Forward/Rearward";
BA_ "VNSigAllNodes" SG_ 2152120320 RRSAP_LmbrFwdRr 1;
BA_ "GenSigDeltaValue" SG_ 2152120320 RRSAP_LmbrUpDwn 1;
BA_ "GenSigSendType" SG_ 2152120320 RRSAP_LmbrUpDwn 12;
BA_ "GenSigSendOnInit" SG_ 2152120320 RRSAP_LmbrUpDwn 2;
BA_ "SignalType" SG_ 2152120320 RRSAP_LmbrUpDwn "UNM";
BA_ "PacketOrder" SG_ 2152120320 RRSAP_LmbrUpDwn 8;
BA_ "SignalLongName" SG_ 2152120320 RRSAP_LmbrUpDwn "Right Rear Seat Actuator Priority : Lumbar Up/Down";
BA_ "VNSigAllNodes" SG_ 2152120320 RRSAP_LmbrUpDwn 1;
BA_ "GenSigDeltaValue" SG_ 2152120320 RRSAP_UprShldrFwdRr 1;
BA_ "GenSigSendType" SG_ 2152120320 RRSAP_UprShldrFwdRr 12;
BA_ "GenSigSendOnInit" SG_ 2152120320 RRSAP_UprShldrFwdRr 2;
BA_ "SignalType" SG_ 2152120320 RRSAP_UprShldrFwdRr "UNM";
BA_ "PacketOrder" SG_ 2152120320 RRSAP_UprShldrFwdRr 7;
BA_ "SignalLongName" SG_ 2152120320 RRSAP_UprShldrFwdRr "Right Rear Seat Actuator Priority : Upper Shoulder Forward/Rearward";
BA_ "VNSigAllNodes" SG_ 2152120320 RRSAP_UprShldrFwdRr 1;
BA_ "GenSigDeltaValue" SG_ 2152120320 RRSAP_HdrstTltFwdRr 1;
BA_ "GenSigSendType" SG_ 2152120320 RRSAP_HdrstTltFwdRr 12;
BA_ "GenSigSendOnInit" SG_ 2152120320 RRSAP_HdrstTltFwdRr 2;
BA_ "SignalType" SG_ 2152120320 RRSAP_HdrstTltFwdRr "UNM";
BA_ "PacketOrder" SG_ 2152120320 RRSAP_HdrstTltFwdRr 6;
BA_ "SignalLongName" SG_ 2152120320 RRSAP_HdrstTltFwdRr "Right Rear Seat Actuator Priority : Headrest Tilt Forward/Rearward";
BA_ "VNSigAllNodes" SG_ 2152120320 RRSAP_HdrstTltFwdRr 1;
BA_ "GenSigDeltaValue" SG_ 2152120320 RRSAP_HdrstWngsInOut 1;
BA_ "GenSigSendType" SG_ 2152120320 RRSAP_HdrstWngsInOut 12;
BA_ "GenSigSendOnInit" SG_ 2152120320 RRSAP_HdrstWngsInOut 2;
BA_ "SignalType" SG_ 2152120320 RRSAP_HdrstWngsInOut "UNM";
BA_ "PacketOrder" SG_ 2152120320 RRSAP_HdrstWngsInOut 5;
BA_ "SignalLongName" SG_ 2152120320 RRSAP_HdrstWngsInOut "Right Rear Seat Actuator Priority : Headrest Wings Inward/Outward";
BA_ "VNSigAllNodes" SG_ 2152120320 RRSAP_HdrstWngsInOut 1;
BA_ "GenSigDeltaValue" SG_ 2152120320 RRSAP_HdrstUpDnFdRr 1;
BA_ "GenSigSendType" SG_ 2152120320 RRSAP_HdrstUpDnFdRr 12;
BA_ "GenSigSendOnInit" SG_ 2152120320 RRSAP_HdrstUpDnFdRr 2;
BA_ "SignalType" SG_ 2152120320 RRSAP_HdrstUpDnFdRr "UNM";
BA_ "PacketOrder" SG_ 2152120320 RRSAP_HdrstUpDnFdRr 4;
BA_ "SignalLongName" SG_ 2152120320 RRSAP_HdrstUpDnFdRr "Right Rear Seat Actuator Priority : Headrest Up/Down and Forward/Rearward";
BA_ "VNSigAllNodes" SG_ 2152120320 RRSAP_HdrstUpDnFdRr 1;
BA_ "GenSigDeltaValue" SG_ 2152120320 RRSAP_HdrstFwdRrwd 1;
BA_ "GenSigSendType" SG_ 2152120320 RRSAP_HdrstFwdRrwd 12;
BA_ "GenSigSendOnInit" SG_ 2152120320 RRSAP_HdrstFwdRrwd 2;
BA_ "SignalType" SG_ 2152120320 RRSAP_HdrstFwdRrwd "UNM";
BA_ "PacketOrder" SG_ 2152120320 RRSAP_HdrstFwdRrwd 3;
BA_ "SignalLongName" SG_ 2152120320 RRSAP_HdrstFwdRrwd "Right Rear Seat Actuator Priority : Headrest Forward/Rearward";
BA_ "VNSigAllNodes" SG_ 2152120320 RRSAP_HdrstFwdRrwd 1;
BA_ "GenSigDeltaValue" SG_ 2152120320 RRSAP_HdrstUpDn 1;
BA_ "GenSigSendType" SG_ 2152120320 RRSAP_HdrstUpDn 12;
BA_ "GenSigSendOnInit" SG_ 2152120320 RRSAP_HdrstUpDn 2;
BA_ "SignalType" SG_ 2152120320 RRSAP_HdrstUpDn "UNM";
BA_ "PacketOrder" SG_ 2152120320 RRSAP_HdrstUpDn 2;
BA_ "SignalLongName" SG_ 2152120320 RRSAP_HdrstUpDn "Right Rear Seat Actuator Priority : Headrest Up/Down";
BA_ "VNSigAllNodes" SG_ 2152120320 RRSAP_HdrstUpDn 1;
BA_ "GenSigDeltaValue" SG_ 2152120320 RRSAP_Massg 1;
BA_ "GenSigSendType" SG_ 2152120320 RRSAP_Massg 12;
BA_ "GenSigSendOnInit" SG_ 2152120320 RRSAP_Massg 2;
BA_ "SignalType" SG_ 2152120320 RRSAP_Massg "UNM";
BA_ "PacketOrder" SG_ 2152120320 RRSAP_Massg 1;
BA_ "SignalLongName" SG_ 2152120320 RRSAP_Massg "Right Rear Seat Actuator Priority : Massage";
BA_ "VNSigAllNodes" SG_ 2152120320 RRSAP_Massg 1;
BA_ "GenSigDeltaValue" SG_ 2152103936 LRSCDS_UnsdRsrvd 1;
BA_ "GenSigSendType" SG_ 2152103936 LRSCDS_UnsdRsrvd 12;
BA_ "SignalType" SG_ 2152103936 LRSCDS_UnsdRsrvd "UNM";
BA_ "PacketOrder" SG_ 2152103936 LRSCDS_UnsdRsrvd 19;
BA_ "SignalLongName" SG_ 2152103936 LRSCDS_UnsdRsrvd "Left Rear Seat Control Display Status : Unused and Reserved";
BA_ "VNSigAllNodes" SG_ 2152103936 LRSCDS_UnsdRsrvd 1;
BA_ "GenSigSendType" SG_ 2152103936 LRSCDS_DispReq 10;
BA_ "SignalType" SG_ 2152103936 LRSCDS_DispReq "BLN";
BA_ "PacketOrder" SG_ 2152103936 LRSCDS_DispReq 18;
BA_ "SignalLongName" SG_ 2152103936 LRSCDS_DispReq "Left Rear Seat Control Display Status : Display Request";
BA_ "VNSigAllNodes" SG_ 2152103936 LRSCDS_DispReq 1;
BA_ "GenSigSendType" SG_ 2152103936 LRSCDS_DispSz 10;
BA_ "SignalType" SG_ 2152103936 LRSCDS_DispSz "ENM";
BA_ "PacketOrder" SG_ 2152103936 LRSCDS_DispSz 17;
BA_ "SignalLongName" SG_ 2152103936 LRSCDS_DispSz "Left Rear Seat Control Display Status : Display Size";
BA_ "VNSigAllNodes" SG_ 2152103936 LRSCDS_DispSz 1;
BA_ "GenSigSendType" SG_ 2152103936 LRSCDS_CshLgAdjFdRr 10;
BA_ "SignalType" SG_ 2152103936 LRSCDS_CshLgAdjFdRr "ENM";
BA_ "PacketOrder" SG_ 2152103936 LRSCDS_CshLgAdjFdRr 16;
BA_ "SignalLongName" SG_ 2152103936 LRSCDS_CshLgAdjFdRr "Left Rear Seat Control Display Status : Cushion Length Adjustment Forward/Rearward";
BA_ "VNSigAllNodes" SG_ 2152103936 LRSCDS_CshLgAdjFdRr 1;
BA_ "GenSigSendType" SG_ 2152103936 LRSCDS_BkCshBlstInOt 10;
BA_ "SignalType" SG_ 2152103936 LRSCDS_BkCshBlstInOt "ENM";
BA_ "PacketOrder" SG_ 2152103936 LRSCDS_BkCshBlstInOt 15;
BA_ "SignalLongName" SG_ 2152103936 LRSCDS_BkCshBlstInOt "Left Rear Seat Control Display Status : Back and Cushion Bolster In/Out";
BA_ "VNSigAllNodes" SG_ 2152103936 LRSCDS_BkCshBlstInOt 1;
BA_ "GenSigSendType" SG_ 2152103936 LRSCDS_CshBlstrInOut 10;
BA_ "SignalType" SG_ 2152103936 LRSCDS_CshBlstrInOut "ENM";
BA_ "PacketOrder" SG_ 2152103936 LRSCDS_CshBlstrInOut 14;
BA_ "SignalLongName" SG_ 2152103936 LRSCDS_CshBlstrInOut "Left Rear Seat Control Display Status : Cushion Bolster In/Out";
BA_ "VNSigAllNodes" SG_ 2152103936 LRSCDS_CshBlstrInOut 1;
BA_ "GenSigSendType" SG_ 2152103936 LRSCDS_BkBlstrInOut 10;
BA_ "SignalType" SG_ 2152103936 LRSCDS_BkBlstrInOut "ENM";
BA_ "PacketOrder" SG_ 2152103936 LRSCDS_BkBlstrInOut 13;
BA_ "SignalLongName" SG_ 2152103936 LRSCDS_BkBlstrInOut "Left Rear Seat Control Display Status : Back Bolster In/Out";
BA_ "VNSigAllNodes" SG_ 2152103936 LRSCDS_BkBlstrInOut 1;
BA_ "GenSigSendType" SG_ 2152103936 LRSCDS_LmbrUDnFdRr 10;
BA_ "SignalType" SG_ 2152103936 LRSCDS_LmbrUDnFdRr "ENM";
BA_ "PacketOrder" SG_ 2152103936 LRSCDS_LmbrUDnFdRr 12;
BA_ "SignalLongName" SG_ 2152103936 LRSCDS_LmbrUDnFdRr "Left Rear Seat Control Display Status : Lumbar Up/Down and Forward/Rearward";
BA_ "VNSigAllNodes" SG_ 2152103936 LRSCDS_LmbrUDnFdRr 1;
BA_ "GenSigSendType" SG_ 2152103936 LRSCDS_LmbrFwdRr 10;
BA_ "SignalType" SG_ 2152103936 LRSCDS_LmbrFwdRr "ENM";
BA_ "PacketOrder" SG_ 2152103936 LRSCDS_LmbrFwdRr 11;
BA_ "SignalLongName" SG_ 2152103936 LRSCDS_LmbrFwdRr "Left Rear Seat Control Display Status : Lumbar Forward/Rearward";
BA_ "VNSigAllNodes" SG_ 2152103936 LRSCDS_LmbrFwdRr 1;
BA_ "GenSigSendType" SG_ 2152103936 LRSCDS_LmbrUpDwn 10;
BA_ "SignalType" SG_ 2152103936 LRSCDS_LmbrUpDwn "ENM";
BA_ "PacketOrder" SG_ 2152103936 LRSCDS_LmbrUpDwn 10;
BA_ "SignalLongName" SG_ 2152103936 LRSCDS_LmbrUpDwn "Left Rear Seat Control Display Status : Lumbar Up/Down";
BA_ "VNSigAllNodes" SG_ 2152103936 LRSCDS_LmbrUpDwn 1;
BA_ "GenSigSendType" SG_ 2152103936 LRSCDS_UprShldrFdRr 10;
BA_ "SignalType" SG_ 2152103936 LRSCDS_UprShldrFdRr "ENM";
BA_ "PacketOrder" SG_ 2152103936 LRSCDS_UprShldrFdRr 9;
BA_ "SignalLongName" SG_ 2152103936 LRSCDS_UprShldrFdRr "Left Rear Seat Control Display Status : Upper Shoulder Forward/Rearward";
BA_ "VNSigAllNodes" SG_ 2152103936 LRSCDS_UprShldrFdRr 1;
BA_ "GenSigSendType" SG_ 2152103936 LRSCDS_HdrstTltFwdRr 10;
BA_ "SignalType" SG_ 2152103936 LRSCDS_HdrstTltFwdRr "ENM";
BA_ "PacketOrder" SG_ 2152103936 LRSCDS_HdrstTltFwdRr 8;
BA_ "SignalLongName" SG_ 2152103936 LRSCDS_HdrstTltFwdRr "Left Rear Seat Control Display Status : Headrest Tilt Forward/Rearward";
BA_ "VNSigAllNodes" SG_ 2152103936 LRSCDS_HdrstTltFwdRr 1;
BA_ "GenSigSendType" SG_ 2152103936 LRSCDS_HdrstWngInOt 10;
BA_ "SignalType" SG_ 2152103936 LRSCDS_HdrstWngInOt "ENM";
BA_ "PacketOrder" SG_ 2152103936 LRSCDS_HdrstWngInOt 7;
BA_ "SignalLongName" SG_ 2152103936 LRSCDS_HdrstWngInOt "Left Rear Seat Control Display Status : Headrest Wings In/Out";
BA_ "VNSigAllNodes" SG_ 2152103936 LRSCDS_HdrstWngInOt 1;
BA_ "GenSigSendType" SG_ 2152103936 LRSCDS_HdrstFdRrUDn 10;
BA_ "SignalType" SG_ 2152103936 LRSCDS_HdrstFdRrUDn "ENM";
BA_ "PacketOrder" SG_ 2152103936 LRSCDS_HdrstFdRrUDn 6;
BA_ "SignalLongName" SG_ 2152103936 LRSCDS_HdrstFdRrUDn "Left Rear Seat Control Display Status : Headrest Forward/Rearward and Up/Down";
BA_ "VNSigAllNodes" SG_ 2152103936 LRSCDS_HdrstFdRrUDn 1;
BA_ "GenSigSendType" SG_ 2152103936 LRSCDS_HdrstFwdRrwd 10;
BA_ "SignalType" SG_ 2152103936 LRSCDS_HdrstFwdRrwd "ENM";
BA_ "PacketOrder" SG_ 2152103936 LRSCDS_HdrstFwdRrwd 5;
BA_ "SignalLongName" SG_ 2152103936 LRSCDS_HdrstFwdRrwd "Left Rear Seat Control Display Status : Headrest Forward/Rearward";
BA_ "VNSigAllNodes" SG_ 2152103936 LRSCDS_HdrstFwdRrwd 1;
BA_ "GenSigSendType" SG_ 2152103936 LRSCDS_HdrstUpDn 10;
BA_ "SignalType" SG_ 2152103936 LRSCDS_HdrstUpDn "ENM";
BA_ "PacketOrder" SG_ 2152103936 LRSCDS_HdrstUpDn 4;
BA_ "SignalLongName" SG_ 2152103936 LRSCDS_HdrstUpDn "Left Rear Seat Control Display Status : Headrest Up/Down";
BA_ "VNSigAllNodes" SG_ 2152103936 LRSCDS_HdrstUpDn 1;
BA_ "GenSigSendType" SG_ 2152103936 LRSCDS_MassgIntsty 10;
BA_ "SignalType" SG_ 2152103936 LRSCDS_MassgIntsty "ENM";
BA_ "PacketOrder" SG_ 2152103936 LRSCDS_MassgIntsty 3;
BA_ "SignalLongName" SG_ 2152103936 LRSCDS_MassgIntsty "Left Rear Seat Control Display Status : Massage Intensity";
BA_ "VNSigAllNodes" SG_ 2152103936 LRSCDS_MassgIntsty 1;
BA_ "GenSigSendType" SG_ 2152103936 LRSCDS_MassgTyp 10;
BA_ "SignalType" SG_ 2152103936 LRSCDS_MassgTyp "ENM";
BA_ "PacketOrder" SG_ 2152103936 LRSCDS_MassgTyp 2;
BA_ "SignalLongName" SG_ 2152103936 LRSCDS_MassgTyp "Left Rear Seat Control Display Status : Massage Type";
BA_ "VNSigAllNodes" SG_ 2152103936 LRSCDS_MassgTyp 1;
BA_ "GenSigSendType" SG_ 2152103936 LRSCDS_Massg 10;
BA_ "SignalType" SG_ 2152103936 LRSCDS_Massg "ENM";
BA_ "PacketOrder" SG_ 2152103936 LRSCDS_Massg 1;
BA_ "SignalLongName" SG_ 2152103936 LRSCDS_Massg "Left Rear Seat Control Display Status : Massage";
BA_ "VNSigAllNodes" SG_ 2152103936 LRSCDS_Massg 1;
BA_ "GenSigSendType" SG_ 2152087552 LRSMP_UnsdRsrvd 10;
BA_ "GenSigSendOnInit" SG_ 2152087552 LRSMP_UnsdRsrvd 2;
BA_ "SignalType" SG_ 2152087552 LRSMP_UnsdRsrvd "BLN";
BA_ "PacketOrder" SG_ 2152087552 LRSMP_UnsdRsrvd 17;
BA_ "SignalLongName" SG_ 2152087552 LRSMP_UnsdRsrvd "Left Rear Seat Massage Priority : Unused and Reserved";
BA_ "VNSigAllNodes" SG_ 2152087552 LRSMP_UnsdRsrvd 1;
BA_ "GenSigDeltaValue" SG_ 2152087552 LRSMP_MaxDispVal 1;
BA_ "GenSigSendType" SG_ 2152087552 LRSMP_MaxDispVal 12;
BA_ "GenSigSendOnInit" SG_ 2152087552 LRSMP_MaxDispVal 2;
BA_ "SignalType" SG_ 2152087552 LRSMP_MaxDispVal "UNM";
BA_ "PacketOrder" SG_ 2152087552 LRSMP_MaxDispVal 16;
BA_ "SignalLongName" SG_ 2152087552 LRSMP_MaxDispVal "Left Rear Seat Massage Priority : Maximum Display Value";
BA_ "VNSigAllNodes" SG_ 2152087552 LRSMP_MaxDispVal 1;
BA_ "GenSigDeltaValue" SG_ 2152087552 LRSMP_Type15 1;
BA_ "GenSigSendType" SG_ 2152087552 LRSMP_Type15 12;
BA_ "GenSigSendOnInit" SG_ 2152087552 LRSMP_Type15 2;
BA_ "SignalType" SG_ 2152087552 LRSMP_Type15 "UNM";
BA_ "PacketOrder" SG_ 2152087552 LRSMP_Type15 15;
BA_ "SignalLongName" SG_ 2152087552 LRSMP_Type15 "Left Rear Seat Massage Priority : Type 15";
BA_ "VNSigAllNodes" SG_ 2152087552 LRSMP_Type15 1;
BA_ "GenSigDeltaValue" SG_ 2152087552 LRSMP_Type14 1;
BA_ "GenSigSendType" SG_ 2152087552 LRSMP_Type14 12;
BA_ "GenSigSendOnInit" SG_ 2152087552 LRSMP_Type14 2;
BA_ "SignalType" SG_ 2152087552 LRSMP_Type14 "UNM";
BA_ "PacketOrder" SG_ 2152087552 LRSMP_Type14 14;
BA_ "SignalLongName" SG_ 2152087552 LRSMP_Type14 "Left Rear Seat Massage Priority : Type 14";
BA_ "VNSigAllNodes" SG_ 2152087552 LRSMP_Type14 1;
BA_ "GenSigDeltaValue" SG_ 2152087552 LRSMP_Type13 1;
BA_ "GenSigSendType" SG_ 2152087552 LRSMP_Type13 12;
BA_ "GenSigSendOnInit" SG_ 2152087552 LRSMP_Type13 2;
BA_ "SignalType" SG_ 2152087552 LRSMP_Type13 "UNM";
BA_ "PacketOrder" SG_ 2152087552 LRSMP_Type13 13;
BA_ "SignalLongName" SG_ 2152087552 LRSMP_Type13 "Left Rear Seat Massage Priority : Type 13";
BA_ "VNSigAllNodes" SG_ 2152087552 LRSMP_Type13 1;
BA_ "GenSigDeltaValue" SG_ 2152087552 LRSMP_Type12 1;
BA_ "GenSigSendType" SG_ 2152087552 LRSMP_Type12 12;
BA_ "GenSigSendOnInit" SG_ 2152087552 LRSMP_Type12 2;
BA_ "SignalType" SG_ 2152087552 LRSMP_Type12 "UNM";
BA_ "PacketOrder" SG_ 2152087552 LRSMP_Type12 12;
BA_ "SignalLongName" SG_ 2152087552 LRSMP_Type12 "Left Rear Seat Massage Priority : Type 12";
BA_ "VNSigAllNodes" SG_ 2152087552 LRSMP_Type12 1;
BA_ "GenSigDeltaValue" SG_ 2152087552 LRSMP_Type11 1;
BA_ "GenSigSendType" SG_ 2152087552 LRSMP_Type11 12;
BA_ "GenSigSendOnInit" SG_ 2152087552 LRSMP_Type11 2;
BA_ "SignalType" SG_ 2152087552 LRSMP_Type11 "UNM";
BA_ "PacketOrder" SG_ 2152087552 LRSMP_Type11 11;
BA_ "SignalLongName" SG_ 2152087552 LRSMP_Type11 "Left Rear Seat Massage Priority : Type 11";
BA_ "VNSigAllNodes" SG_ 2152087552 LRSMP_Type11 1;
BA_ "GenSigDeltaValue" SG_ 2152087552 LRSMP_Type10 1;
BA_ "GenSigSendType" SG_ 2152087552 LRSMP_Type10 12;
BA_ "GenSigSendOnInit" SG_ 2152087552 LRSMP_Type10 2;
BA_ "SignalType" SG_ 2152087552 LRSMP_Type10 "UNM";
BA_ "PacketOrder" SG_ 2152087552 LRSMP_Type10 10;
BA_ "SignalLongName" SG_ 2152087552 LRSMP_Type10 "Left Rear Seat Massage Priority : Type 10";
BA_ "VNSigAllNodes" SG_ 2152087552 LRSMP_Type10 1;
BA_ "GenSigDeltaValue" SG_ 2152087552 LRSMP_Type9 1;
BA_ "GenSigSendType" SG_ 2152087552 LRSMP_Type9 12;
BA_ "GenSigSendOnInit" SG_ 2152087552 LRSMP_Type9 2;
BA_ "SignalType" SG_ 2152087552 LRSMP_Type9 "UNM";
BA_ "PacketOrder" SG_ 2152087552 LRSMP_Type9 9;
BA_ "SignalLongName" SG_ 2152087552 LRSMP_Type9 "Left Rear Seat Massage Priority : Type 9";
BA_ "VNSigAllNodes" SG_ 2152087552 LRSMP_Type9 1;
BA_ "GenSigDeltaValue" SG_ 2152087552 LRSMP_Type8 1;
BA_ "GenSigSendType" SG_ 2152087552 LRSMP_Type8 12;
BA_ "GenSigSendOnInit" SG_ 2152087552 LRSMP_Type8 2;
BA_ "SignalType" SG_ 2152087552 LRSMP_Type8 "UNM";
BA_ "PacketOrder" SG_ 2152087552 LRSMP_Type8 8;
BA_ "SignalLongName" SG_ 2152087552 LRSMP_Type8 "Left Rear Seat Massage Priority : Type 8";
BA_ "VNSigAllNodes" SG_ 2152087552 LRSMP_Type8 1;
BA_ "GenSigDeltaValue" SG_ 2152087552 LRSMP_Type7 1;
BA_ "GenSigSendType" SG_ 2152087552 LRSMP_Type7 12;
BA_ "GenSigSendOnInit" SG_ 2152087552 LRSMP_Type7 2;
BA_ "SignalType" SG_ 2152087552 LRSMP_Type7 "UNM";
BA_ "PacketOrder" SG_ 2152087552 LRSMP_Type7 7;
BA_ "SignalLongName" SG_ 2152087552 LRSMP_Type7 "Left Rear Seat Massage Priority : Type 7";
BA_ "VNSigAllNodes" SG_ 2152087552 LRSMP_Type7 1;
BA_ "GenSigDeltaValue" SG_ 2152087552 LRSMP_Type6 1;
BA_ "GenSigSendType" SG_ 2152087552 LRSMP_Type6 12;
BA_ "GenSigSendOnInit" SG_ 2152087552 LRSMP_Type6 2;
BA_ "SignalType" SG_ 2152087552 LRSMP_Type6 "UNM";
BA_ "PacketOrder" SG_ 2152087552 LRSMP_Type6 6;
BA_ "SignalLongName" SG_ 2152087552 LRSMP_Type6 "Left Rear Seat Massage Priority : Type 6";
BA_ "VNSigAllNodes" SG_ 2152087552 LRSMP_Type6 1;
BA_ "GenSigDeltaValue" SG_ 2152087552 LRSMP_Type5 1;
BA_ "GenSigSendType" SG_ 2152087552 LRSMP_Type5 12;
BA_ "GenSigSendOnInit" SG_ 2152087552 LRSMP_Type5 2;
BA_ "SignalType" SG_ 2152087552 LRSMP_Type5 "UNM";
BA_ "PacketOrder" SG_ 2152087552 LRSMP_Type5 5;
BA_ "SignalLongName" SG_ 2152087552 LRSMP_Type5 "Left Rear Seat Massage Priority : Type 5";
BA_ "VNSigAllNodes" SG_ 2152087552 LRSMP_Type5 1;
BA_ "GenSigDeltaValue" SG_ 2152087552 LRSMP_Type4 1;
BA_ "GenSigSendType" SG_ 2152087552 LRSMP_Type4 12;
BA_ "GenSigSendOnInit" SG_ 2152087552 LRSMP_Type4 2;
BA_ "SignalType" SG_ 2152087552 LRSMP_Type4 "UNM";
BA_ "PacketOrder" SG_ 2152087552 LRSMP_Type4 4;
BA_ "SignalLongName" SG_ 2152087552 LRSMP_Type4 "Left Rear Seat Massage Priority : Type 4";
BA_ "VNSigAllNodes" SG_ 2152087552 LRSMP_Type4 1;
BA_ "GenSigDeltaValue" SG_ 2152087552 LRSMP_Type3 1;
BA_ "GenSigSendType" SG_ 2152087552 LRSMP_Type3 12;
BA_ "GenSigSendOnInit" SG_ 2152087552 LRSMP_Type3 2;
BA_ "SignalType" SG_ 2152087552 LRSMP_Type3 "UNM";
BA_ "PacketOrder" SG_ 2152087552 LRSMP_Type3 3;
BA_ "SignalLongName" SG_ 2152087552 LRSMP_Type3 "Left Rear Seat Massage Priority : Type 3";
BA_ "VNSigAllNodes" SG_ 2152087552 LRSMP_Type3 1;
BA_ "GenSigDeltaValue" SG_ 2152087552 LRSMP_Type2 1;
BA_ "GenSigSendType" SG_ 2152087552 LRSMP_Type2 12;
BA_ "GenSigSendOnInit" SG_ 2152087552 LRSMP_Type2 2;
BA_ "SignalType" SG_ 2152087552 LRSMP_Type2 "UNM";
BA_ "PacketOrder" SG_ 2152087552 LRSMP_Type2 2;
BA_ "SignalLongName" SG_ 2152087552 LRSMP_Type2 "Left Rear Seat Massage Priority : Type 2";
BA_ "VNSigAllNodes" SG_ 2152087552 LRSMP_Type2 1;
BA_ "GenSigDeltaValue" SG_ 2152087552 LRSMP_Type1 1;
BA_ "GenSigSendType" SG_ 2152087552 LRSMP_Type1 12;
BA_ "GenSigSendOnInit" SG_ 2152087552 LRSMP_Type1 2;
BA_ "SignalType" SG_ 2152087552 LRSMP_Type1 "UNM";
BA_ "PacketOrder" SG_ 2152087552 LRSMP_Type1 1;
BA_ "SignalLongName" SG_ 2152087552 LRSMP_Type1 "Left Rear Seat Massage Priority : Type 1";
BA_ "VNSigAllNodes" SG_ 2152087552 LRSMP_Type1 1;
BA_ "GenSigDeltaValue" SG_ 2152071168 LRSAP_UnsdRsrvd 1;
BA_ "GenSigSendType" SG_ 2152071168 LRSAP_UnsdRsrvd 12;
BA_ "GenSigSendOnInit" SG_ 2152071168 LRSAP_UnsdRsrvd 2;
BA_ "SignalType" SG_ 2152071168 LRSAP_UnsdRsrvd "UNM";
BA_ "PacketOrder" SG_ 2152071168 LRSAP_UnsdRsrvd 16;
BA_ "SignalLongName" SG_ 2152071168 LRSAP_UnsdRsrvd "Left Rear Seat Actuator Priority : Unused and Reserved";
BA_ "VNSigAllNodes" SG_ 2152071168 LRSAP_UnsdRsrvd 1;
BA_ "GenSigDeltaValue" SG_ 2152071168 LRSAP_DispSz 1;
BA_ "GenSigSendType" SG_ 2152071168 LRSAP_DispSz 12;
BA_ "GenSigSendOnInit" SG_ 2152071168 LRSAP_DispSz 2;
BA_ "SignalType" SG_ 2152071168 LRSAP_DispSz "UNM";
BA_ "PacketOrder" SG_ 2152071168 LRSAP_DispSz 15;
BA_ "SignalLongName" SG_ 2152071168 LRSAP_DispSz "Left Rear Seat Actuator Priority : Display Size";
BA_ "VNSigAllNodes" SG_ 2152071168 LRSAP_DispSz 1;
BA_ "GenSigDeltaValue" SG_ 2152071168 LRSAP_CshLgthAdjFdRr 1;
BA_ "GenSigSendType" SG_ 2152071168 LRSAP_CshLgthAdjFdRr 12;
BA_ "GenSigSendOnInit" SG_ 2152071168 LRSAP_CshLgthAdjFdRr 2;
BA_ "SignalType" SG_ 2152071168 LRSAP_CshLgthAdjFdRr "UNM";
BA_ "PacketOrder" SG_ 2152071168 LRSAP_CshLgthAdjFdRr 14;
BA_ "SignalLongName" SG_ 2152071168 LRSAP_CshLgthAdjFdRr "Left Rear Seat Actuator Priority : Cushion Length Adjustment Forward/Rearward";
BA_ "VNSigAllNodes" SG_ 2152071168 LRSAP_CshLgthAdjFdRr 1;
BA_ "GenSigDeltaValue" SG_ 2152071168 LRSAP_BkCshBlstrInOut 1;
BA_ "GenSigSendType" SG_ 2152071168 LRSAP_BkCshBlstrInOut 12;
BA_ "GenSigSendOnInit" SG_ 2152071168 LRSAP_BkCshBlstrInOut 2;
BA_ "SignalType" SG_ 2152071168 LRSAP_BkCshBlstrInOut "UNM";
BA_ "PacketOrder" SG_ 2152071168 LRSAP_BkCshBlstrInOut 13;
BA_ "SignalLongName" SG_ 2152071168 LRSAP_BkCshBlstrInOut "Left Rear Seat Actuator Priority : Back and Cushion Bolster In/Out";
BA_ "VNSigAllNodes" SG_ 2152071168 LRSAP_BkCshBlstrInOut 1;
BA_ "GenSigDeltaValue" SG_ 2152071168 LRSAP_CshBlstrInOut 1;
BA_ "GenSigSendType" SG_ 2152071168 LRSAP_CshBlstrInOut 12;
BA_ "GenSigSendOnInit" SG_ 2152071168 LRSAP_CshBlstrInOut 2;
BA_ "SignalType" SG_ 2152071168 LRSAP_CshBlstrInOut "UNM";
BA_ "PacketOrder" SG_ 2152071168 LRSAP_CshBlstrInOut 12;
BA_ "SignalLongName" SG_ 2152071168 LRSAP_CshBlstrInOut "Left Rear Seat Actuator Priority : Cushion Bolster In/Out";
BA_ "VNSigAllNodes" SG_ 2152071168 LRSAP_CshBlstrInOut 1;
BA_ "GenSigDeltaValue" SG_ 2152071168 LRSAP_BkBlstrInOut 1;
BA_ "GenSigSendType" SG_ 2152071168 LRSAP_BkBlstrInOut 12;
BA_ "GenSigSendOnInit" SG_ 2152071168 LRSAP_BkBlstrInOut 2;
BA_ "SignalType" SG_ 2152071168 LRSAP_BkBlstrInOut "UNM";
BA_ "PacketOrder" SG_ 2152071168 LRSAP_BkBlstrInOut 11;
BA_ "SignalLongName" SG_ 2152071168 LRSAP_BkBlstrInOut "Left Rear Seat Actuator Priority : Back Bolster In/Out";
BA_ "VNSigAllNodes" SG_ 2152071168 LRSAP_BkBlstrInOut 1;
BA_ "GenSigDeltaValue" SG_ 2152071168 LRSAP_LmbrUpDnFdRr 1;
BA_ "GenSigSendType" SG_ 2152071168 LRSAP_LmbrUpDnFdRr 12;
BA_ "GenSigSendOnInit" SG_ 2152071168 LRSAP_LmbrUpDnFdRr 2;
BA_ "SignalType" SG_ 2152071168 LRSAP_LmbrUpDnFdRr "UNM";
BA_ "PacketOrder" SG_ 2152071168 LRSAP_LmbrUpDnFdRr 10;
BA_ "SignalLongName" SG_ 2152071168 LRSAP_LmbrUpDnFdRr "Left Rear Seat Actuator Priority : Lumbar Up/Down and Forward/Rearward";
BA_ "VNSigAllNodes" SG_ 2152071168 LRSAP_LmbrUpDnFdRr 1;
BA_ "GenSigDeltaValue" SG_ 2152071168 LRSAP_LmbrFwdRr 1;
BA_ "GenSigSendType" SG_ 2152071168 LRSAP_LmbrFwdRr 12;
BA_ "GenSigSendOnInit" SG_ 2152071168 LRSAP_LmbrFwdRr 2;
BA_ "SignalType" SG_ 2152071168 LRSAP_LmbrFwdRr "UNM";
BA_ "PacketOrder" SG_ 2152071168 LRSAP_LmbrFwdRr 9;
BA_ "SignalLongName" SG_ 2152071168 LRSAP_LmbrFwdRr "Left Rear Seat Actuator Priority : Lumbar Forward/Rearward";
BA_ "VNSigAllNodes" SG_ 2152071168 LRSAP_LmbrFwdRr 1;
BA_ "GenSigDeltaValue" SG_ 2152071168 LRSAP_LmbrUpDwn 1;
BA_ "GenSigSendType" SG_ 2152071168 LRSAP_LmbrUpDwn 12;
BA_ "GenSigSendOnInit" SG_ 2152071168 LRSAP_LmbrUpDwn 2;
BA_ "SignalType" SG_ 2152071168 LRSAP_LmbrUpDwn "UNM";
BA_ "PacketOrder" SG_ 2152071168 LRSAP_LmbrUpDwn 8;
BA_ "SignalLongName" SG_ 2152071168 LRSAP_LmbrUpDwn "Left Rear Seat Actuator Priority : Lumbar Up/Down";
BA_ "VNSigAllNodes" SG_ 2152071168 LRSAP_LmbrUpDwn 1;
BA_ "GenSigDeltaValue" SG_ 2152071168 LRSAP_UprShldrFwdRr 1;
BA_ "GenSigSendType" SG_ 2152071168 LRSAP_UprShldrFwdRr 12;
BA_ "GenSigSendOnInit" SG_ 2152071168 LRSAP_UprShldrFwdRr 2;
BA_ "SignalType" SG_ 2152071168 LRSAP_UprShldrFwdRr "UNM";
BA_ "PacketOrder" SG_ 2152071168 LRSAP_UprShldrFwdRr 7;
BA_ "SignalLongName" SG_ 2152071168 LRSAP_UprShldrFwdRr "Left Rear Seat Actuator Priority : Upper Shoulder Forward/Rearward";
BA_ "VNSigAllNodes" SG_ 2152071168 LRSAP_UprShldrFwdRr 1;
BA_ "GenSigDeltaValue" SG_ 2152071168 LRSAP_HdrstTltFwdRr 1;
BA_ "GenSigSendType" SG_ 2152071168 LRSAP_HdrstTltFwdRr 12;
BA_ "GenSigSendOnInit" SG_ 2152071168 LRSAP_HdrstTltFwdRr 2;
BA_ "SignalType" SG_ 2152071168 LRSAP_HdrstTltFwdRr "UNM";
BA_ "PacketOrder" SG_ 2152071168 LRSAP_HdrstTltFwdRr 6;
BA_ "SignalLongName" SG_ 2152071168 LRSAP_HdrstTltFwdRr "Left Rear Seat Actuator Priority : Headrest Tilt Forward/Rearward";
BA_ "VNSigAllNodes" SG_ 2152071168 LRSAP_HdrstTltFwdRr 1;
BA_ "GenSigDeltaValue" SG_ 2152071168 LRSAP_HdrstWngsInOut 1;
BA_ "GenSigSendType" SG_ 2152071168 LRSAP_HdrstWngsInOut 12;
BA_ "GenSigSendOnInit" SG_ 2152071168 LRSAP_HdrstWngsInOut 2;
BA_ "SignalType" SG_ 2152071168 LRSAP_HdrstWngsInOut "UNM";
BA_ "PacketOrder" SG_ 2152071168 LRSAP_HdrstWngsInOut 5;
BA_ "SignalLongName" SG_ 2152071168 LRSAP_HdrstWngsInOut "Left Rear Seat Actuator Priority : Headrest Wings Inward/Outward";
BA_ "VNSigAllNodes" SG_ 2152071168 LRSAP_HdrstWngsInOut 1;
BA_ "GenSigDeltaValue" SG_ 2152071168 LRSAP_HdrstUpDnFdRr 1;
BA_ "GenSigSendType" SG_ 2152071168 LRSAP_HdrstUpDnFdRr 12;
BA_ "GenSigSendOnInit" SG_ 2152071168 LRSAP_HdrstUpDnFdRr 2;
BA_ "SignalType" SG_ 2152071168 LRSAP_HdrstUpDnFdRr "UNM";
BA_ "PacketOrder" SG_ 2152071168 LRSAP_HdrstUpDnFdRr 4;
BA_ "SignalLongName" SG_ 2152071168 LRSAP_HdrstUpDnFdRr "Left Rear Seat Actuator Priority : Headrest Up/Down and Forward/Rearward";
BA_ "VNSigAllNodes" SG_ 2152071168 LRSAP_HdrstUpDnFdRr 1;
BA_ "GenSigDeltaValue" SG_ 2152071168 LRSAP_HdrstFwdRrwd 1;
BA_ "GenSigSendType" SG_ 2152071168 LRSAP_HdrstFwdRrwd 12;
BA_ "GenSigSendOnInit" SG_ 2152071168 LRSAP_HdrstFwdRrwd 2;
BA_ "SignalType" SG_ 2152071168 LRSAP_HdrstFwdRrwd "UNM";
BA_ "PacketOrder" SG_ 2152071168 LRSAP_HdrstFwdRrwd 3;
BA_ "SignalLongName" SG_ 2152071168 LRSAP_HdrstFwdRrwd "Left Rear Seat Actuator Priority : Headrest Forward/Rearward";
BA_ "VNSigAllNodes" SG_ 2152071168 LRSAP_HdrstFwdRrwd 1;
BA_ "GenSigDeltaValue" SG_ 2152071168 LRSAP_HdrstUpDn 1;
BA_ "GenSigSendType" SG_ 2152071168 LRSAP_HdrstUpDn 12;
BA_ "GenSigSendOnInit" SG_ 2152071168 LRSAP_HdrstUpDn 2;
BA_ "SignalType" SG_ 2152071168 LRSAP_HdrstUpDn "UNM";
BA_ "PacketOrder" SG_ 2152071168 LRSAP_HdrstUpDn 2;
BA_ "SignalLongName" SG_ 2152071168 LRSAP_HdrstUpDn "Left Rear Seat Actuator Priority : Headrest Up/Down";
BA_ "VNSigAllNodes" SG_ 2152071168 LRSAP_HdrstUpDn 1;
BA_ "GenSigDeltaValue" SG_ 2152071168 LRSAP_Massg 1;
BA_ "GenSigSendType" SG_ 2152071168 LRSAP_Massg 12;
BA_ "GenSigSendOnInit" SG_ 2152071168 LRSAP_Massg 2;
BA_ "SignalType" SG_ 2152071168 LRSAP_Massg "UNM";
BA_ "PacketOrder" SG_ 2152071168 LRSAP_Massg 1;
BA_ "SignalLongName" SG_ 2152071168 LRSAP_Massg "Left Rear Seat Actuator Priority : Massage";
BA_ "VNSigAllNodes" SG_ 2152071168 LRSAP_Massg 1;
BA_ "GenSigSendType" SG_ 2153947136 RmtRflshMdAct 10;
BA_ "VNSigRemoteDiagnostics" SG_ 2153947136 RmtRflshMdAct 1;
BA_ "SignalType" SG_ 2153947136 RmtRflshMdAct "BLN";
BA_ "SignalLongName" SG_ 2153947136 RmtRflshMdAct "Remote Reflash Mode Active";
BA_ "GenSigDeltaValue" SG_ 2152628224 OBTCR_ReqstrID 1;
BA_ "GenSigSendType" SG_ 2152628224 OBTCR_ReqstrID 12;
BA_ "VNSigInfotainment" SG_ 2152628224 OBTCR_ReqstrID 1;
BA_ "SignalType" SG_ 2152628224 OBTCR_ReqstrID "UNM";
BA_ "PacketOrder" SG_ 2152628224 OBTCR_ReqstrID 2;
BA_ "SignalLongName" SG_ 2152628224 OBTCR_ReqstrID "On Board Tester Coordination Response : Requester ID";
BA_ "VNSigAllNodes" SG_ 2152628224 OBTCR_ReqstrID 1;
BA_ "GenSigSendType" SG_ 2152628224 OBTCR_Stat 10;
BA_ "VNSigInfotainment" SG_ 2152628224 OBTCR_Stat 1;
BA_ "SignalType" SG_ 2152628224 OBTCR_Stat "ENM";
BA_ "PacketOrder" SG_ 2152628224 OBTCR_Stat 1;
BA_ "SignalLongName" SG_ 2152628224 OBTCR_Stat "On Board Tester Coordination Response : Status";
BA_ "VNSigAllNodes" SG_ 2152628224 OBTCR_Stat 1;
BA_ "GenSigSendType" SG_ 2152628224 OBTCMstrStat 10;
BA_ "GenSigSendOnInit" SG_ 2152628224 OBTCMstrStat 1;
BA_ "VNSigInfotainment" SG_ 2152628224 OBTCMstrStat 1;
BA_ "SignalType" SG_ 2152628224 OBTCMstrStat "ENM";
BA_ "SignalLongName" SG_ 2152628224 OBTCMstrStat "On Board Tester Coordination Master Status";
BA_ "VNSigAllNodes" SG_ 2152628224 OBTCMstrStat 1;
BA_ "GenSigSendType" SG_ 2152112128 PMVSS_Disps 10;
BA_ "GenSigSendOnInit" SG_ 2152112128 PMVSS_Disps 2;
BA_ "SignalType" SG_ 2152112128 PMVSS_Disps "ENM";
BA_ "PacketOrder" SG_ 2152112128 PMVSS_Disps 11;
BA_ "SignalLongName" SG_ 2152112128 PMVSS_Disps "Performance Mode Visualization Screen Status : Displays";
BA_ "VNSigAllNodes" SG_ 2152112128 PMVSS_Disps 1;
BA_ "GenSigSendType" SG_ 2152112128 PMVSS_Exhst 10;
BA_ "GenSigSendOnInit" SG_ 2152112128 PMVSS_Exhst 2;
BA_ "SignalType" SG_ 2152112128 PMVSS_Exhst "ENM";
BA_ "PacketOrder" SG_ 2152112128 PMVSS_Exhst 10;
BA_ "SignalLongName" SG_ 2152112128 PMVSS_Exhst "Performance Mode Visualization Screen Status : Exhaust";
BA_ "VNSigAllNodes" SG_ 2152112128 PMVSS_Exhst 1;
BA_ "GenSigSendType" SG_ 2152112128 PMVSS_PsngrSeat 10;
BA_ "GenSigSendOnInit" SG_ 2152112128 PMVSS_PsngrSeat 2;
BA_ "SignalType" SG_ 2152112128 PMVSS_PsngrSeat "ENM";
BA_ "PacketOrder" SG_ 2152112128 PMVSS_PsngrSeat 9;
BA_ "SignalLongName" SG_ 2152112128 PMVSS_PsngrSeat "Performance Mode Visualization Screen Status : Passenger Seat";
BA_ "VNSigAllNodes" SG_ 2152112128 PMVSS_PsngrSeat 1;
BA_ "GenSigSendType" SG_ 2152112128 PMVSS_DrvrSeat 10;
BA_ "GenSigSendOnInit" SG_ 2152112128 PMVSS_DrvrSeat 2;
BA_ "SignalType" SG_ 2152112128 PMVSS_DrvrSeat "ENM";
BA_ "PacketOrder" SG_ 2152112128 PMVSS_DrvrSeat 8;
BA_ "SignalLongName" SG_ 2152112128 PMVSS_DrvrSeat "Performance Mode Visualization Screen Status : Driver Seat";
BA_ "VNSigAllNodes" SG_ 2152112128 PMVSS_DrvrSeat 1;
BA_ "GenSigSendType" SG_ 2152112128 PMVSS_AdptCrsCnt 10;
BA_ "GenSigSendOnInit" SG_ 2152112128 PMVSS_AdptCrsCnt 2;
BA_ "SignalType" SG_ 2152112128 PMVSS_AdptCrsCnt "ENM";
BA_ "PacketOrder" SG_ 2152112128 PMVSS_AdptCrsCnt 7;
BA_ "SignalLongName" SG_ 2152112128 PMVSS_AdptCrsCnt "Performance Mode Visualization Screen Status : Adaptive Cruise Control";
BA_ "VNSigAllNodes" SG_ 2152112128 PMVSS_AdptCrsCnt 1;
BA_ "GenSigSendType" SG_ 2152112128 PMVSS_Drvln 10;
BA_ "GenSigSendOnInit" SG_ 2152112128 PMVSS_Drvln 2;
BA_ "SignalType" SG_ 2152112128 PMVSS_Drvln "ENM";
BA_ "PacketOrder" SG_ 2152112128 PMVSS_Drvln 6;
BA_ "SignalLongName" SG_ 2152112128 PMVSS_Drvln "Performance Mode Visualization Screen Status : Driveline";
BA_ "VNSigAllNodes" SG_ 2152112128 PMVSS_Drvln 1;
BA_ "GenSigSendType" SG_ 2152112128 PMVSS_Susp 10;
BA_ "GenSigSendOnInit" SG_ 2152112128 PMVSS_Susp 2;
BA_ "SignalType" SG_ 2152112128 PMVSS_Susp "ENM";
BA_ "PacketOrder" SG_ 2152112128 PMVSS_Susp 5;
BA_ "SignalLongName" SG_ 2152112128 PMVSS_Susp "Performance Mode Visualization Screen Status : Suspension";
BA_ "VNSigAllNodes" SG_ 2152112128 PMVSS_Susp 1;
BA_ "GenSigSendType" SG_ 2152112128 PMVSS_Strng 10;
BA_ "GenSigSendOnInit" SG_ 2152112128 PMVSS_Strng 2;
BA_ "SignalType" SG_ 2152112128 PMVSS_Strng "ENM";
BA_ "PacketOrder" SG_ 2152112128 PMVSS_Strng 4;
BA_ "SignalLongName" SG_ 2152112128 PMVSS_Strng "Performance Mode Visualization Screen Status : Steering";
BA_ "VNSigAllNodes" SG_ 2152112128 PMVSS_Strng 1;
BA_ "GenSigSendType" SG_ 2152112128 PMVSS_Trans 10;
BA_ "GenSigSendOnInit" SG_ 2152112128 PMVSS_Trans 2;
BA_ "SignalType" SG_ 2152112128 PMVSS_Trans "ENM";
BA_ "PacketOrder" SG_ 2152112128 PMVSS_Trans 3;
BA_ "SignalLongName" SG_ 2152112128 PMVSS_Trans "Performance Mode Visualization Screen Status : Transmission";
BA_ "VNSigAllNodes" SG_ 2152112128 PMVSS_Trans 1;
BA_ "GenSigSendType" SG_ 2152112128 PMVSS_Eng 10;
BA_ "GenSigSendOnInit" SG_ 2152112128 PMVSS_Eng 2;
BA_ "SignalType" SG_ 2152112128 PMVSS_Eng "ENM";
BA_ "PacketOrder" SG_ 2152112128 PMVSS_Eng 2;
BA_ "SignalLongName" SG_ 2152112128 PMVSS_Eng "Performance Mode Visualization Screen Status : Engine";
BA_ "VNSigAllNodes" SG_ 2152112128 PMVSS_Eng 1;
BA_ "GenSigSendType" SG_ 2152112128 PMVSS_Snd 10;
BA_ "GenSigSendOnInit" SG_ 2152112128 PMVSS_Snd 2;
BA_ "SignalType" SG_ 2152112128 PMVSS_Snd "ENM";
BA_ "PacketOrder" SG_ 2152112128 PMVSS_Snd 1;
BA_ "SignalLongName" SG_ 2152112128 PMVSS_Snd "Performance Mode Visualization Screen Status : Sound";
BA_ "VNSigAllNodes" SG_ 2152112128 PMVSS_Snd 1;
BA_ "GenSigSendType" SG_ 2152112128 PerfMdMainMenuType 10;
BA_ "GenSigSendOnInit" SG_ 2152112128 PerfMdMainMenuType 2;
BA_ "SignalType" SG_ 2152112128 PerfMdMainMenuType "ENM";
BA_ "SignalLongName" SG_ 2152112128 PerfMdMainMenuType "Performance Mode Main Menu Type";
BA_ "VNSigAllNodes" SG_ 2152112128 PerfMdMainMenuType 1;
BA_REL_ "GenSigSuprvResp" BU_SG_REL_ IPC_LS SG_ 2150531072 OBHVDCCMinRmng 1;
BA_REL_ "GenSigSuprvResp" BU_SG_REL_ RadioHead_LS SG_ 2150531072 OBHVDCCMinRmng 1;
BA_REL_ "GenSigSuprvResp" BU_SG_REL_ IPC_LS SG_ 2150531072 OBHVDCCCpltnTmDspFrmt 1;
BA_REL_ "GenSigSuprvResp" BU_SG_REL_ RadioHead_LS SG_ 2150531072 OBHVDCCCpltnTmDspFrmt 1;
BA_REL_ "GenSigSuprvResp" BU_SG_REL_ CSM_LS SG_ 2150531072 HVBChrgOvrdBtnDspStat 1;
BA_REL_ "GenSigSuprvResp" BU_SG_REL_ RadioHead_LS SG_ 2150531072 HVBChrgOvrdBtnDspStat 1;
BA_REL_ "GenSigSuprvResp" BU_SG_REL_ CSM_LS SG_ 2150531072 HVBChrgLmtBtnDspStat 1;
BA_REL_ "GenSigSuprvResp" BU_SG_REL_ RadioHead_LS SG_ 2150531072 HVBChrgLmtBtnDspStat 1;
BA_REL_ "GenSigSuprvResp" BU_SG_REL_ CSM_LS SG_ 2150531072 HVBHmChrgTmDspStat 1;
BA_REL_ "GenSigSuprvResp" BU_SG_REL_ RadioHead_LS SG_ 2150531072 HVBHmChrgTmDspStat 1;
BA_REL_ "GenSigSuprvResp" BU_SG_REL_ CSM_LS SG_ 2150531072 HVBChrgTmDspStat 1;
BA_REL_ "GenSigSuprvResp" BU_SG_REL_ RadioHead_LS SG_ 2150531072 HVBChrgTmDspStat 1;
BA_REL_ "GenSigSuprvResp" BU_SG_REL_ IPC_LS SG_ 2151702528 LnMrkngIndRgt 1;
BA_REL_ "GenSigSuprvResp" BU_SG_REL_ IPC_LS SG_ 2151702528 LnMrkngIndLft 1;
BA_REL_ "GenSigSuprvResp" BU_SG_REL_ IPC_LS SG_ 2151702528 LnKepAsstStIndRgt 1;
BA_REL_ "GenSigSuprvResp" BU_SG_REL_ IPC_LS SG_ 2151702528 LnKepAsstStIndLft 1;
BA_REL_ "GenSigSuprvResp" BU_SG_REL_ IPC_LS SG_ 2151702528 LnKpngAstRecfblIndRq 1;
BA_REL_ "GenSigSuprvResp" BU_SG_REL_ EOCM2A_K1_LS SG_ 2156986368 WiFiPssPhrsDgts17to24_Mp 1;
BA_REL_ "GenSigSuprvResp" BU_SG_REL_ EOCM2B_K1_LS SG_ 2156986368 WiFiPssPhrsDgts17to24_Mp 1;
BA_REL_ "GenSigSuprvResp" BU_SG_REL_ EOCM2A_K1_LS SG_ 2156978176 WiFiPssPhrsDgts9to16_Mp 1;
BA_REL_ "GenSigSuprvResp" BU_SG_REL_ EOCM2B_K1_LS SG_ 2156978176 WiFiPssPhrsDgts9to16_Mp 1;
BA_REL_ "GenSigSuprvResp" BU_SG_REL_ EOCM2A_K1_LS SG_ 2156969984 WiFiPssPhrsDgts1to8_Mp 1;
BA_REL_ "GenSigSuprvResp" BU_SG_REL_ EOCM2B_K1_LS SG_ 2156969984 WiFiPssPhrsDgts1to8_Mp 1;
BA_REL_ "GenSigSuprvResp" BU_SG_REL_ MSM_LR_LS SG_ 2155126784 DrvrSetRrwrdMvmnt 1;
BA_REL_ "GenSigSuprvResp" BU_SG_REL_ RSC_LS SG_ 2154725376 AuxHtrAtv378 1;
BA_REL_ "GenSigSuprvResp" BU_SG_REL_ ECC_LS SG_ 2154725376 AuxHtrAtv378 1;
BA_REL_ "GenSigSuprvResp" BU_SG_REL_ RSC_LS SG_ 2154725376 AuxHtrRq 1;
BA_REL_ "GenSigSuprvResp" BU_SG_REL_ ECC_LS SG_ 2154725376 AuxHtrRq 1;
BA_REL_ "GenSigSuprvResp" BU_SG_REL_ EOCM2A_K1_LS SG_ 2156994560 WAPDM_SecurityType 1;
BA_REL_ "GenSigSuprvResp" BU_SG_REL_ EOCM2B_K1_LS SG_ 2156994560 WAPDM_SecurityType 1;
BA_REL_ "GenSigSuprvResp" BU_SG_REL_ EOCM2A_K1_LS SG_ 2156994560 WAPDM_WiFiEnStat 1;
BA_REL_ "GenSigSuprvResp" BU_SG_REL_ EOCM2B_K1_LS SG_ 2156994560 WAPDM_WiFiEnStat 1;
BA_REL_ "GenSigSuprvResp" BU_SG_REL_ EOCM2A_K1_LS SG_ 2156994560 WAPDM_EncrptnType 1;
BA_REL_ "GenSigSuprvResp" BU_SG_REL_ EOCM2B_K1_LS SG_ 2156994560 WAPDM_EncrptnType 1;
BA_REL_ "GenSigSuprvResp" BU_SG_REL_ CSM_LS SG_ 2158133248 ChrgCmpltFstChgingAct 1;
BA_REL_ "GenSigSuprvResp" BU_SG_REL_ RadioHead_LS SG_ 2158133248 ChrgCmpltFstChgingAct 1;
BA_REL_ "GenSigSuprvResp" BU_SG_REL_ IPC_LS SG_ 2158133248 ChrgCmpltFstChgingAct 1;
BA_REL_ "GenSigSuprvResp" BU_SG_REL_ IPC_LS SG_ 2158133248 TgtChrgLvlPctgCurStValPKIn 1;
BA_REL_ "GenSigSuprvResp" BU_SG_REL_ IPC_LS SG_ 2158133248 TrgtChrgLvlAct 1;
BA_REL_ "GenSigSuprvResp" BU_SG_REL_ VPM_LS SG_ 2154651648 TAC_AudConctOutcm 1;
BA_REL_ "GenSigSuprvResp" BU_SG_REL_ VPM_LS SG_ 2154651648 TAC_AudChConctStat 1;
BA_REL_ "GenSigSuprvResp" BU_SG_REL_ VPM_LS SG_ 2154635264 TAR_AudSrcStat 1;
BA_REL_ "GenSigSuprvResp" BU_SG_REL_ VPM_LS SG_ 2154635264 TAR_AudConctReq 1;
BA_REL_ "GenSigSuprvResp" BU_SG_REL_ CSM_LS SG_ 2154872832 InfoActvnReq 1;
BA_REL_ "GenSigSuprvResp" BU_SG_REL_ EOCM2A_K1_LS SG_ 2156961792 WiFiSSIDDgts17to24_Mp 1;
BA_REL_ "GenSigSuprvResp" BU_SG_REL_ EOCM2B_K1_LS SG_ 2156961792 WiFiSSIDDgts17to24_Mp 1;
BA_REL_ "GenSigSuprvResp" BU_SG_REL_ VICM_LS SG_ 2154569728 InfotnmntSysSt 1;
BA_REL_ "GenSigRxStartValue" BU_SG_REL_ CHUD_LS SG_ 2154569728 InfotnmntSysSt "0";
BA_REL_ "GenSigSuprvResp" BU_SG_REL_ CHUD_LS SG_ 2154569728 InfotnmntSysSt 1;
BA_REL_ "GenSigSuprvResp" BU_SG_REL_ TCP_LS SG_ 2154569728 InfotnmntSysSt 1;
BA_REL_ "GenSigSuprvResp" BU_SG_REL_ TouchPad_LS SG_ 2154569728 InfotnmntSysSt 1;
BA_REL_ "GenSigSuprvResp" BU_SG_REL_ RSC_LS SG_ 2154569728 InfotnmntSysSt 1;
BA_REL_ "GenSigSuprvResp" BU_SG_REL_ LVMPC_LS SG_ 2154569728 InfotnmntSysSt 1;
BA_REL_ "GenSigSuprvResp" BU_SG_REL_ LVMNav_LS SG_ 2154569728 InfotnmntSysSt 1;
BA_REL_ "GenSigSuprvResp" BU_SG_REL_ RSE_LS SG_ 2154569728 InfotnmntSysSt 1;
BA_REL_ "GenSigSuprvResp" BU_SG_REL_ ICS_LS SG_ 2154569728 InfotnmntSysSt 1;
BA_REL_ "GenSigSuprvResp" BU_SG_REL_ AMP_LS SG_ 2154569728 InfotnmntSysSt 1;
BA_REL_ "GenSigSuprvResp" BU_SG_REL_ IPC_LS SG_ 2151931904 FourWhlDrvIdReqExtRng 1;
BA_REL_ "GenSigSuprvResp" BU_SG_REL_ IPC_LS SG_ 2151931904 FuelMdTrnstnIndReq 1;
BA_REL_ "GenSigSuprvResp" BU_SG_REL_ IPC_LS SG_ 2151931904 BiFuelRflGaslinIndReq 1;
BA_REL_ "GenSigSuprvResp" BU_SG_REL_ CGM_LS SG_ 2151931904 VehStbCmptvMdCstAvl 1;
BA_REL_ "GenSigSuprvResp" BU_SG_REL_ CGM_LS SG_ 2151931904 VehStbCmptvMdCurSt 1;
BA_REL_ "GenSigSuprvResp" BU_SG_REL_ IPC_LS SG_ 2151931904 TCSysCurSt 1;
BA_REL_ "GenSigSuprvResp" BU_SG_REL_ IPC_LS SG_ 2151931904 ElctShfPriLtdPerfMdIO 1;
BA_REL_ "GenSigSuprvResp" BU_SG_REL_ IPC_LS SG_ 2151931904 LnchCtrlWhlSlpStat 1;
BA_REL_ "GenSigSuprvResp" BU_SG_REL_ IPC_LS SG_ 2151931904 LnchCtrlMdStat 1;
BA_REL_ "GenSigSuprvResp" BU_SG_REL_ IPC_LS SG_ 2151931904 LnchCtrlEngRPMStat 1;
BA_REL_ "GenSigSuprvResp" BU_SG_REL_ IPC_LS SG_ 2151931904 RegVltCtlEngyRcvryAct 1;
BA_REL_ "GenSigSuprvResp" BU_SG_REL_ V2V_LS SG_ 2151931904 VehSpdCntlSystmType 1;
BA_REL_ "GenSigSuprvResp" BU_SG_REL_ IPC_LS SG_ 2151931904 VehSpdCntlSystmType 1;
BA_REL_ "GenSigSuprvResp" BU_SG_REL_ V2V_LS SG_ 2151931904 ACCSysSltdMdDispIO 1;
BA_REL_ "GenSigSuprvResp" BU_SG_REL_ IPC_LS SG_ 2151931904 ACCSysSltdMdDispIO 1;
BA_REL_ "GenSigSuprvResp" BU_SG_REL_ V2V_LS SG_ 2151931904 ACCSysSltdMd 1;
BA_REL_ "GenSigSuprvResp" BU_SG_REL_ IPC_LS SG_ 2151931904 ACCSysSltdMd 1;
BA_REL_ "GenSigSuprvResp" BU_SG_REL_ IPC_LS SG_ 2151931904 PTExPrtclFltWrng3IO 1;
BA_REL_ "GenSigSuprvResp" BU_SG_REL_ IPC_LS SG_ 2151931904 PTExPartFltManRegStat 1;
BA_REL_ "GenSigSuprvResp" BU_SG_REL_ IPC_LS SG_ 2151931904 AWDRecmndIO 1;
BA_REL_ "GenSigSuprvResp" BU_SG_REL_ CSM_LS SG_ 2150244352 ECHGDDV_Col10 1;
BA_REL_ "GenSigSuprvResp" BU_SG_REL_ RadioHead_LS SG_ 2150244352 ECHGDDV_Col10 1;
BA_REL_ "GenSigSuprvResp" BU_SG_REL_ CSM_LS SG_ 2150244352 ECHGDDV_Col9 1;
BA_REL_ "GenSigSuprvResp" BU_SG_REL_ RadioHead_LS SG_ 2150244352 ECHGDDV_Col9 1;
BA_REL_ "GenSigSuprvResp" BU_SG_REL_ CSM_LS SG_ 2150244352 ECHGDDV_Col8 1;
BA_REL_ "GenSigSuprvResp" BU_SG_REL_ RadioHead_LS SG_ 2150244352 ECHGDDV_Col8 1;
BA_REL_ "GenSigSuprvResp" BU_SG_REL_ CSM_LS SG_ 2150244352 ECHGDDV_Col7 1;
BA_REL_ "GenSigSuprvResp" BU_SG_REL_ RadioHead_LS SG_ 2150244352 ECHGDDV_Col7 1;
BA_REL_ "GenSigSuprvResp" BU_SG_REL_ CSM_LS SG_ 2150244352 ECHGDDV_Col6 1;
BA_REL_ "GenSigSuprvResp" BU_SG_REL_ RadioHead_LS SG_ 2150244352 ECHGDDV_Col6 1;
BA_REL_ "GenSigSuprvResp" BU_SG_REL_ CSM_LS SG_ 2150244352 ECHGDDV_Col5 1;
BA_REL_ "GenSigSuprvResp" BU_SG_REL_ RadioHead_LS SG_ 2150244352 ECHGDDV_Col5 1;
BA_REL_ "GenSigSuprvResp" BU_SG_REL_ CSM_LS SG_ 2150244352 ECHGDDV_Col4 1;
BA_REL_ "GenSigSuprvResp" BU_SG_REL_ RadioHead_LS SG_ 2150244352 ECHGDDV_Col4 1;
BA_REL_ "GenSigSuprvResp" BU_SG_REL_ CSM_LS SG_ 2150244352 ECHGDDV_Col3 1;
BA_REL_ "GenSigSuprvResp" BU_SG_REL_ RadioHead_LS SG_ 2150244352 ECHGDDV_Col3 1;
BA_REL_ "GenSigSuprvResp" BU_SG_REL_ CSM_LS SG_ 2150244352 ECHGDDV_Col2 1;
BA_REL_ "GenSigSuprvResp" BU_SG_REL_ RadioHead_LS SG_ 2150244352 ECHGDDV_Col2 1;
BA_REL_ "GenSigSuprvResp" BU_SG_REL_ CSM_LS SG_ 2150244352 ECHGDDV_Col1 1;
BA_REL_ "GenSigSuprvResp" BU_SG_REL_ RadioHead_LS SG_ 2150244352 ECHGDDV_Col1 1;
BA_REL_ "GenSigSuprvResp" BU_SG_REL_ CSM_LS SG_ 2150244352 ECHGDDV_EngyConsAvg 1;
BA_REL_ "GenSigSuprvResp" BU_SG_REL_ RadioHead_LS SG_ 2150244352 ECHGDDV_EngyConsAvg 1;
BA_REL_ "GenSigSuprvResp" BU_SG_REL_ EOCM2A_K1_LS SG_ 2156953600 WiFiSSIDDgts9to16_Mp 1;
BA_REL_ "GenSigSuprvResp" BU_SG_REL_ EOCM2B_K1_LS SG_ 2156953600 WiFiSSIDDgts9to16_Mp 1;
BA_REL_ "GenSigSuprvResp" BU_SG_REL_ RCRM_LS SG_ 2151686144 RrCmrDeplmntReqtsd 1;
BA_REL_ "GenSigSuprvResp" BU_SG_REL_ HBSM_LS SG_ 2155028480 RtLnChngThrtAprchSpd 1;
BA_REL_ "GenSigSuprvResp" BU_SG_REL_ VIS2_LS SG_ 2155028480 RgtLnChgThrt 1;
BA_REL_ "GenSigSuprvResp" BU_SG_REL_ HBSM_LS SG_ 2155028480 RgtLnChgThrt 1;
BA_REL_ "GenSigSuprvResp" BU_SG_REL_ FCM_LS SG_ 2155028480 RgtLnChgThrt 1;
BA_REL_ "GenSigSuprvResp" BU_SG_REL_ EOCM_F_LS SG_ 2155028480 RgtLnChgThrt 1;
BA_REL_ "GenSigSuprvResp" BU_SG_REL_ IPC_LS SG_ 2151915520 ElcShfPriTwoGrsSlInRq 1;
BA_REL_ "GenSigSuprvResp" BU_SG_REL_ CGM_LS SG_ 2151915520 ElcShfPriTwoGrsSlInRq 1;
BA_REL_ "GenSigSuprvResp" BU_SG_REL_ IPC_LS SG_ 2151915520 DrvEffInd 1;
BA_REL_ "GenSigSuprvResp" BU_SG_REL_ IPC_LS SG_ 2151915520 EngIntkArBstPrExtRng 1;
BA_REL_ "GenSigSuprvResp" BU_SG_REL_ IPC_LS SG_ 2151915520 ElecShfRngDispRCExtd 1;
BA_REL_ "GenSigSuprvResp" BU_SG_REL_ IPC_LS SG_ 2151915520 ElecShfRngDisp 1;
BA_REL_ "GenSigVDAFailComment" BU_SG_REL_ IPC_LS SG_ 2151915520 ESPTransMalfIO "Electronic Transmission Range Select Virtual Device Availability";
BA_REL_ "GenSigVDAFailResp" BU_SG_REL_ IPC_LS SG_ 2151915520 ESPTransMalfIO 1;
BA_REL_ "GenSigSuprvResp" BU_SG_REL_ IPC_LS SG_ 2151915520 ESPTransMalfIO 1;
BA_REL_ "GenSigSuprvResp" BU_SG_REL_ CGM_LS SG_ 2151915520 ESPTransMalfIO 1;
BA_REL_ "GenSigSuprvResp" BU_SG_REL_ IPC_LS SG_ 2151915520 ESPRngInvldReqIO 1;
BA_REL_ "GenSigSuprvResp" BU_SG_REL_ IPC_LS SG_ 2151915520 ESPPrkInvldReqIO 1;
BA_REL_ "GenSigSuprvResp" BU_SG_REL_ IPC_LS SG_ 2151915520 ESPHldShfLvrToEngRgIO 1;
BA_REL_ "GenSigSuprvResp" BU_SG_REL_ IPC_LS SG_ 2151915520 ESPDrvrPrkIlkSftAtdIO 1;
BA_REL_ "GenSigSuprvResp" BU_SG_REL_ IPC_LS SG_ 2151915520 ESPDrvrIlkShfAtdIO 1;
BA_REL_ "GenSigSuprvResp" BU_SG_REL_ IPC_LS SG_ 2151915520 AHAct 1;
BA_REL_ "GenSigSuprvResp" BU_SG_REL_ IPC_LS SG_ 2151915520 AHEnbld 1;
BA_REL_ "GenSigSuprvResp" BU_SG_REL_ IPC_LS SG_ 2151915520 ShfToPrkBfExtngIO 1;
BA_REL_ "GenSigSuprvResp" BU_SG_REL_ IPC_LS SG_ 2151915520 AHServcIO 1;
BA_REL_ "GenSigSuprvResp" BU_SG_REL_ IPC_LS SG_ 2151915520 AHAppBrkPedlIO 1;
BA_REL_ "GenSigSuprvResp" BU_SG_REL_ IPC_LS SG_ 2151915520 AHDisbldStbltIO 1;
BA_REL_ "GenSigSuprvResp" BU_SG_REL_ IPC_LS SG_ 2151915520 AHDisbldDrOpnIO 1;
BA_REL_ "GenSigSuprvResp" BU_SG_REL_ BCM_LS SG_ 2154381312 CSZS_FrntCmptZnMbDevStat 1;
BA_REL_ "GenSigSuprvResp" BU_SG_REL_ BCM_LS SG_ 2154381312 CSZS_RrCmptZnMbDevStat 1;
BA_REL_ "GenSigSuprvResp" BU_SG_REL_ BCM_LS SG_ 2154381312 CSZS_FrntExtrZnMbDevStat 1;
BA_REL_ "GenSigSuprvResp" BU_SG_REL_ BCM_LS SG_ 2154381312 CSZS_RrExtrZnMbDevStat 1;
BA_REL_ "GenSigSuprvResp" BU_SG_REL_ BCM_LS SG_ 2154381312 CSZS_WlcmZnMbDevStat 1;
BA_REL_ "GenSigSuprvResp" BU_SG_REL_ BCM_LS SG_ 2154381312 CSZS_IntrZnMbDevStat 1;
BA_REL_ "GenSigSuprvResp" BU_SG_REL_ BCM_LS SG_ 2154381312 CSZS_PassEntyZnMbDevStat 1;
BA_REL_ "GenSigSuprvResp" BU_SG_REL_ BCM_LS SG_ 2154381312 CSZS_DrEntyZnMbDevStat 1;
BA_REL_ "GenSigSuprvResp" BU_SG_REL_ CSM_LS SG_ 2153947136 RmtRflshMdAct 1;
BA_REL_ "GenSigSuprvResp" BU_SG_REL_ RadioHead_LS SG_ 2153947136 RmtRflshMdAct 1;
BA_REL_ "GenSigSuprvResp" BU_SG_REL_ CSM_LS SG_ 2152628224 OBTCR_ReqstrID 1;
BA_REL_ "GenSigSuprvResp" BU_SG_REL_ CSM_LS SG_ 2152628224 OBTCR_Stat 1;
BA_REL_ "GenSigSuprvResp" BU_SG_REL_ CSM_LS SG_ 2152628224 OBTCMstrStat 1;
BA_REL_ "GenSigSuprvResp" BU_SG_REL_ CSM_LS SG_ 2152112128 PMVSS_Disps 1;
BA_REL_ "GenSigSuprvResp" BU_SG_REL_ RadioHead_LS SG_ 2152112128 PMVSS_Disps 1;
BA_REL_ "GenSigSuprvResp" BU_SG_REL_ CSM_LS SG_ 2152112128 PMVSS_Exhst 1;
BA_REL_ "GenSigSuprvResp" BU_SG_REL_ RadioHead_LS SG_ 2152112128 PMVSS_Exhst 1;
BA_REL_ "GenSigSuprvResp" BU_SG_REL_ CSM_LS SG_ 2152112128 PMVSS_PsngrSeat 1;
BA_REL_ "GenSigSuprvResp" BU_SG_REL_ RadioHead_LS SG_ 2152112128 PMVSS_PsngrSeat 1;
BA_REL_ "GenSigSuprvResp" BU_SG_REL_ CSM_LS SG_ 2152112128 PMVSS_DrvrSeat 1;
BA_REL_ "GenSigSuprvResp" BU_SG_REL_ RadioHead_LS SG_ 2152112128 PMVSS_DrvrSeat 1;
BA_REL_ "GenSigSuprvResp" BU_SG_REL_ CSM_LS SG_ 2152112128 PMVSS_AdptCrsCnt 1;
BA_REL_ "GenSigSuprvResp" BU_SG_REL_ RadioHead_LS SG_ 2152112128 PMVSS_AdptCrsCnt 1;
BA_REL_ "GenSigSuprvResp" BU_SG_REL_ CSM_LS SG_ 2152112128 PMVSS_Drvln 1;
BA_REL_ "GenSigSuprvResp" BU_SG_REL_ RadioHead_LS SG_ 2152112128 PMVSS_Drvln 1;
BA_REL_ "GenSigSuprvResp" BU_SG_REL_ CSM_LS SG_ 2152112128 PMVSS_Susp 1;
BA_REL_ "GenSigSuprvResp" BU_SG_REL_ RadioHead_LS SG_ 2152112128 PMVSS_Susp 1;
BA_REL_ "GenSigSuprvResp" BU_SG_REL_ CSM_LS SG_ 2152112128 PMVSS_Strng 1;
BA_REL_ "GenSigSuprvResp" BU_SG_REL_ RadioHead_LS SG_ 2152112128 PMVSS_Strng 1;
BA_REL_ "GenSigSuprvResp" BU_SG_REL_ CSM_LS SG_ 2152112128 PMVSS_Trans 1;
BA_REL_ "GenSigSuprvResp" BU_SG_REL_ RadioHead_LS SG_ 2152112128 PMVSS_Trans 1;
BA_REL_ "GenSigSuprvResp" BU_SG_REL_ CSM_LS SG_ 2152112128 PMVSS_Eng 1;
BA_REL_ "GenSigSuprvResp" BU_SG_REL_ RadioHead_LS SG_ 2152112128 PMVSS_Eng 1;
BA_REL_ "GenSigSuprvResp" BU_SG_REL_ CSM_LS SG_ 2152112128 PMVSS_Snd 1;
BA_REL_ "GenSigSuprvResp" BU_SG_REL_ RadioHead_LS SG_ 2152112128 PMVSS_Snd 1;
BA_REL_ "GenSigSuprvResp" BU_SG_REL_ CSM_LS SG_ 2152112128 PerfMdMainMenuType 1;
BA_REL_ "GenSigSuprvResp" BU_SG_REL_ RadioHead_LS SG_ 2152112128 PerfMdMainMenuType 1;
VAL_ 2152046592 RmClmCtrlHMIActIndReq 1 "Active" 0 "Inactive" ;
VAL_ 2152046592 RmClmCtrlSyncSetReq 2 "Dual Zone Climate Control" 1 "Single Zone Climate Control" 0 "No Action" ;
VAL_ 2152046592 RmClmCtrlRrDfgSetReq 2 "Inactive" 1 "Active" 0 "No Action" ;
VAL_ 2152046592 RmClmCtrlRcrcSetReq 4 "Inactive" 3 "Auto Recirculation" 2 "Recirculation" 1 "Fresh" 0 "No Action" ;
VAL_ 2152046592 RmClmCtrlClmModSetReq 8 "Comfort Heat" 7 "Comfort AC" 6 "Battery AC On" 5 "Auto" 4 "Active" 3 "Fan Only" 2 "Economy" 1 "Comfort" 0 "No Action" ;
VAL_ 2152046592 RmClmCtrlACSetReq 6 "Battery AC On" 5 "ECO AC on" 4 "Comfort AC On" 3 "Auto AC On" 2 "Active" 1 "Inactive" 0 "No Action" ;
VAL_ 2152046592 RmClmCtrlFLAirDtStReq 15 "E TRI LEVEL" 14 "E PANEL" 13 "E DEFOG" 12 "E DEDFROST" 11 "TRI LEVEL" 10 "DEFOG" 9 "ECO" 8 "PURGE" 7 "AC" 6 "BI LEVEL" 5 "HEATER DEFROST" 4 "HEATER" 3 "DEFROST" 2 "AUTO" 1 "OFF" 0 "No Action" ;
VAL_ 2152046592 RmClmCtrlFrntFanStReq 20 "AUTO" 19 "MAN 18" 18 "MAN 17" 17 "MAN 16" 16 "MAN 15" 15 "MAN 14" 14 "MAN 13" 13 "MAN 12" 12 "MAN 11" 11 "MAN 10" 10 "MAN 9" 9 "MAN 8" 8 "MAN 7" 7 "MAN 6" 6 "MAN 5" 5 "MAN 4" 4 "MAN 3" 3 "MAN 2" 2 "MAN 1" 1 "OFF" 0 "No Action" ;
VAL_ 2152046592 RmClmCtrlRtSTempStReq 38 "14 CELCIUS" 37 "14.5 CELCIUS" 36 "15 CELCIUS" 35 "15.5 CELCIUS" 34 "16 CELCIUS" 33 "HI" 32 "LO" 31 "31.5 CELCIUS" 30 "31 CELCIUS" 29 "30.5 CELCIUS" 28 "30 CELCIUS" 27 "29.5 CELCIUS" 26 "29 CELCIUS" 25 "28.5 CELCIUS" 24 "28 CELCIUS" 23 "27.5 CELCIUS" 22 "27 CELCIUS" 21 "26.5 CELCIUS" 20 "26 CELCIUS" 19 "25.5 CELCIUS" 18 "25 CELCIUS" 17 "24.5 CELCIUS" 16 "24 CELCIUS" 15 "23.5 CELCIUS" 14 "23 CELCIUS" 13 "22.5 CELCIUS" 12 "22 CELCIUS" 11 "21.5 CELCIUS" 10 "21 CELCIUS" 9 "20.5 CELCIUS" 8 "20 CELCIUS" 7 "19.5 CELCIUS" 6 "19 CELCIUS" 5 "18.5 CELCIUS" 4 "18 CELCIUS" 3 "17.5 CELCIUS" 2 "17 CELCIUS" 1 "16.5 CELCIUS" 0 "No Action" ;
VAL_ 2152046592 RmClmCtrlLtSTempStReq 38 "14 CELCIUS" 37 "14.5 CELCIUS" 36 "15 CELCIUS" 35 "15.5 CELCIUS" 34 "16 CELCIUS" 33 "HI" 32 "LO" 31 "31.5 CELCIUS" 30 "31 CELCIUS" 29 "30.5 CELCIUS" 28 "30 CELCIUS" 27 "29.5 CELCIUS" 26 "29 CELCIUS" 25 "28.5 CELCIUS" 24 "28 CELCIUS" 23 "27.5 CELCIUS" 22 "27 CELCIUS" 21 "26.5 CELCIUS" 20 "26 CELCIUS" 19 "25.5 CELCIUS" 18 "25 CELCIUS" 17 "24.5 CELCIUS" 16 "24 CELCIUS" 15 "23.5 CELCIUS" 14 "23 CELCIUS" 13 "22.5 CELCIUS" 12 "22 CELCIUS" 11 "21.5 CELCIUS" 10 "21 CELCIUS" 9 "20.5 CELCIUS" 8 "20 CELCIUS" 7 "19.5 CELCIUS" 6 "19 CELCIUS" 5 "18.5 CELCIUS" 4 "18 CELCIUS" 3 "17.5 CELCIUS" 2 "17 CELCIUS" 1 "16.5 CELCIUS" 0 "No Action" ;
VAL_ 2152030208 TnrFrqBndReq 15 "Unused and Reserved10" 14 "Unused and Reserved9" 13 "Unused and Reserved8" 12 "Unused and Reserved7" 11 "Unused and Reserved6" 10 "Unused and Reserved5" 9 "Unused and Reserved4" 8 "Unused and Reserved3" 7 "Unused and Reserved2" 6 "Unused and Reserved1" 5 "XM" 4 "DAB" 3 "FM" 2 "AM" 1 "Off" 0 "No Action" ;
VAL_ 2150531072 OBHVDCCCpltnTmDspFrmt 3 "Ununsed and Reserved 1" 2 "Display Remaining Minutes To Complete" 1 "Display Completion Time" 0 "No Action" ;
VAL_ 2150531072 ClsHdToStrtVehIO 1 "true" 0 "false" ;
VAL_ 2150531072 HVBChrgOvrdBtnDspStat 2 "Do Not Display Charge Override Button" 1 "Display Charge Override Button" 0 "No Action" ;
VAL_ 2150531072 HVBChrgLmtBtnDspStat 2 "Do Not Disp Charge Limit Button" 1 "Display Charge Limit Button" 0 "No Action" ;
VAL_ 2150531072 HVBHmChrgTmDspStat 4 "Display Master Setting" 3 "Display Both Cord and Station" 2 "Display Charge Station Charge Value" 1 "Display Portable Cord Charge Value" 0 "No Action" ;
VAL_ 2150531072 HVBChrgTmDspStat 3 "Display Both Cord and Station" 2 "Display Charge Station Charge Value" 1 "Display Portable Cord Charge Value" 0 "No Action" ;
VAL_ 2150531072 RegPwrLmtdIO 1 "true" 0 "false" ;
VAL_ 2150531072 RegPwrLmtdDspPrcntVs 1 "true" 0 "false" ;
VAL_ 2151833600 HtdFrntWSDispReq 2 "OFF" 1 "ON" 0 "No Action" ;
VAL_ 2151833600 HtdFrntWSCustRqIhbt 1 "true" 0 "false" ;
VAL_ 2151817216 HtdFrntWSCustRq 1 "true" 0 "false" ;
VAL_ 2151849984 AutoThrmlStPassMdStRq 3 "Vent Cool" 2 "Back Only Heat" 1 "Seat Heat" 0 "OFF" ;
VAL_ 2151849984 AutoThrmlStDrvMdStRq 3 "Vent Cool" 2 "Back Only Heat" 1 "Seat Heat" 0 "OFF" ;
VAL_ 2151849984 AutoThrmlStPasLvlStRq 5 "Level 5" 4 "Level 4" 3 "Level 3" 2 "Level 2" 1 "Level 1" 0 "OFF" ;
VAL_ 2151849984 AutoThrmlStDrvLvStRq 5 "Level 5" 4 "Level 4" 3 "Level 3" 2 "Level 2" 1 "Level 1" 0 "OFF" ;
VAL_ 2153897984 RunBrdExtdFtrAvail 1 "true" 0 "false" ;
VAL_ 2153897984 RunBrdOpMdCstCurrStVal 7 "Unused and Reserved 4" 6 "Unused and Reserved 3" 5 "Unused and Reserved 2" 4 "Unused and Reserved 1" 3 "Extended" 2 "On" 1 "Off" 0 "No Action" ;
VAL_ 2153897984 RunBrdOpMdCstStAvail 1 "true" 0 "false" ;
VAL_ 2151702528 LnMrkngIndRgt 3 "Unused and Reserved 1" 2 "Green Indicator" 1 "White Indicator" 0 "Indicator Off" ;
VAL_ 2151702528 LnMrkngIndLft 3 "Unused and Reserved 1" 2 "Green Indicator" 1 "White Indicator" 0 "Indicator Off" ;
VAL_ 2151702528 LnKepAsstStIndRgt 7 "Unused and Reserved 2" 6 "Unused and Reserved 1" 5 "Yellow Indicator" 4 "Red Indicator" 3 "Blue Indicator" 2 "Green Indicator" 1 "White Indicator" 0 "Indicator Off" ;
VAL_ 2151702528 LnKepAsstStIndLft 7 "Unused and Reserved 2" 6 "Unused and Reserved 1" 5 "Yellow Indicator" 4 "Red Indicator" 3 "Blue Indicator" 2 "Green Indicator" 1 "White Indicator" 0 "Indicator Off" ;
VAL_ 2151702528 LnKpngAstRecfblIndRq 7 "Unused and Reserved 2" 6 "Unused and Reserved 1" 5 "Yellow Solid Indicator" 4 "Yellow Flashing Indicator" 3 "Blue Solid Indicator" 2 "Green Solid Indicator" 1 "White Solid Indicator" 0 "Indicator Off" ;
VAL_ 2154618880 ClmCntPrtyHtRqV 1 "Invalid" 0 "Valid" ;
VAL_ 2154618880 ClmCntPrtyHtRq 3 "HIGH" 2 "MEDIUM" 1 "LOW" 0 "NO ACTION" ;
VAL_ 2154618880 ClmCntCalcTrgtCbnHtLdV 1 "Invalid" 0 "Valid" ;
VAL_ 2154618880 ClmCntMinTrgtClntTmpV 1 "Invalid" 0 "Valid" ;
VAL_ 2154618880 ClmCntHtrMinFlwRtRqV 1 "Invalid" 0 "Valid" ;
VAL_ 2150236160 UlckKyStrCrptoDt2M 1 "Use Data" 0 "Dont Use Data" ;
VAL_ 2150170624 UlckKyStrCrptoDt1M 1 "Use Data" 0 "Dont Use Data" ;
VAL_ 2155126784 DrvrSetRrwrdMvmnt 7 "Supervised Seat Recline Rearward" 6 "Supervised Seat Rear Down" 5 "Supervised Seat Rearward" 4 "Button Memory 1 and 2 EXIT Recall" 3 "Supervised Memory Recall" 2 "Auto Easy Exit Recall" 1 "Auto Recall At Ignition On" 0 "No Auto Or Rearward Movement" ;
VAL_ 2154725376 AuxHtrAtv378 1 "true" 0 "false" ;
VAL_ 2154725376 AuxHtrRq 1 "On" 0 "Off" ;
VAL_ 2157051904 WSMR_WiFiAssnReq 3 "Unexpected Undefined Connection Behavior" 2 "Wi Fi association failed with available credentials" 1 "Failed to receive Wi Fi credentials after 255 attempts" 0 "SSID and Passphrase Request" ;
VAL_ 2156994560 WAPDM_SecurityType 3 "WPA2 (WiFi Protected Access 2)" 4 "IEEE802.1X (Institute of Electrical and Electronics Engineers)" 0 "Open" 1 "WEP (Wired Equivalent Privacy)" 2 "WPA (WiFi Protected Access)" ;
VAL_ 2156994560 WAPDM_WiFiEnStat 0 "Disabled" 1 "Enabled" ;
VAL_ 2156994560 WAPDM_EncrptnType 0 "Open" 1 "AES (Advanced Encryption Standard)" 2 "TKIP (Temporal Key Integrity Protocol)" 3 "AES or TKIP" ;
VAL_ 2158133248 ChrgCmpltFstChgingAct 1 "true" 0 "false" ;
VAL_ 2158133248 TrgtChrgLvlAct 1 "true" 0 "false" ;
VAL_ 2158133248 HTRCsStAvail 1 "true" 0 "false" ;
VAL_ 2158133248 HTRCsCrStVal 4 "On Away" 3 "On Home" 2 "On" 1 "Off" 0 "No Action" ;
VAL_ 2158133248 HTRCA_Res3Avail 1 "true" 0 "false" ;
VAL_ 2158133248 HTRCA_Res2Avail 1 "true" 0 "false" ;
VAL_ 2158133248 HTRCA_Res1Avail 1 "true" 0 "false" ;
VAL_ 2158133248 HTRCA_OnAwAvail 1 "true" 0 "false" ;
VAL_ 2158133248 HTRCA_OnHmAvail 1 "true" 0 "false" ;
VAL_ 2158133248 HTRCA_OnAvail 1 "true" 0 "false" ;
VAL_ 2158133248 HTRCA_OffAvail 1 "true" 0 "false" ;
VAL_ 2154651648 TAC_AudConctOutcm 15 "Unused And Reserved 13" 14 "Unused And Reserved 12" 13 "Unused And Reserved 11" 12 "Unused And Reserved 10" 11 "Unused And Reserved 9" 10 "Unused And Reserved 8" 9 "Unused And Reserved 7" 8 "Unused And Reserved 6" 7 "Unused And Reserved 5" 6 "Unused And Reserved 4" 5 "Unused And Reserved 3" 4 "Unused And Reserved 2" 3 "Unused And Reserved 1" 2 "Request Denied" 1 "Request Granted" 0 "No Action" ;
VAL_ 2154651648 TAC_AudChConctStat 15 "Unused And Reserved 10" 14 "Unused And Reserved 9" 13 "Unused And Reserved 8" 12 "Unused And Reserved 7" 11 "Unused And Reserved 6" 10 "Unused And Reserved 5" 9 "Unused And Reserved 4" 8 "Unused And Reserved 3" 7 "Unused And Reserved 2" 6 "Unused And Reserved 1" 5 "Emergency Phone" 4 "Phone" 3 "Ring Tone" 2 "Mutex Prompt" 1 "Mix Prompt" 0 "No Action" ;
VAL_ 2154635264 TAR_AudSrcStat 15 "Unused And Reserved 11" 14 "Unused And Reserved 10" 13 "Unused And Reserved 9" 12 "Unused And Reserved 8" 11 "Unused And Reserved 7" 10 "Unused And Reserved 6" 9 "Unused And Reserved 5" 8 "Unused And Reserved 4" 7 "Unused And Reserved 3" 6 "Unused And Reserved 2" 5 "Unused And Reserved 1" 4 "Audio Disconnect" 3 "Audio Request" 2 "Audio Playing" 1 "Audio Ready" 0 "No Action" ;
VAL_ 2154635264 TAR_AudConctReq 13 "Unused And Reserved 8" 12 "Unused And Reserved 7" 11 "Unused And Reserved 6" 10 "Unused And Reserved 5" 9 "Unused And Reserved 4" 8 "Unused And Reserved 3" 7 "Unused And Reserved 2" 6 "Unused And Reserved 1" 5 "Emergency Phone" 4 "Phone" 3 "Ring Tone" 2 "Mutex Prompt" 1 "Mix Prompt" 0 "No Action" 15 "Unused And Reserved 10" 14 "Unused And Reserved 9" ;
VAL_ 2152529920 LVMAVC_SpchRcgnAval 3 "Unused and Reserved 2" 2 "Unused and Reserved 1" 1 "Available" 0 "No Action" ;
VAL_ 2152529920 LVMAVC_RemSpchRcgnActn 3 "End Button Press" 2 "PTT Button Press" 1 "Activate LVM_SR" 0 "No Action" ;
VAL_ 2152529920 LVMAVC_RemSpchRcgnID 7 "Unused and Reserved 4" 6 "Unused and Reserved 3" 5 "Unused and Reserved 2" 4 "Unused and Reserved 1" 3 "LVM PDR" 2 "LVM DMB" 1 "LVM NAV" 0 "No Action" ;
VAL_ 2152529920 LVMAVC_StreoAudRsp 3 "Unused and Reserved 2" 2 "Unused and Reserved 1" 1 "Active" 0 "No Action" ;
VAL_ 2152529920 LVMAVC_PrmtAudRsp 3 "Unused and Reserved 2" 2 "Unused and Reserved 1" 1 "Active" 0 "No Action" ;
VAL_ 2152529920 LVMAVC_RemtEnbl 7 "Unused and Reserved 5" 6 "Unused and Reserved 4" 5 "Unused and Reserved 3" 4 "Unused and Reserved 2" 3 "Unused and Reserved 1" 2 "Remote Enable Active" 1 "Remote Enable On" 0 "No Action" ;
VAL_ 2152513536 LVMAVR_SpchRcgnAct 3 "Unused and Reserved 1" 2 "LVM Speech Rec Active" 1 "LVM Speech Rec Ready" 0 "No Action" ;
VAL_ 2152513536 LVMAVR_PrmtAudReq 3 "Unused and Reserved 2" 2 "Unused and Reserved 1" 1 "Prompt Request" 0 "No Action" ;
VAL_ 2152513536 LVMAVR_StreoAudReq 3 "Unused and Reserved 2" 2 "Unused and Reserved 1" 1 "Stereo Request" 0 "No Action" ;
VAL_ 2152513536 LVMAVR_DispReq 7 "Unused and Reserved 4" 6 "Unused and Reserved 3" 5 "Unused and Reserved 2" 4 "Unused and Reserved 1" 3 "LVM PDR" 2 "LVM DMB" 1 "LVM NAV" 0 "No Action" ;
VAL_ 2154889216 RSIHMIAnmReq 7 "Unused and Reserved 3" 6 "Unused and Reserved 2" 5 "Unused and Reserved 1" 4 "Shutdown Play" 3 "Start Play" 2 "Welcome Play" 1 "Ready" 0 "Uninitialized" ;
VAL_ 2154889216 ClstrHMIAnmReq 7 "Unused and Reserved 3" 6 "Unused and Reserved 2" 5 "Unused and Reserved 1" 4 "Shutdown Play" 3 "Start Play" 2 "Welcome Play" 1 "Ready" 0 "No Action" ;
VAL_ 2154872832 RmRflshUpdtAvail 1 "true" 0 "false" ;
VAL_ 2154872832 InfoActvnReq 1 "true" 0 "false" ;
VAL_ 2154569728 InfotnmntSysSt 31 " Unused and Reserved 15" 30 " Unused and Reserved 14" 29 " Unused and Reserved 13" 28 " Unused and Reserved 12" 27 " Unused and Reserved 11" 26 " Unused and Reserved 10" 25 " Unused and Reserved 9" 24 " Unused and Reserved 8" 23 " Unused and Reserved 7" 22 " Unused and Reserved 6" 21 " Unused and Reserved 5" 20 " Unused and Reserved 4" 19 " Unused and Reserved 3" 18 " Unused and Reserved 2" 17 " Unused and Reserved 1" 16 " Remote Reflash Programming" 15 " No VIN" 14 " No Calibration" 13 " Theftlocked" 12 " Valet Mode" 11 " Local Eject" 10 " Local Valet" 9 " Local Phone" 8 " Local Infotainment" 7 " Accessory" 6 " Propulsion" 5 " Run" 4 " Start" 3 " HMI Inactive" 2 " HMI Init" 1 " Animation Init" 0 " Sleep" ;
VAL_ 2151931904 FourWhlDrvIdReqExtRng 15 "Front Wheel Drive Mode Active" 14 "Front Wheel Drive Mode Pending" 13 "AWD Connected Mode Active" 12 "AWD Connected Mode Pending" 11 "Position Undetermined Active" 10 "Transfer Case Neutral Active" 9 "Transfer Case Neutral Pending" 8 "Four Wheel Drive Low Lock Active" 7 "Four Wheel Drive Low Lock Pending" 6 "Four Wheel Drive High Lock Active" 5 "Four Wheel Drive High Lock Pending" 4 "Four Wheel Drive High Auto Active" 3 "Four Wheel Drive High Auto Pending" 2 "Two Wheel Drive High Active" 1 "Two Wheel Drive High Pending" 0 "No Indication" ;
VAL_ 2151931904 FuelMdTrnstnIndReq 15 "Unused and Reserved 9" 14 "Unused and Reserved 8" 13 "Unused and Reserved 7" 12 "Unused and Reserved 6" 11 "Unused and Reserved 5" 10 "Unused and Reserved 4" 9 "Unused and Reserved 3" 8 "Unused and Reserved 2" 7 "Unused and Reserved 1" 6 "Indication 6" 5 "Indication 5" 4 "Indication 4" 3 "Indication 3" 2 "Indication 2" 1 "Indication 1" 0 "No Indication" ;
VAL_ 2151931904 BiFuelRflGaslinIndReq 7 "Unused and Reserved 5" 6 "Unused and Reserved 4" 5 "Unused and Reserved 3" 4 "Unused and Reserved 2" 3 "Unused and Reserved 1" 2 "Indication 2" 1 "Indication 1" 0 "No Indication" ;
VAL_ 2151931904 AutoShtdwnIO 1 "true" 0 "false" ;
VAL_ 2151931904 TCSTempDsblReqIO 1 "true" 0 "false" ;
VAL_ 2151931904 VehStbCmptvMdCstAvl 1 "true" 0 "false" ;
VAL_ 2151931904 VehStbEnmntCstAvl 1 "true" 0 "false" ;
VAL_ 2151931904 TCSysCstAvl 1 "true" 0 "false" ;
VAL_ 2151931904 VehStbCmptvMdCurSt 1 "On" 0 "Off" ;
VAL_ 2151931904 VehStbEnhmntCurSt 1 "On" 0 "Off" ;
VAL_ 2151931904 TCSysCurSt 1 "On" 0 "Off" ;
VAL_ 2151931904 TracAndStbScrnCnfg 3 "TCS ESC and Comp" 2 "TCS and ESC" 1 "TCS Only" 0 "None" ;
VAL_ 2151931904 ElctShfPriLtdPerfMdIO 1 "true" 0 "false" ;
VAL_ 2151931904 LnchCtrlWhlSlpStat 31 "Unused and Reserved 10" 30 "Unused and Reserved 9" 29 "Unused and Reserved 8" 28 "Unused and Reserved 7" 27 "Unused and Reserved 6" 26 "Unused and Reserved 5" 25 "Unused and Reserved 4" 24 "Unused and Reserved 3" 23 "Unused and Reserved 2" 22 "Unused and Reserved 1" 21 "Fifteen Percent" 20 "Fourteen And A Half Percent" 19 "Fourteen Percent" 18 "Thirteen And A Half Percent" 17 "Thirteen Percent" 16 "Twelve And A Half Percent" 15 "Twelve Percent" 14 "Eleven And a Half Percent" 13 "Eleven Percent" 12 "Ten And A Half Percent" 11 "Ten Percent" 10 "Nine And A Half Percent" 9 "Nine Percent" 8 "Eight And A Half Percent" 7 "Eight Percent" 6 "Seven And A Half Percent" 5 "Seven Percent" 4 "Six And A Half Percent" 3 "Six Percent" 2 "Five And A Half Percent" 1 "Five Percent" 0 "No Action" ;
VAL_ 2151931904 LnchCtrlMdStat 7 "Line Lock Release Brake" 6 "Line Lock Press Brake" 5 "Burn Out Or Line Lock" 4 "High Traction Custom" 3 "High Traction" 2 "General Custom" 1 "General" 0 "Disable" ;
VAL_ 2151931904 LnchCtrlEngRPMStat 0 "No Action" 63 "Unused and Reserved 30" 62 "Unused and Reserved 29" 61 "Unused and Reserved 28" 60 "Unused and Reserved 27" 59 "Unused and Reserved 26" 58 "Unused and Reserved 25" 57 "Unused and Reserved 24" 56 "Unused and Reserved 23" 55 "Unused and Reserved 22" 54 "Unused and Reserved 21" 53 "Unused and Reserved 20" 52 "Unused and Reserved 19" 51 "Unused and Reserved 18" 50 "Unused and Reserved 17" 49 "Unused and Reserved 16" 48 "Unused and Reserved 15" 47 "Unused and Reserved 14" 46 "Unused and Reserved 13" 45 "Unused and Reserved 12" 44 "Unused and Reserved 11" 43 "Unused and Reserved 10" 42 "Unused and Reserved 9" 41 "Unused and Reserved 8" 40 "Unused and Reserved 7" 39 "Unused and Reserved 6" 38 "Unused and Reserved 5" 37 "Unused and Reserved 4" 36 "Unused and Reserved 3" 35 "Unused and Reserved 2" 34 "Unused and Reserved 1" 33 "4000" 32 "3900" 31 "3800" 30 "3700" 29 "3600" 28 "3500" 27 "3400" 26 "3300" 25 "3200" 24 "3100" 23 "3000" 22 "2900" 21 "2800" 20 "2700" 19 "2600" 18 "2500" 17 "2400" 16 "2300" 15 "2200" 14 "2100" 13 "2000" 12 "1900" 11 "1800" 10 "1700" 9 "1600" 8 "1500" 7 "1400" 6 "1300" 5 "1200" 4 "1100" 3 "1000" 2 "900" 1 "800" ;
VAL_ 2151931904 RegVltCtlEngyRcvryAct 1 "true" 0 "false" ;
VAL_ 2151931904 VehSpdCntlSystmType 2 "Adaptive Cruise Control" 1 "Conventional Cruise Control" 0 "No Vehicle Speed Control" ;
VAL_ 2151931904 ACCSysSltdMdDispIO 1 "true" 0 "false" ;
VAL_ 2151931904 ACCSysSltdMd 3 "Unused And Reserved" 2 "Enhanced Cruise Control" 1 "Adaptive Cruise Control" 0 "Cruise Control Mode Switching Not Supported" ;
VAL_ 2151931904 PTExPrtclFltWrng3IO 1 "true" 0 "false" ;
VAL_ 2151931904 PTExPartFltManRegStat 7 "Do not press pedals" 6 "Not available" 5 "Pending Driver Input" 4 "Complete" 3 "In Progress" 2 "Not Allowed" 1 "Allowed" 0 "Cleaning Not Required" ;
VAL_ 2151931904 AWDRecmndIO 1 "true" 0 "false" ;
VAL_ 2151686144 RrCmrDeplmntReqtsd 1 "true" 0 "false" ;
VAL_ 2151686144 NoSDCrdPrIO 1 "true" 0 "false" ;
VAL_ 2151686144 SDCrdFullIO 1 "true" 0 "false" ;
VAL_ 2151686144 SDCrdErrIO 1 "true" 0 "false" ;
VAL_ 2155028480 RgtLnChgThrt 1 "true" 0 "false" ;
VAL_ 2151915520 ESPTrnVehOffFrPrkIO 1 "true" 0 "false" ;
VAL_ 2151915520 ESPTrnsCtlrMalfIO 1 "true" 0 "false" ;
VAL_ 2151915520 ESPShfToDrvTryAgnIO 1 "true" 0 "false" ;
VAL_ 2151915520 ElcShfPriTwoGrsSlInRq 3 "Drive Indication" 2 "Neutral Indication" 1 "Park Indication" 0 "No Indication" ;
VAL_ 2151915520 ESPRedSpdReqShftIO 1 "true" 0 "false" ;
VAL_ 2151915520 EngIntkArBstPrExtRngV 1 "Invalid" 0 "Valid" ;
VAL_ 2151915520 ElecShfRngDisp 15 "Unused and Reserved 3" 14 "Unused and Reserved 2" 13 "Unused and Reserved 1" 12 "Park Requested And Denied" 11 "Drive Requested And In Progress" 10 "Neutral Requested And In Progress" 9 "Reverse Requested And In Progress" 8 "Park Requested And In Progress" 7 "Reserved" 6 "Manual Nominal" 5 "Low Nominal" 4 "Drive Nominal" 3 "Neutral Nominal" 2 "Reverse Nominal" 1 "Park Nominal" 0 "No Display " ;
VAL_ 2151915520 ESPTransMalfIO 1 "true" 0 "false" ;
VAL_ 2151915520 ESPRngInvldReqIO 1 "true" 0 "false" ;
VAL_ 2151915520 ESPPrkInvldReqIO 1 "true" 0 "false" ;
VAL_ 2151915520 ESPHldShfLvrToEngRgIO 1 "true" 0 "false" ;
VAL_ 2151915520 ESPDrvrPrkIlkSftAtdIO 1 "true" 0 "false" ;
VAL_ 2151915520 ESPDrvrIlkShfAtdIO 1 "true" 0 "false" ;
VAL_ 2151915520 AHAct 1 "true" 0 "false" ;
VAL_ 2151915520 AHEnbld 1 "true" 0 "false" ;
VAL_ 2151915520 ShfToPrkBfExtngIO 1 "true" 0 "false" ;
VAL_ 2151915520 AHServcIO 1 "true" 0 "false" ;
VAL_ 2151915520 AHAppBrkPedlIO 1 "true" 0 "false" ;
VAL_ 2151915520 AHDisbldStbltIO 1 "true" 0 "false" ;
VAL_ 2151915520 AHDisbldDrOpnIO 1 "true" 0 "false" ;
VAL_ 2151915520 ElcTransRngSlctVDA 1 "Virtual Device Available" 0 "Virtual Device Unavailable" ;
VAL_ 2150129664 HtVwAutnmsEPBAplyReqd 1 "true" 0 "false" ;
VAL_ 2154299392 CrShrngVehChlngReq 1 "Request New  Challenge" 0 "No Action" ;
VAL_ 2154397696 CrShrngRvkCertfctRsp 4 "No CertIDs Stored" 3 "CertID Not Matched" 2 "Revoke Certificate Successful" 1 "Write Failure" 0 "No Action" ;
VAL_ 2154397696 CrShrngConnStat 3 "Terminate Connection" 2 "Ignore Connection" 1 "Valid Connection" 0 "No Action" ;
VAL_ 2154397696 CrShrngFbsEnblStat 3 "Fail" 2 "Enabled" 1 "Disabled" 0 "No Action" ;
VAL_ 2154397696 CSPS_ConnStat 15 "Reject All Certificates" 14 "Incorrect Fleet ID" 13 "Send Intermediate Certificate" 12 "Send User Certificate" 11 "Send all Authentication Data" 10 "Invalid VIN" 9 "Intermediate Certificate Expired" 8 "Invalid Intermediate Certificate" 7 "Resrvation End Time Exceeded " 6 "Resrvtion Start Tim Not Achieved" 5 "Cert Revoked Via Mobile Device" 4 "Cert Revoked Via Telematics" 3 "Certificate Expired" 2 "Invalid Certificate" 1 "Valid Certificate" 0 "No Action" ;
VAL_ 2154397696 CSPS_RspVerf 4 "Command Response Verification Not Successful" 3 "Command Response Verification Successful" 2 "Zone Response Verification Not Successful" 1 "Zone Response Verification Successful" 0 "No Action" ;
VAL_ 2154381312 CSZS_FrntCmptZnMbDevStat 1 "One Or More Mobile Devices Prsnt" 0 "No Mobile Device Present" ;
VAL_ 2154381312 CSZS_RrCmptZnMbDevStat 1 "One Or More Mobile Devices Prsnt" 0 "No Mobile Device Present" ;
VAL_ 2154381312 CSZS_FrntExtrZnMbDevStat 1 "One Or More Mobile Devices Prsnt" 0 "No Mobile Device Present" ;
VAL_ 2154381312 CSZS_RrExtrZnMbDevStat 1 "One Or More Mobile Devices Prsnt" 0 "No Mobile Device Present" ;
VAL_ 2154381312 CSZS_WlcmZnMbDevStat 1 "One Or More Mobile Devices Prsnt" 0 "No Mobile Device Present" ;
VAL_ 2154381312 CSZS_IntrZnMbDevStat 3 "Three Mobile Devices Present" 2 "Two Mobile Devices Present" 1 "One Mobile Device Present" 0 "No Mobile Device Present" ;
VAL_ 2154381312 CSZS_PassEntyZnMbDevStat 1 "One Or More Mobile Devices Prsnt" 0 "No Mobile Device Present" ;
VAL_ 2154381312 CSZS_DrEntyZnMbDevStat 1 "One Or More Mobile Devices Prsnt" 0 "No Mobile Device Present" ;
VAL_ 2152153088 RRSCDS_DispReq 1 "true" 0 "false" ;
VAL_ 2152153088 RRSCDS_DispSz 2 "Small Size" 1 "Medium Size" 0 "Full Size" ;
VAL_ 2152153088 RRSCDS_CshLgAdjFdRr 3 "Rearward" 2 "Forward" 1 "Selected - No Movement " 0 "Not Selected" ;
VAL_ 2152153088 RRSCDS_BkCshBlstInOt 5 "Cushion Bolster Out" 4 "Cushion Bolster In" 3 "Back Bolster Out" 2 "Back Bolster In" 1 "Selected - No Movement" 0 "Not Selected" ;
VAL_ 2152153088 RRSCDS_CshBlstrInOut 3 "Out" 2 "In" 1 "Selected - No Movement" 0 "Not Selected" ;
VAL_ 2152153088 RRSCDS_BkBlstrInOut 3 "Out" 2 "In" 1 "Selected - No Movement" 0 "Not Selected" ;
VAL_ 2152153088 RRSCDS_LmbrUDnFdRr 5 "Rearward" 4 "Forward" 3 "Down" 2 "Up" 1 "Selected - No Movement " 0 "Not Selected" ;
VAL_ 2152153088 RRSCDS_LmbrFwdRr 3 "Rearward" 2 "Forward" 1 "Selected - No Movement " 0 "Not Selected" ;
VAL_ 2152153088 RRSCDS_LmbrUpDwn 3 "Down" 2 "Up" 1 "Selected - No Movement" 0 "Not Selected" ;
VAL_ 2152153088 RRSCDS_UprShldrFdRr 3 "Rearward" 2 "Forward" 1 "Selected - No Movement " 0 "Not Selected" ;
VAL_ 2152153088 RRSCDS_HdrstTltFwdRr 3 "Rearward" 2 "Forward" 1 "Selected - No Movement " 0 "Not Selected" ;
VAL_ 2152153088 RRSCDS_HdrstWngInOt 3 "Out" 2 "In" 1 "Selected - No Movement" 0 "Not Selected" ;
VAL_ 2152153088 RRSCDS_HdrstFdRrUDn 5 "Rearward" 4 "Forward" 3 "Down" 2 "Up" 1 "Selected - No Movement " 0 "Not Selected" ;
VAL_ 2152153088 RRSCDS_HdrstFwdRrwd 3 "Rearward" 2 "Forward" 1 "Selected - No Movement " 0 "Not Selected" ;
VAL_ 2152153088 RRSCDS_HdrstUpDn 3 "Down" 2 "Up" 1 "Selected - No Movement" 0 "Not Selected" ;
VAL_ 2152153088 RRSCDS_MassgIntsty 7 "Massage Intensity 7" 6 "Massage Intensity 6" 5 "Massage Intensity 5" 4 "Massage Intensity 4" 3 "Massage Intensity 3" 2 "Massage Intensity 2" 1 "Massage Intensity 1" 0 "Massage Off" ;
VAL_ 2152153088 RRSCDS_MassgTyp 15 "Massage Type 15" 14 "Massage Type 14" 13 "Massage Type 13" 12 "Massage Type 12" 11 "Massage Type 11" 10 "Massage Type 10" 9 "Massage Type 9" 8 "Massage Type 8" 7 "Massage Type 7" 6 "Massage Type 6" 5 "Massage Type 5" 4 "Massage Type 4" 3 "Massage Type 3" 2 "Massage Type 2" 1 "Massage Type 1" 0 "Massage Off" ;
VAL_ 2152153088 RRSCDS_Massg 2 "Selected Massage On" 1 "Selected Massage Off" 0 "Not Selected" ;
VAL_ 2152136704 RRSMP_UnsdRsrvd 1 "true" 0 "false" ;
VAL_ 2152103936 LRSCDS_DispReq 1 "true" 0 "false" ;
VAL_ 2152103936 LRSCDS_DispSz 2 "Small Size" 1 "Medium Size" 0 "Full Size" ;
VAL_ 2152103936 LRSCDS_CshLgAdjFdRr 3 "Rearward" 2 "Forward" 1 "Selected - No Movement " 0 "Not Selected" ;
VAL_ 2152103936 LRSCDS_BkCshBlstInOt 5 "Cushion Bolster Out" 4 "Cushion Bolster In" 3 "Back Bolster Out" 2 "Back Bolster In" 1 "Selected - No Movement" 0 "Not Selected" ;
VAL_ 2152103936 LRSCDS_CshBlstrInOut 3 "Out" 2 "In" 1 "Selected - No Movement" 0 "Not Selected" ;
VAL_ 2152103936 LRSCDS_BkBlstrInOut 3 "Out" 2 "In" 1 "Selected - No Movement" 0 "Not Selected" ;
VAL_ 2152103936 LRSCDS_LmbrUDnFdRr 5 "Rearward" 4 "Forward" 3 "Down" 2 "Up" 1 "Selected - No Movement " 0 "Not Selected" ;
VAL_ 2152103936 LRSCDS_LmbrFwdRr 3 "Rearward" 2 "Forward" 1 "Selected - No Movement " 0 "Not Selected" ;
VAL_ 2152103936 LRSCDS_LmbrUpDwn 3 "Down" 2 "Up" 1 "Selected - No Movement" 0 "Not Selected" ;
VAL_ 2152103936 LRSCDS_UprShldrFdRr 3 "Rearward" 2 "Forward" 1 "Selected - No Movement " 0 "Not Selected" ;
VAL_ 2152103936 LRSCDS_HdrstTltFwdRr 3 "Rearward" 2 "Forward" 1 "Selected - No Movement " 0 "Not Selected" ;
VAL_ 2152103936 LRSCDS_HdrstWngInOt 3 "Out" 2 "In" 1 "Selected - No Movement" 0 "Not Selected" ;
VAL_ 2152103936 LRSCDS_HdrstFdRrUDn 5 "Rearward" 4 "Forward" 3 "Down" 2 "Up" 1 "Selected - No Movement " 0 "Not Selected" ;
VAL_ 2152103936 LRSCDS_HdrstFwdRrwd 3 "Rearward" 2 "Forward" 1 "Selected - No Movement " 0 "Not Selected" ;
VAL_ 2152103936 LRSCDS_HdrstUpDn 3 "Down" 2 "Up" 1 "Selected - No Movement" 0 "Not Selected" ;
VAL_ 2152103936 LRSCDS_MassgIntsty 7 "Massage Intensity 7" 6 "Massage Intensity 6" 5 "Massage Intensity 5" 4 "Massage Intensity 4" 3 "Massage Intensity 3" 2 "Massage Intensity 2" 1 "Massage Intensity 1" 0 "Massage Off" ;
VAL_ 2152103936 LRSCDS_MassgTyp 15 "Massage Type 15" 14 "Massage Type 14" 13 "Massage Type 13" 12 "Massage Type 12" 11 "Massage Type 11" 10 "Massage Type 10" 9 "Massage Type 9" 8 "Massage Type 8" 7 "Massage Type 7" 6 "Massage Type 6" 5 "Massage Type 5" 4 "Massage Type 4" 3 "Massage Type 3" 2 "Massage Type 2" 1 "Massage Type 1" 0 "Massage Off" ;
VAL_ 2152103936 LRSCDS_Massg 2 "Selected Massage On" 1 "Selected Massage Off" 0 "Not Selected" ;
VAL_ 2152087552 LRSMP_UnsdRsrvd 1 "true" 0 "false" ;
VAL_ 2153947136 RmtRflshMdAct 1 "true" 0 "false" ;
VAL_ 2152628224 OBTCR_Stat 3 "Revoked" 2 "Denied" 1 "Accepted" 0 "No Action" ;
VAL_ 2152628224 OBTCMstrStat 3 "Off Board Tester Present" 2 "Active" 1 "Inactive" 0 "Unknown" ;
VAL_ 2152112128 PMVSS_Disps 7 "Visualization Type 7" 6 "Visualization Type 6" 5 "Visualization Type 5" 4 "Visualization Type 4" 3 "Visualization Type 3" 2 "Visualization Type 2" 1 "Visualization Type 1" 0 "No Action" ;
VAL_ 2152112128 PMVSS_Exhst 7 "Visualization Type 7" 6 "Visualization Type 6" 5 "Visualization Type 5" 4 "Visualization Type 4" 3 "Visualization Type 3" 2 "Visualization Type 2" 1 "Visualization Type 1" 0 "No Action" ;
VAL_ 2152112128 PMVSS_PsngrSeat 7 "Visualization Type 7" 6 "Visualization Type 6" 5 "Visualization Type 5" 4 "Visualization Type 4" 3 "Visualization Type 3" 2 "Visualization Type 2" 1 "Visualization Type 1" 0 "No Action" ;
VAL_ 2152112128 PMVSS_DrvrSeat 7 "Visualization Type 7" 6 "Visualization Type 6" 5 "Visualization Type 5" 4 "Visualization Type 4" 3 "Visualization Type 3" 2 "Visualization Type 2" 1 "Visualization Type 1" 0 "No Action" ;
VAL_ 2152112128 PMVSS_AdptCrsCnt 7 "Visualization Type 7" 6 "Visualization Type 6" 5 "Visualization Type 5" 4 "Visualization Type 4" 3 "Visualization Type 3" 2 "Visualization Type 2" 1 "Visualization Type 1" 0 "No Action" ;
VAL_ 2152112128 PMVSS_Drvln 7 "Visualization Type 7" 6 "Visualization Type 6" 5 "Visualization Type 5" 4 "Visualization Type 4" 3 "Visualization Type 3" 2 "Visualization Type 2" 1 "Visualization Type 1" 0 "No Action" ;
VAL_ 2152112128 PMVSS_Susp 7 "Visualization Type 7" 6 "Visualization Type 6" 5 "Visualization Type 5" 4 "Visualization Type 4" 3 "Visualization Type 3" 2 "Visualization Type 2" 1 "Visualization Type 1" 0 "No Action" ;
VAL_ 2152112128 PMVSS_Strng 7 "Visualization Type 7" 6 "Visualization Type 6" 5 "Visualization Type 5" 4 "Visualization Type 4" 3 "Visualization Type 3" 2 "Visualization Type 2" 1 "Visualization Type 1" 0 "No Action" ;
VAL_ 2152112128 PMVSS_Trans 7 "Visualization Type 7" 6 "Visualization Type 6" 5 "Visualization Type 5" 4 "Visualization Type 4" 3 "Visualization Type 3" 2 "Visualization Type 2" 1 "Visualization Type 1" 0 "No Action" ;
VAL_ 2152112128 PMVSS_Eng 7 "Visualization Type 7" 6 "Visualization Type 6" 5 "Visualization Type 5" 4 "Visualization Type 4" 3 "Visualization Type 3" 2 "Visualization Type 2" 1 "Visualization Type 1" 0 "No Action" ;
VAL_ 2152112128 PMVSS_Snd 7 "Visualization Type 7" 6 "Visualization Type 6" 5 "Visualization Type 5" 4 "Visualization Type 4" 3 "Visualization Type 3" 2 "Visualization Type 2" 1 "Visualization Type 1" 0 "No Action" ;
VAL_ 2152112128 PerfMdMainMenuType 7 "Reserved" 6 "Reserved" 5 "Reserved" 4 "Reserved" 3 "Main Menu Type 3" 2 "Main Menu Type 2" 1 "Main Menu Type 1" 0 "No Action" ;
SIG_GROUP_ 2157051904 WiFiStatnMpReq 1 : WSMR_WiFiStnMpMACAddr WSMR_WiFiAssnReq;
SIG_GROUP_ 2156994560 WiFiAccsPntData_Mp 1 : WAPDM_SecurityType WAPDM_WiFiEnStat WAPDM_EncrptnType;
SIG_GROUP_ 2158133248 HTRCsAvail 1 : HTRCA_Res3Avail HTRCA_Res2Avail HTRCA_Res1Avail HTRCA_OnAwAvail HTRCA_OnHmAvail HTRCA_OnAvail HTRCA_OffAvail;
SIG_GROUP_ 2154651648 TeleAudCtl 1 : TAC_AudConctOutcm TAC_AudChConctStat;
SIG_GROUP_ 2154635264 TeleAudReq 1 : TAR_AudSrcStat TAR_AudConctReq;
SIG_GROUP_ 2152529920 LowVolModAudVidCmd 1 : LVMAVC_SpchRcgnAval LVMAVC_RemSpchRcgnActn LVMAVC_RemSpchRcgnID LVMAVC_StreoAudRsp LVMAVC_PrmtAudRsp LVMAVC_RemtEnbl;
SIG_GROUP_ 2152513536 LowVolModAudVidReq 1 : LVMAVR_SpchRcgnAct LVMAVR_PrmtAudReq LVMAVR_StreoAudReq LVMAVR_DispReq;
SIG_GROUP_ 2150244352 EngyCnsHsGrphDspDtVal 1 : ECHGDDV_Col10 ECHGDDV_Col9 ECHGDDV_Col8 ECHGDDV_Col7 ECHGDDV_Col6 ECHGDDV_Col5 ECHGDDV_Col4 ECHGDDV_Col3 ECHGDDV_Col2 ECHGDDV_Col1 ECHGDDV_EngyConsAvg;
SIG_GROUP_ 2154397696 CrShrngPhStat 1 : CSPS_CertfctId CSPS_ConnStat CSPS_RspVerf;
SIG_GROUP_ 2154381312 CrShrngZnStat 1 : CSZS_FrntCmptZnMbDevStat CSZS_RrCmptZnMbDevStat CSZS_FrntExtrZnMbDevStat CSZS_RrExtrZnMbDevStat CSZS_WlcmZnMbDevStat CSZS_IntrZnMbDevStat CSZS_PassEntyZnMbDevStat CSZS_DrEntyZnMbDevStat;
SIG_GROUP_ 2152153088 RRStCtlDispStat 1 : RRSCDS_UnsdRsrvd RRSCDS_DispReq RRSCDS_DispSz RRSCDS_CshLgAdjFdRr RRSCDS_BkCshBlstInOt RRSCDS_CshBlstrInOut RRSCDS_BkBlstrInOut RRSCDS_LmbrUDnFdRr RRSCDS_LmbrFwdRr RRSCDS_LmbrUpDwn RRSCDS_UprShldrFdRr RRSCDS_HdrstTltFwdRr RRSCDS_HdrstWngInOt RRSCDS_HdrstFdRrUDn RRSCDS_HdrstFwdRrwd RRSCDS_HdrstUpDn RRSCDS_MassgIntsty RRSCDS_MassgTyp RRSCDS_Massg;
SIG_GROUP_ 2152136704 RRStMassgPrty 1 : RRSMP_UnsdRsrvd RRSMP_MaxDispVal RRSMP_Type15 RRSMP_Type14 RRSMP_Type13 RRSMP_Type12 RRSMP_Type11 RRSMP_Type10 RRSMP_Type9 RRSMP_Type8 RRSMP_Type7 RRSMP_Type6 RRSMP_Type5 RRSMP_Type4 RRSMP_Type3 RRSMP_Type2 RRSMP_Type1;
SIG_GROUP_ 2152120320 RRStActPrty 1 : RRSAP_UnsdRsrvd RRSAP_DispSz RRSAP_CshLgthAdjFdRr RRSAP_BkCshBlstrInOut RRSAP_CshBlstrInOut RRSAP_BkBlstrInOut RRSAP_LmbrUpDnFdRr RRSAP_LmbrFwdRr RRSAP_LmbrUpDwn RRSAP_UprShldrFwdRr RRSAP_HdrstTltFwdRr RRSAP_HdrstWngsInOut RRSAP_HdrstUpDnFdRr RRSAP_HdrstFwdRrwd RRSAP_HdrstUpDn RRSAP_Massg;
SIG_GROUP_ 2152103936 LRStCtlDispStat 1 : LRSCDS_UnsdRsrvd LRSCDS_DispReq LRSCDS_DispSz LRSCDS_CshLgAdjFdRr LRSCDS_BkCshBlstInOt LRSCDS_CshBlstrInOut LRSCDS_BkBlstrInOut LRSCDS_LmbrUDnFdRr LRSCDS_LmbrFwdRr LRSCDS_LmbrUpDwn LRSCDS_UprShldrFdRr LRSCDS_HdrstTltFwdRr LRSCDS_HdrstWngInOt LRSCDS_HdrstFdRrUDn LRSCDS_HdrstFwdRrwd LRSCDS_HdrstUpDn LRSCDS_MassgIntsty LRSCDS_MassgTyp LRSCDS_Massg;
SIG_GROUP_ 2152087552 LRStMassgPrty 1 : LRSMP_UnsdRsrvd LRSMP_MaxDispVal LRSMP_Type15 LRSMP_Type14 LRSMP_Type13 LRSMP_Type12 LRSMP_Type11 LRSMP_Type10 LRSMP_Type9 LRSMP_Type8 LRSMP_Type7 LRSMP_Type6 LRSMP_Type5 LRSMP_Type4 LRSMP_Type3 LRSMP_Type2 LRSMP_Type1;
SIG_GROUP_ 2152071168 LRStActPrty 1 : LRSAP_UnsdRsrvd LRSAP_DispSz LRSAP_CshLgthAdjFdRr LRSAP_BkCshBlstrInOut LRSAP_CshBlstrInOut LRSAP_BkBlstrInOut LRSAP_LmbrUpDnFdRr LRSAP_LmbrFwdRr LRSAP_LmbrUpDwn LRSAP_UprShldrFwdRr LRSAP_HdrstTltFwdRr LRSAP_HdrstWngsInOut LRSAP_HdrstUpDnFdRr LRSAP_HdrstFwdRrwd LRSAP_HdrstUpDn LRSAP_Massg;
SIG_GROUP_ 2152628224 OBTCResp 1 : OBTCR_ReqstrID OBTCR_Stat;
SIG_GROUP_ 2152112128 PerfMdVislztnScrnStat 1 : PMVSS_Disps PMVSS_Exhst PMVSS_PsngrSeat PMVSS_DrvrSeat PMVSS_AdptCrsCnt PMVSS_Drvln PMVSS_Susp PMVSS_Strng PMVSS_Trans PMVSS_Eng PMVSS_Snd;
